VERSION "ZCU_CANFD2"

NS_ :

BS_ :

BU_ :  ETC IHU ZCUD ZCUP

BO_ 441 ZcupZCUCANFD2Fr01 : 64 ZCUP
 SG_ AjarChrgLidRearSwitch : 103|2@0+ (1,0) [0|3] "" IHU,ZCUD
 SG_ AjarChrgLidRearSwitch_UB : 144|1@0+ (1,0) [0|1] "" IHU,ZCUD
 SG_ AjarFuelFlapSwitch : 101|2@0+ (1,0) [0|3] "" IHU,ZCUD
 SG_ AjarFuelFlapSwitch_UB : 147|1@0+ (1,0) [0|1] "" IHU,ZCUD
 SG_ CarTiIntForClima : 175|32@0+ (0.1,0.0) [0.0|429496729.5] "s" IHU,ZCUD
 SG_ CarTiIntForClima_UB : 166|1@0+ (1,0) [0|1] "" IHU,ZCUD
 SG_ ClimaCmptSts : 111|3@0+ (1,0) [0|7] "" IHU,ZCUD
 SG_ ClimaCmptSts_UB : 167|1@0+ (1,0) [0|1] "" IHU,ZCUD
 SG_ ClimaCtrlActv : 233|1@0+ (1,0) [0|1] "" IHU
 SG_ ClimaCtrlActv_UB : 232|1@0+ (1,0) [0|1] "" IHU
 SG_ ClimaDefrstSts : 108|1@0+ (1,0) [0|1] "" IHU,ZCUD
 SG_ ClimaDefrstSts_UB : 107|1@0+ (1,0) [0|1] "" IHU,ZCUD
 SG_ ClimaEstimdTForHeat : 231|13@0- (0.1,0.0) [-256.0|255.9] "degC" IHU
 SG_ ClimaEstimdTForHeat_UB : 234|1@0+ (1,0) [0|1] "" IHU
 SG_ ClimaEstimdTForReHeat : 247|13@0- (0.1,0.0) [-256.0|255.9] "degC" IHU
 SG_ ClimaEstimdTForReHeat_UB : 250|1@0+ (1,0) [0|1] "" IHU
 SG_ CmptmtAirTEstimdAtRowFirstLoResl : 207|11@0+ (0.1,-60.0) [-60.0|125.0] "degC" IHU,ZCUD
 SG_ CmptmtAirTEstimdAtRowFirstLoResl_UB : 106|1@0+ (1,0) [0|1] "" IHU,ZCUD
 SG_ CoupldCtrlErrAtRowFirstLe : 263|13@0- (0.1,0.0) [-256.0|255.9] "degC" IHU
 SG_ CoupldCtrlErrAtRowFirstLe_UB : 266|1@0+ (1,0) [0|1] "" IHU
 SG_ CoupldCtrlErrAtRowFirstRi : 279|13@0- (0.1,0.0) [-256.0|255.9] "degC" IHU
 SG_ CoupldCtrlErrAtRowFirstRi_UB : 282|1@0+ (1,0) [0|1] "" IHU
 SG_ CoupldCtrlErrAtRowSecLe : 295|13@0- (0.1,0.0) [-256.0|255.9] "degC" IHU
 SG_ CoupldCtrlErrAtRowSecLe_UB : 298|1@0+ (1,0) [0|1] "" IHU
 SG_ CoupldCtrlErrAtRowSecRi : 311|13@0- (0.1,0.0) [-256.0|255.9] "degC" IHU
 SG_ CoupldCtrlErrAtRowSecRi_UB : 314|1@0+ (1,0) [0|1] "" IHU
 SG_ DoorPass2Swt1DplyHndl : 249|1@0+ (1,0) [0|1] "" IHU
 SG_ DoorPass2Swt1DplyHndl_UB : 248|1@0+ (1,0) [0|1] "" IHU
 SG_ DoorPass2Swt2DplyHndl : 265|1@0+ (1,0) [0|1] "" IHU
 SG_ DoorPass2Swt2DplyHndl_UB : 264|1@0+ (1,0) [0|1] "" IHU
 SG_ DoorPassLatPosn : 223|2@0+ (1,0) [0|3] "" ZCUD
 SG_ DoorPassLatPosn_UB : 208|1@0+ (1,0) [0|1] "" ZCUD
 SG_ DoorPassRe2Sw1DplyHndl : 219|1@0+ (1,0) [0|1] "" IHU
 SG_ DoorPassRe2Sw1DplyHndl_UB : 218|1@0+ (1,0) [0|1] "" IHU
 SG_ DoorPassRe2Sw2DplyHndl : 217|1@0+ (1,0) [0|1] "" IHU
 SG_ DoorPassRe2Sw2DplyHndl_UB : 216|1@0+ (1,0) [0|1] "" IHU
 SG_ DrvrSeatHeatgPwrAllwd : 23|8@0+ (1.0,0.0) [0.0|255.0] "Unitless" IHU,ZCUD
 SG_ DrvrSeatHeatgPwrAllwd_UB : 145|1@0+ (1,0) [0|1] "" IHU,ZCUD
 SG_ DrvrSeatVentnPwrAllwd : 31|8@0+ (1.0,0.0) [0.0|255.0] "Unitless" IHU,ZCUD
 SG_ DrvrSeatVentnPwrAllwd_UB : 146|1@0+ (1,0) [0|1] "" IHU,ZCUD
 SG_ EngSpdIncIdleForClima : 99|1@0+ (1,0) [0|1] "" IHU,ZCUD
 SG_ EngSpdIncIdleForClima_UB : 152|1@0+ (1,0) [0|1] "" IHU,ZCUD
 SG_ FltOfReRegPlateLamp : 98|1@0+ (1,0) [0|1] "" IHU,ZCUD
 SG_ FltOfReRegPlateLamp_UB : 153|1@0+ (1,0) [0|1] "" IHU,ZCUD
 SG_ FragCh1Id : 39|8@0+ (1.0,0.0) [0.0|255.0] "Unitless" IHU
 SG_ FragCh1Id_UB : 154|1@0+ (1,0) [0|1] "" IHU
 SG_ FragCh2Id : 47|8@0+ (1.0,0.0) [0.0|255.0] "Unitless" IHU
 SG_ FragCh2Id_UB : 155|1@0+ (1,0) [0|1] "" IHU
 SG_ FragCh3Id : 55|8@0+ (1.0,0.0) [0.0|255.0] "Unitless" IHU
 SG_ FragCh3Id_UB : 156|1@0+ (1,0) [0|1] "" IHU
 SG_ FragCh4Id : 63|8@0+ (1.0,0.0) [0.0|255.0] "Unitless" IHU
 SG_ FragCh4Id_UB : 157|1@0+ (1,0) [0|1] "" IHU
 SG_ FragCh5Id : 71|8@0+ (1.0,0.0) [0.0|255.0] "Unitless" IHU
 SG_ FragCh5Id_UB : 158|1@0+ (1,0) [0|1] "" IHU
 SG_ HvEgyDesForClima : 79|8@0+ (50.0,0.0) [0.0|12750.0] "Wh" IHU,ZCUD
 SG_ HvEgyDesForClima_UB : 159|1@0+ (1,0) [0|1] "" IHU,ZCUD
 SG_ IceBreakDoorPassActv : 281|1@0+ (1,0) [0|1] "" IHU
 SG_ IceBreakDoorPassActv_UB : 280|1@0+ (1,0) [0|1] "" IHU
 SG_ MirrAtPassInMovmt : 97|1@0+ (1,0) [0|1] "" IHU
 SG_ MirrAtPassInMovmt_UB : 160|1@0+ (1,0) [0|1] "" IHU
 SG_ PassSeatCushDownPosPerc_UB : 312|1@0+ (1,0) [0|1] "" IHU
 SG_ PassSeatCushDownPosPercSeatPosPerc : 327|10@0+ (0.1,0.0) [0.0|100.0] "%" IHU
 SG_ PassSeatCushDownPosPercSeatPosQf : 333|2@0+ (1,0) [0|3] "" IHU
 SG_ PassSeatFoldFailFb : 331|3@0+ (1.0,0.0) [0.0|7.0] "Unitless" IHU
 SG_ PassSeatFoldFailFb_UB : 328|1@0+ (1,0) [0|1] "" IHU
 SG_ PassSeatPosPerc_UB : 162|1@0+ (1,0) [0|1] "" IHU,ZCUD
 SG_ PassSeatPosPercSeatPosFrntHeiPerc : 119|10@0+ (0.1,0.0) [0.0|100.0] "%" IHU,ZCUD
 SG_ PassSeatPosPercSeatPosFrntHeiQF : 125|2@0+ (1,0) [0|3] "" IHU,ZCUD
 SG_ PassSeatPosPercSeatPosHeiPerc : 121|10@0+ (0.1,0.0) [0.0|100.0] "%" IHU,ZCUD
 SG_ PassSeatPosPercSeatPosHeiQF : 123|2@0+ (1,0) [0|3] "" IHU,ZCUD
 SG_ PassSeatPosPercSeatPosSldPerc : 143|10@0+ (0.1,0.0) [0.0|100.0] "%" IHU,ZCUD
 SG_ PassSeatPosPercSeatPosSldQF : 149|2@0+ (1,0) [0|3] "" IHU,ZCUD
 SG_ SeatBackAngleRowFirstPass : 87|8@0+ (1.0,0.0) [0.0|180.0] "Deg" IHU
 SG_ SeatBackAngleRowFirstPass_UB : 163|1@0+ (1,0) [0|1] "" IHU
 SG_ SeatOccptAtRowSecPasSide2 : 212|2@0+ (1,0) [0|3] "" IHU,ZCUD
 SG_ SeatOccptAtRowSecPasSide2_UB : 105|1@0+ (1,0) [0|1] "" IHU,ZCUD
 SG_ SeatOccptAtRowSecPasSideSnsSts2 : 210|2@0+ (1,0) [0|3] "" IHU,ZCUD
 SG_ SeatOccptAtRowSecPasSideSnsSts2_UB : 104|1@0+ (1,0) [0|1] "" IHU,ZCUD
 SG_ SteerWhlHeatgDurgClima : 96|1@0+ (1,0) [0|1] "" IHU,ZCUD
 SG_ SteerWhlHeatgDurgClima_UB : 164|1@0+ (1,0) [0|1] "" IHU,ZCUD
 SG_ SteerWhlHeatgPwrAllwd : 95|8@0+ (1.0,0.0) [0.0|255.0] "Unitless" IHU,ZCUD
 SG_ SteerWhlHeatgPwrAllwd_UB : 165|1@0+ (1,0) [0|1] "" IHU,ZCUD

BO_ 801 ZcupZCUCANFD2Fr02 : 64 ZCUP
 SG_ AmbTEstimd_UB : 8|1@0+ (1,0) [0|1] "" IHU,ZCUD
 SG_ AmbTEstimdAmbTEstimd : 7|11@0+ (0.1,-70.0) [-70.0|134.70000000000002] "degC" IHU,ZCUD
 SG_ AmbTEstimdQf : 12|1@0+ (1,0) [0|1] "" IHU,ZCUD
 SG_ ClimaOvrHeatPrtSts : 11|1@0+ (1,0) [0|1] "" IHU,ZCUD
 SG_ ClimaOvrHeatPrtSts_UB : 9|1@0+ (1,0) [0|1] "" IHU,ZCUD
 SG_ CmptmtAirTEstimdExtd_UB : 10|1@0+ (1,0) [0|1] "" IHU,ZCUD
 SG_ CmptmtAirTEstimdExtdComptmtT : 23|11@0+ (0.1,-60.0) [-60.0|125.0] "degC" IHU,ZCUD
 SG_ CmptmtAirTEstimdExtdQlyFlg : 28|2@0+ (1,0) [0|3] "" IHU,ZCUD

BO_ 520 ZcupZCUCANFD2Fr03 : 64 ZCUP
 SG_ AmbTRawAtPassSide_UB : 10|1@0+ (1,0) [0|1] "" IHU,ZCUD
 SG_ AmbTRawAtPassSideAmbTVal : 7|11@0+ (0.1,-70.0) [-70.0|134.70000000000002] "degC" IHU,ZCUD
 SG_ AmbTRawAtPassSideQly : 12|2@0+ (1,0) [0|3] "" IHU,ZCUD
 SG_ AmbTURawAtPassSide : 23|12@0+ (0.1,-70.0) [-70.0|339.5] "degC" IHU,ZCUD
 SG_ AmbTURawAtPassSide_UB : 9|1@0+ (1,0) [0|1] "" IHU,ZCUD
 SG_ HvacEvaprTSpFrnt : 39|8@0+ (0.1,-5.0) [-5.0|20.0] "Unitless" IHU,ZCUD
 SG_ HvacEvaprTSpFrnt_UB : 8|1@0+ (1,0) [0|1] "" IHU,ZCUD
 SG_ RlyCmftForClimaReq : 47|1@0+ (1,0) [0|1] "" IHU,ZCUD
 SG_ RlyCmftForClimaReq_UB : 46|1@0+ (1,0) [0|1] "" IHU,ZCUD
 SG_ RlyCrashForClimaReq : 45|1@0+ (1,0) [0|1] "" IHU,ZCUD
 SG_ RlyCrashForClimaReq_UB : 44|1@0+ (1,0) [0|1] "" IHU,ZCUD

BO_ 58 ZcupZCUCANFD2Fr04 : 64 ZCUP
 SG_ DoorPassOpenLowReqOutdSwt1 : 7|2@0+ (1,0) [0|3] "" ZCUD
 SG_ DoorPassOpenLowReqOutdSwt1_UB : 15|1@0+ (1,0) [0|1] "" ZCUD
 SG_ DoorPassOpenReqInsdSwt1 : 5|2@0+ (1,0) [0|3] "" ZCUD
 SG_ DoorPassOpenReqInsdSwt1_UB : 14|1@0+ (1,0) [0|1] "" ZCUD
 SG_ DoorPassReCinhIntFailInf_UB : 13|1@0+ (1,0) [0|1] "" ZCUD
 SG_ DoorPassReCinhIntFailInfCinchFlt1 : 3|1@0+ (1,0) [0|1] "" ZCUD
 SG_ DoorPassReCinhIntFailInfCinchRestFlt : 2|1@0+ (1,0) [0|1] "" ZCUD
 SG_ DoorPassReLatPosn : 1|2@0+ (1,0) [0|3] "" ZCUD
 SG_ DoorPassReLatPosn_UB : 12|1@0+ (1,0) [0|1] "" ZCUD
 SG_ DoorPassReOpenLowReqOutdSwt1 : 23|2@0+ (1,0) [0|3] "" ZCUD
 SG_ DoorPassReOpenLowReqOutdSwt1_UB : 11|1@0+ (1,0) [0|1] "" ZCUD
 SG_ DoorPassReOpenReqInsdSwt1 : 21|2@0+ (1,0) [0|3] "" ZCUD
 SG_ DoorPassReOpenReqInsdSwt1_UB : 10|1@0+ (1,0) [0|1] "" ZCUD
 SG_ DoorPassReRelsFail_UB : 28|1@0+ (1,0) [0|1] "" ZCUD
 SG_ DoorPassReRelsFailCinchOverTimed : 31|1@0+ (1,0) [0|1] "" ZCUD
 SG_ DoorPassReRelsFailFailure1 : 30|1@0+ (1,0) [0|1] "" ZCUD
 SG_ DoorPassReRelsFailMechRels : 29|1@0+ (1,0) [0|1] "" ZCUD
 SG_ DoorRiReLatPosn : 19|2@0+ (1,0) [0|3] "" ZCUD
 SG_ DoorRiReLatPosn_UB : 9|1@0+ (1,0) [0|1] "" ZCUD
 SG_ DoorRiReOpenLowReqOutdSwt1 : 17|2@0+ (1,0) [0|3] "" ZCUD
 SG_ DoorRiReOpenLowReqOutdSwt1_UB : 8|1@0+ (1,0) [0|1] "" ZCUD
 SG_ DoorRiReOpenReqInsdSwt1 : 27|2@0+ (1,0) [0|3] "" ZCUD
 SG_ DoorRiReOpenReqInsdSwt1_UB : 25|1@0+ (1,0) [0|1] "" ZCUD
 SG_ IceBreakDoorPassReActv : 39|1@0+ (1,0) [0|1] "" ZCUD
 SG_ IceBreakDoorPassReActv_UB : 24|1@0+ (1,0) [0|1] "" ZCUD

BO_ 310 ZcupZCUCANFD2Fr05 : 64 ZCUP
 SG_ AutDemstOperSts : 35|1@0+ (1,0) [0|1] "" IHU
 SG_ AutDemstOperSts_UB : 56|1@0+ (1,0) [0|1] "" IHU
 SG_ ChdLockPassReSts : 39|2@0+ (1,0) [0|3] "" IHU,ZCUD
 SG_ ChdLockPassReSts_UB : 57|1@0+ (1,0) [0|1] "" IHU,ZCUD
 SG_ ChdLockRightSts : 37|2@0+ (1,0) [0|3] "" IHU,ZCUD
 SG_ ChdLockRightSts_UB : 58|1@0+ (1,0) [0|1] "" IHU,ZCUD
 SG_ ChrgLidDCorAcDctSwtReq : 34|1@0+ (1,0) [0|1] "" IHU,ZCUD
 SG_ ChrgLidDCorAcDctSwtReq_UB : 59|1@0+ (1,0) [0|1] "" IHU,ZCUD
 SG_ CinhPassReSts : 211|1@0+ (1,0) [0|1] "" ZCUD
 SG_ CinhPassReSts_UB : 210|1@0+ (1,0) [0|1] "" ZCUD
 SG_ CinhPassReSwt : 209|1@0+ (1,0) [0|1] "" ZCUD
 SG_ CinhPassReSwt_UB : 208|1@0+ (1,0) [0|1] "" ZCUD
 SG_ CinhPassSts : 111|1@0+ (1,0) [0|1] "" ZCUD
 SG_ CinhPassSts_UB : 110|1@0+ (1,0) [0|1] "" ZCUD
 SG_ CinhPassSwt : 234|1@0+ (1,0) [0|1] "" ZCUD
 SG_ CinhPassSwt_UB : 233|1@0+ (1,0) [0|1] "" ZCUD
 SG_ ClimaTiOfEnd : 7|32@0+ (0.1,0.0) [0.0|429496729.5] "s" IHU,ZCUD
 SG_ ClimaTiOfEnd_UB : 60|1@0+ (1,0) [0|1] "" IHU,ZCUD
 SG_ CmptmtTFrnt_UB : 72|1@0+ (1,0) [0|1] "" IHU,ZCUD
 SG_ CmptmtTFrntCmptmtTFrnt : 71|11@0+ (0.1,-60.0) [-60.0|125.0] "degC" IHU,ZCUD
 SG_ CmptmtTFrntFanForCmptmtTRunng : 76|1@0+ (1,0) [0|1] "" IHU,ZCUD
 SG_ CmptmtTFrntQf : 75|2@0+ (1,0) [0|3] "" IHU,ZCUD
 SG_ DoorPassReHndlSts : 47|3@0+ (1,0) [0|7] "" IHU,ZCUD
 SG_ DoorPassReHndlSts_UB : 73|1@0+ (1,0) [0|1] "" IHU,ZCUD
 SG_ EvaprTFrnt_UB : 225|1@0+ (1,0) [0|1] "" IHU,ZCUD
 SG_ EvaprTFrntEvaprTFrnt : 223|13@0- (0.1,0.0) [-256.0|255.9] "degC" IHU,ZCUD
 SG_ EvaprTFrntEvaprTQf : 226|1@0+ (1,0) [0|1] "" IHU,ZCUD
 SG_ FltOfBeamHiPass : 33|1@0+ (1,0) [0|1] "" IHU,ZCUD
 SG_ FltOfBeamHiPass_UB : 88|1@0+ (1,0) [0|1] "" IHU,ZCUD
 SG_ FltOfBeamLoPass : 32|1@0+ (1,0) [0|1] "" IHU,ZCUD
 SG_ FltOfBeamLoPass_UB : 89|1@0+ (1,0) [0|1] "" IHU,ZCUD
 SG_ FltOfDaytiRunngLampPass : 44|1@0+ (1,0) [0|1] "" IHU,ZCUD
 SG_ FltOfDaytiRunngLampPass_UB : 96|1@0+ (1,0) [0|1] "" IHU,ZCUD
 SG_ FltOfFrntFogLampPass : 43|1@0+ (1,0) [0|1] "" IHU,ZCUD
 SG_ FltOfFrntFogLampPass_UB : 97|1@0+ (1,0) [0|1] "" IHU,ZCUD
 SG_ FltOfFrntPosnLampPass : 42|1@0+ (1,0) [0|1] "" IHU,ZCUD
 SG_ FltOfFrntPosnLampPass_UB : 98|1@0+ (1,0) [0|1] "" IHU,ZCUD
 SG_ FltOfReFogLampDrv : 41|1@0+ (1,0) [0|1] "" IHU,ZCUD
 SG_ FltOfReFogLampDrv_UB : 99|1@0+ (1,0) [0|1] "" IHU,ZCUD
 SG_ FltOfRePosnLampPass : 40|1@0+ (1,0) [0|1] "" IHU,ZCUD
 SG_ FltOfRePosnLampPass_UB : 100|1@0+ (1,0) [0|1] "" IHU,ZCUD
 SG_ FltOfRvsgLampPass : 50|1@0+ (1,0) [0|1] "" IHU,ZCUD
 SG_ FltOfRvsgLampPass_UB : 101|1@0+ (1,0) [0|1] "" IHU,ZCUD
 SG_ HvacCoolgEnaRe : 49|1@0+ (1,0) [0|1] "" IHU,ZCUD
 SG_ HvacCoolgEnaRe_UB : 102|1@0+ (1,0) [0|1] "" IHU,ZCUD
 SG_ HvahAirTEstmd_UB : 103|1@0+ (1,0) [0|1] "" IHU,ZCUD
 SG_ HvahAirTEstmdEvaprTFrnt : 87|13@0- (0.1,0.0) [-256.0|255.9] "degC" IHU,ZCUD
 SG_ HvahAirTEstmdEvaprTQf : 90|1@0+ (1,0) [0|1] "" IHU,ZCUD
 SG_ IceBreakDoorRiReActv : 224|1@0+ (1,0) [0|1] "" ZCUD
 SG_ IceBreakDoorRiReActv_UB : 239|1@0+ (1,0) [0|1] "" ZCUD
 SG_ IntPm25StsFrmClima : 52|2@0+ (1,0) [0|3] "" IHU
 SG_ IntPm25StsFrmClima_UB : 104|1@0+ (1,0) [0|1] "" IHU
 SG_ MirrDwnStsAtPass : 55|3@0+ (1,0) [0|7] "" IHU,ZCUD
 SG_ MirrDwnStsAtPass_UB : 105|1@0+ (1,0) [0|1] "" IHU,ZCUD
 SG_ MirrPosnToSetTarPosnAtPass_UB : 109|1@0+ (1,0) [0|1] "" IHU
 SG_ MirrPosnToSetTarPosnAtPassMirrPosnAdjCldLeRi : 119|8@0+ (1.0,0.0) [0.0|180.0] "Deg" IHU
 SG_ MirrPosnToSetTarPosnAtPassMirrPosnAdjCldUpDwn : 127|8@0+ (1.0,0.0) [0.0|180.0] "Deg" IHU
 SG_ OpenPassReSwt : 242|1@0+ (1,0) [0|1] "" ZCUD
 SG_ OpenPassReSwt_UB : 241|1@0+ (1,0) [0|1] "" ZCUD
 SG_ OpenPassSwt : 240|1@0+ (1,0) [0|1] "" ZCUD
 SG_ OpenPassSwt_UB : 255|1@0+ (1,0) [0|1] "" ZCUD
 SG_ PassSeatBtnPsd : 48|1@0+ (1,0) [0|1] "" IHU
 SG_ PassSeatBtnPsd_UB : 106|1@0+ (1,0) [0|1] "" IHU
 SG_ PassSeatFoldSts : 270|3@0+ (1,0) [0|7] "" IHU,ZCUD
 SG_ PassSeatFoldSts_UB : 267|1@0+ (1,0) [0|1] "" IHU,ZCUD
 SG_ PassSeatInAutMovmt : 61|1@0+ (1,0) [0|1] "" IHU,ZCUD
 SG_ PassSeatInAutMovmt_UB : 107|1@0+ (1,0) [0|1] "" IHU,ZCUD
 SG_ PassSeatPosFrntExtPerc_UB : 252|1@0+ (1,0) [0|1] "" IHU
 SG_ PassSeatPosFrntExtPercSeatPosPerc : 249|10@0+ (0.1,0.0) [0.0|100.0] "%" IHU
 SG_ PassSeatPosFrntExtPercSeatPosQf : 251|2@0+ (1,0) [0|3] "" IHU
 SG_ PawlPassReSwt : 238|1@0+ (1,0) [0|1] "" ZCUD
 SG_ PawlPassReSwt_UB : 237|1@0+ (1,0) [0|1] "" ZCUD
 SG_ PawlPassSwt : 236|1@0+ (1,0) [0|1] "" ZCUD
 SG_ PawlPassSwt_UB : 235|1@0+ (1,0) [0|1] "" ZCUD
 SG_ SecRowLeSeatHeatgPwrAllwd : 135|8@0+ (1.0,0.0) [0.0|255.0] "Unitless" ZCUD
 SG_ SecRowLeSeatHeatgPwrAllwd_UB : 199|1@0+ (1,0) [0|1] "" ZCUD
 SG_ SecRowLeSeatVentnPwrAllwd : 143|8@0+ (1.0,0.0) [0.0|255.0] "Unitless" ZCUD
 SG_ SecRowLeSeatVentnPwrAllwd_UB : 198|1@0+ (1,0) [0|1] "" ZCUD
 SG_ SecRowRiSeatHeatgPwrAllwd : 151|8@0+ (1.0,0.0) [0.0|255.0] "Unitless" ZCUD
 SG_ SecRowRiSeatHeatgPwrAllwd_UB : 197|1@0+ (1,0) [0|1] "" ZCUD
 SG_ SecRowRiSeatVentnPwrAllwd : 159|8@0+ (1.0,0.0) [0.0|255.0] "Unitless" ZCUD
 SG_ SecRowRiSeatVentnPwrAllwd_UB : 196|1@0+ (1,0) [0|1] "" ZCUD
 SG_ ShortDropWinPassSts : 247|2@0+ (1,0) [0|3] "" ZCUD
 SG_ ShortDropWinPassSts_UB : 232|1@0+ (1,0) [0|1] "" ZCUD
 SG_ ShortDropWinReRiSts : 245|2@0+ (1,0) [0|3] "" ZCUD
 SG_ ShortDropWinReRiSts_UB : 243|1@0+ (1,0) [0|1] "" ZCUD
 SG_ ThrdRowLeSeatHeatgPwrAllwd : 167|8@0+ (1.0,0.0) [0.0|255.0] "Unitless" ZCUD
 SG_ ThrdRowLeSeatHeatgPwrAllwd_UB : 195|1@0+ (1,0) [0|1] "" ZCUD
 SG_ ThrdRowLeSeatVentnPwrAllwd : 175|8@0+ (1.0,0.0) [0.0|255.0] "Unitless" ZCUD
 SG_ ThrdRowLeSeatVentnPwrAllwd_UB : 194|1@0+ (1,0) [0|1] "" ZCUD
 SG_ ThrdRowRiSeatHeatgPwrAllwd : 183|8@0+ (1.0,0.0) [0.0|255.0] "Unitless" ZCUD
 SG_ ThrdRowRiSeatHeatgPwrAllwd_UB : 193|1@0+ (1,0) [0|1] "" ZCUD
 SG_ ThrdRowRiSeatVentnPwrAllwd : 191|8@0+ (1.0,0.0) [0.0|255.0] "Unitless" ZCUD
 SG_ ThrdRowRiSeatVentnPwrAllwd_UB : 192|1@0+ (1,0) [0|1] "" ZCUD
 SG_ WinDsblPassReSts : 201|1@0+ (1,0) [0|1] "" IHU,ZCUD
 SG_ WinDsblPassReSts_UB : 200|1@0+ (1,0) [0|1] "" IHU,ZCUD
 SG_ WinDsblRightSts : 215|1@0+ (1,0) [0|1] "" IHU,ZCUD
 SG_ WinDsblRightSts_UB : 214|1@0+ (1,0) [0|1] "" IHU,ZCUD
 SG_ WinFailrStsAtPassRe : 213|1@0+ (1,0) [0|1] "" IHU,ZCUD
 SG_ WinFailrStsAtPassRe_UB : 212|1@0+ (1,0) [0|1] "" IHU,ZCUD
 SG_ WinPosnStsAtPassRe : 207|5@0+ (1,0) [0|31] "" IHU,ZCUD
 SG_ WinPosnStsAtPassRe_UB : 202|1@0+ (1,0) [0|1] "" IHU,ZCUD

BO_ 1184 ZcupZCUCANFD2Fr06 : 64 ZCUP
 SG_ CmptmtIntrMtrlTEstimd_UB : 252|1@0+ (1,0) [0|1] "" IHU
 SG_ CmptmtIntrMtrlTEstimdMtrlSnsrT : 127|13@0- (0.1,0.0) [-256.0|255.9] "degC" IHU
 SG_ CmptmtIntrMtrlTEstimdMtrlSnsrTQly2 : 130|2@0+ (1,0) [0|3] "" IHU
 SG_ EgyDesForClima : 103|7@0+ (1.0,0.0) [0.0|127.0] "Wh" IHU,ZCUD
 SG_ EgyDesForClima_UB : 96|1@0+ (1,0) [0|1] "" IHU,ZCUD
 SG_ ElecVentnMotPwrCnsAct : 199|10@0+ (0.1,0.0) [0.0|102.30000000000001] "W" IHU
 SG_ ElecVentnMotPwrCnsAct_UB : 253|1@0+ (1,0) [0|1] "" IHU
 SG_ ElecVentnMotPwrCnsDes : 247|10@0+ (0.1,0.0) [0.0|102.30000000000001] "W" IHU
 SG_ ElecVentnMotPwrCnsDes_UB : 274|1@0+ (1,0) [0|1] "" IHU
 SG_ HvacDefrstFlapActlPosn : 249|10@0+ (0.1,0.0) [0.0|100.0] "%" IHU
 SG_ HvacDefrstFlapActlPosn_UB : 275|1@0+ (1,0) [0|1] "" IHU
 SG_ HvacFanSet2HvacFanSpd2 : 39|8@0+ (1.0,0.0) [0.0|255.0] "Unitless" IHU
 SG_ HvacFanSet2HvacFanSpd2_UB : 276|1@0+ (1,0) [0|1] "" IHU
 SG_ HvacHeatElmAirMFlowEstimd : 271|10@0+ (1.0,0.0) [0.0|1000.0] "Kg / h" IHU,ZCUD
 SG_ HvacHeatElmAirMFlowEstimd_UB : 277|1@0+ (1,0) [0|1] "" IHU,ZCUD
 SG_ HvacModFlapActlPosnFrstRowLe : 153|10@0+ (0.1,0.0) [0.0|100.0] "%" IHU
 SG_ HvacModFlapActlPosnFrstRowLe_UB : 299|1@0+ (1,0) [0|1] "" IHU
 SG_ HvacModFlapActlPosnFrstRowRi : 273|10@0+ (0.1,0.0) [0.0|100.0] "%" IHU
 SG_ HvacModFlapActlPosnFrstRowRi_UB : 300|1@0+ (1,0) [0|1] "" IHU
 SG_ HvacModFlapActlPosnSecRowLe : 295|10@0+ (0.1,0.0) [0.0|100.0] "%" IHU
 SG_ HvacModFlapActlPosnSecRowLe_UB : 301|1@0+ (1,0) [0|1] "" IHU
 SG_ HvacModFlapActlPosnSecRowRi : 297|10@0+ (0.1,0.0) [0.0|100.0] "%" IHU
 SG_ HvacModFlapActlPosnSecRowRi_UB : 322|1@0+ (1,0) [0|1] "" IHU
 SG_ HvacOsaFlapActlPosn : 319|10@0+ (0.1,0.0) [0.0|100.0] "%" IHU
 SG_ HvacOsaFlapActlPosn_UB : 325|1@0+ (1,0) [0|1] "" IHU
 SG_ HvacRecFlapActlPosn : 321|10@0+ (0.1,0.0) [0.0|100.0] "%" IHU
 SG_ HvacRecFlapActlPosn_UB : 323|1@0+ (1,0) [0|1] "" IHU
 SG_ OutdAirQly_UB : 324|1@0+ (1,0) [0|1] "" IHU
 SG_ OutdAirQlyOutdAirQly : 95|2@0+ (1,0) [0|3] "" IHU
 SG_ OutdAirQlyQf : 93|1@0+ (1,0) [0|1] "" IHU
 SG_ OutdPm25StsFrmClima : 89|2@0+ (1,0) [0|3] "" IHU
 SG_ OutdPm25StsFrmClima_UB : 336|1@0+ (1,0) [0|1] "" IHU
 SG_ PassSeatHeatgActlPwrCns : 47|8@0+ (1.0,0.0) [0.0|255.0] "Unitless" IHU
 SG_ PassSeatHeatgActlPwrCns_UB : 338|1@0+ (1,0) [0|1] "" IHU
 SG_ PassSeatHeatgDesPwrCns : 55|8@0+ (1.0,0.0) [0.0|255.0] "Unitless" IHU
 SG_ PassSeatHeatgDesPwrCns_UB : 339|1@0+ (1,0) [0|1] "" IHU
 SG_ PassSeatHeatgPwrAllwd : 63|8@0+ (1.0,0.0) [0.0|255.0] "Unitless" IHU
 SG_ PassSeatHeatgPwrAllwd_UB : 340|1@0+ (1,0) [0|1] "" IHU
 SG_ PassSeatVentnActlPwrCns : 71|8@0+ (1.0,0.0) [0.0|255.0] "Unitless" IHU
 SG_ PassSeatVentnActlPwrCns_UB : 341|1@0+ (1,0) [0|1] "" IHU
 SG_ PassSeatVentnDesPwrCns : 79|8@0+ (1.0,0.0) [0.0|255.0] "Unitless" IHU
 SG_ PassSeatVentnDesPwrCns_UB : 342|1@0+ (1,0) [0|1] "" IHU
 SG_ PassSeatVentnPwrAllwd : 87|8@0+ (1.0,0.0) [0.0|255.0] "Unitless" IHU
 SG_ PassSeatVentnPwrAllwd_UB : 343|1@0+ (1,0) [0|1] "" IHU
 SG_ PwrAllwdForElecAirVentn : 223|10@0+ (0.1,0.0) [0.0|102.30000000000001] "W" IHU
 SG_ PwrAllwdForElecAirVentn_UB : 344|1@0+ (1,0) [0|1] "" IHU
 SG_ SunDataAzi : 128|9@0+ (1.0,0.0) [0.0|511.0] "Unitless" IHU
 SG_ SunDataAzi_UB : 345|1@0+ (1,0) [0|1] "" IHU
 SG_ SunDataElevn : 178|11@0+ (0.1,-90.0) [-90.0|90.0] "Deg" IHU
 SG_ SunDataElevn_UB : 346|1@0+ (1,0) [0|1] "" IHU
 SG_ TgtHvacAirTForRowFirstLe : 111|13@0- (0.1,0.0) [-256.0|255.9] "degC" IHU
 SG_ TgtHvacAirTForRowFirstLe_UB : 347|1@0+ (1,0) [0|1] "" IHU
 SG_ TgtHvacAirTForRowFirstRi : 175|13@0- (0.1,0.0) [-256.0|255.9] "degC" IHU
 SG_ TgtHvacAirTForRowFirstRi_UB : 348|1@0+ (1,0) [0|1] "" IHU
 SG_ TgtHvacAirTForRowSecLe : 204|13@0- (0.1,0.0) [-256.0|255.9] "degC" IHU
 SG_ TgtHvacAirTForRowSecLe_UB : 205|1@0+ (1,0) [0|1] "" IHU
 SG_ TgtHvacAirTForRowSecRi : 228|13@0- (0.1,0.0) [-256.0|255.9] "degC" IHU
 SG_ TgtHvacAirTForRowSecRi_UB : 229|1@0+ (1,0) [0|1] "" IHU

BO_ 600 ZcupZCUCANFD2Fr07 : 64 ZCUP
 SG_ CcmElecAirDirCrtlReqDrvrLePosX : 23|8@0+ (1.0,0.0) [0.0|255.0] "Unitless" IHU
 SG_ CcmElecAirDirCrtlReqDrvrLePosX_UB : 144|1@0+ (1,0) [0|1] "" IHU
 SG_ CcmElecAirDirCrtlReqDrvrLePosY : 31|8@0+ (1.0,0.0) [0.0|255.0] "Unitless" IHU
 SG_ CcmElecAirDirCrtlReqDrvrLePosY_UB : 145|1@0+ (1,0) [0|1] "" IHU
 SG_ CcmElecAirDirCrtlReqDrvrRiPosX : 39|8@0+ (1.0,0.0) [0.0|255.0] "Unitless" IHU
 SG_ CcmElecAirDirCrtlReqDrvrRiPosX_UB : 146|1@0+ (1,0) [0|1] "" IHU
 SG_ CcmElecAirDirCrtlReqDrvrRiPosY : 47|8@0+ (1.0,0.0) [0.0|255.0] "Unitless" IHU
 SG_ CcmElecAirDirCrtlReqDrvrRiPosY_UB : 147|1@0+ (1,0) [0|1] "" IHU
 SG_ CcmElecAirDirCrtlReqPassLePosX : 55|8@0+ (1.0,0.0) [0.0|255.0] "Unitless" IHU
 SG_ CcmElecAirDirCrtlReqPassLePosX_UB : 148|1@0+ (1,0) [0|1] "" IHU
 SG_ CcmElecAirDirCrtlReqPassLePosY : 63|8@0+ (1.0,0.0) [0.0|255.0] "Unitless" IHU
 SG_ CcmElecAirDirCrtlReqPassLePosY_UB : 152|1@0+ (1,0) [0|1] "" IHU
 SG_ CcmElecAirDirCrtlReqPassRiPosX : 71|8@0+ (1.0,0.0) [0.0|255.0] "Unitless" IHU
 SG_ CcmElecAirDirCrtlReqPassRiPosX_UB : 153|1@0+ (1,0) [0|1] "" IHU
 SG_ CcmElecAirDirCrtlReqPassRiPosY : 79|8@0+ (1.0,0.0) [0.0|255.0] "Unitless" IHU
 SG_ CcmElecAirDirCrtlReqPassRiPosY_UB : 154|1@0+ (1,0) [0|1] "" IHU
 SG_ ClimaActv : 89|1@0+ (1,0) [0|1] "" IHU,ZCUD
 SG_ ClimaActv_UB : 155|1@0+ (1,0) [0|1] "" IHU,ZCUD
 SG_ ElecAirVentnAvlSts : 95|3@0+ (1,0) [0|7] "" IHU
 SG_ ElecAirVentnAvlSts_UB : 157|1@0+ (1,0) [0|1] "" IHU
 SG_ ElecDefrstReq_UB : 158|1@0+ (1,0) [0|1] "" IHU,ZCUD
 SG_ ElecDefrstReqMirrDefrstReq : 92|1@0+ (1,0) [0|1] "" IHU,ZCUD
 SG_ ElecDefrstReqWinDefrstFrntReq : 91|1@0+ (1,0) [0|1] "" IHU,ZCUD
 SG_ ElecDefrstReqWinDefrstReReq : 90|1@0+ (1,0) [0|1] "" IHU,ZCUD
 SG_ EvaprTRe_UB : 159|1@0+ (1,0) [0|1] "" IHU,ZCUD
 SG_ EvaprTReEvaprTFrnt : 103|13@0- (0.1,0.0) [-256.0|255.9] "degC" IHU,ZCUD
 SG_ EvaprTReEvaprTQf : 106|1@0+ (1,0) [0|1] "" IHU,ZCUD
 SG_ FragCh1UseUpWrn : 105|1@0+ (1,0) [0|1] "" IHU
 SG_ FragCh1UseUpWrn_UB : 160|1@0+ (1,0) [0|1] "" IHU
 SG_ FragCh2UseUpWrn : 104|1@0+ (1,0) [0|1] "" IHU
 SG_ FragCh2UseUpWrn_UB : 161|1@0+ (1,0) [0|1] "" IHU
 SG_ FragCh3UseUpWrn : 120|1@0+ (1,0) [0|1] "" IHU
 SG_ FragCh3UseUpWrn_UB : 162|1@0+ (1,0) [0|1] "" IHU
 SG_ FragCh4UseUpWrn : 129|1@0+ (1,0) [0|1] "" IHU
 SG_ FragCh4UseUpWrn_UB : 163|1@0+ (1,0) [0|1] "" IHU
 SG_ FragCh5UseUpWrn : 128|1@0+ (1,0) [0|1] "" IHU
 SG_ FragCh5UseUpWrn_UB : 164|1@0+ (1,0) [0|1] "" IHU
 SG_ FragLvlFrmClima : 135|2@0+ (1,0) [0|3] "" IHU
 SG_ FragLvlFrmClima_UB : 165|1@0+ (1,0) [0|1] "" IHU
 SG_ FragStsFrmClima : 133|2@0+ (1,0) [0|3] "" IHU
 SG_ FragStsFrmClima_UB : 166|1@0+ (1,0) [0|1] "" IHU
 SG_ HvacEvaprTSpRe : 87|8@0+ (0.1,-5.0) [-5.0|20.0] "Unitless" IHU,ZCUD
 SG_ HvacEvaprTSpRe_UB : 167|1@0+ (1,0) [0|1] "" IHU,ZCUD
 SG_ IntPm25HiPopUp : 131|2@0+ (1,0) [0|3] "" IHU
 SG_ IntPm25HiPopUp_UB : 168|1@0+ (1,0) [0|1] "" IHU
 SG_ PassSeatVentAvlSts : 151|3@0+ (1,0) [0|7] "" IHU
 SG_ PassSeatVentAvlSts_UB : 171|1@0+ (1,0) [0|1] "" IHU
 SG_ PrkgClimaWarn : 124|4@0+ (1,0) [0|15] "" IHU
 SG_ PrkgClimaWarn_UB : 173|1@0+ (1,0) [0|1] "" IHU
 SG_ SeatClimaDurgClima_UB : 137|1@0+ (1,0) [0|1] "" IHU,ZCUD
 SG_ SeatClimaDurgClimaHmiSeatHeatgForRowFirstLe : 7|2@0+ (1,0) [0|3] "" IHU,ZCUD
 SG_ SeatClimaDurgClimaHmiSeatHeatgForRowFirstRi : 5|2@0+ (1,0) [0|3] "" IHU,ZCUD
 SG_ SeatClimaDurgClimaHmiSeatHeatgForRowSecLe : 3|2@0+ (1,0) [0|3] "" IHU,ZCUD
 SG_ SeatClimaDurgClimaHmiSeatHeatgForRowSecRi : 1|2@0+ (1,0) [0|3] "" IHU,ZCUD
 SG_ SeatClimaDurgClimaHmiSeatVentnForRowFirstLe : 15|2@0+ (1,0) [0|3] "" IHU,ZCUD
 SG_ SeatClimaDurgClimaHmiSeatVentnForRowFirstRi : 13|2@0+ (1,0) [0|3] "" IHU,ZCUD
 SG_ SeatClimaDurgClimaHmiSeatVentnForRowSecLe : 11|2@0+ (1,0) [0|3] "" IHU,ZCUD
 SG_ SeatClimaDurgClimaHmiSeatVentnForRowSecRi : 9|2@0+ (1,0) [0|3] "" IHU,ZCUD

BO_ 803 ZcupZCUCANFD2Fr08 : 64 ZCUP
 SG_ CcmRollgCntrSts : 39|8@0+ (1.0,0.0) [0.0|255.0] "Unitless" IHU,ZCUD
 SG_ CcmRollgCntrSts_UB : 138|1@0+ (1,0) [0|1] "" IHU,ZCUD
 SG_ ClimaCoolgReqLvl : 196|2@0+ (1,0) [0|3] "" IHU,ZCUD
 SG_ ClimaCoolgReqLvl_UB : 190|1@0+ (1,0) [0|1] "" IHU,ZCUD
 SG_ ClimaHeatgReqLvl : 194|2@0+ (1,0) [0|3] "" IHU,ZCUD
 SG_ ClimaHeatgReqLvl_UB : 192|1@0+ (1,0) [0|1] "" IHU,ZCUD
 SG_ CmptModForHp : 205|3@0+ (1,0) [0|7] "" IHU,ZCUD
 SG_ CmptModForHp_UB : 202|1@0+ (1,0) [0|1] "" IHU,ZCUD
 SG_ CmptmtTRe_UB : 140|1@0+ (1,0) [0|1] "" IHU,ZCUD
 SG_ CmptmtTReCmptmtTFrnt : 71|11@0+ (0.1,-60.0) [-60.0|125.0] "degC" IHU,ZCUD
 SG_ CmptmtTReCmptmtTFrntQf : 76|2@0+ (1,0) [0|3] "" IHU,ZCUD
 SG_ CmptmtTReFanForCmptmtTRunng : 74|1@0+ (1,0) [0|1] "" IHU,ZCUD
 SG_ DvlpFrameForCCM_UB : 200|1@0+ (1,0) [0|1] "" IHU,ZCUD
 SG_ DvlpFrameForCCMByte0 : 215|8@0+ (1.0,0.0) [0.0|255.0] "Unitless" IHU,ZCUD
 SG_ DvlpFrameForCCMByte1 : 223|8@0+ (1.0,0.0) [0.0|255.0] "Unitless" IHU,ZCUD
 SG_ DvlpFrameForCCMByte2 : 231|8@0+ (1.0,0.0) [0.0|255.0] "Unitless" IHU,ZCUD
 SG_ DvlpFrameForCCMByte3 : 239|8@0+ (1.0,0.0) [0.0|255.0] "Unitless" IHU,ZCUD
 SG_ DvlpFrameForCCMByte4 : 247|8@0+ (1.0,0.0) [0.0|255.0] "Unitless" IHU,ZCUD
 SG_ DvlpFrameForCCMByte5 : 255|8@0+ (1.0,0.0) [0.0|255.0] "Unitless" IHU,ZCUD
 SG_ DvlpFrameForCCMByte6 : 263|8@0+ (1.0,0.0) [0.0|255.0] "Unitless" IHU,ZCUD
 SG_ DvlpFrameForCCMByte7 : 271|8@0+ (1.0,0.0) [0.0|255.0] "Unitless" IHU,ZCUD
 SG_ FrntHvacBlowerSts : 279|2@0+ (1,0) [0|3] "" IHU,ZCUD
 SG_ FrntHvacBlowerSts_UB : 201|1@0+ (1,0) [0|1] "" IHU,ZCUD
 SG_ HeatrAirTReq : 88|9@0+ (0.5,-60.0) [-60.0|195.5] "Unitless" IHU,ZCUD
 SG_ HeatrAirTReq_UB : 141|1@0+ (1,0) [0|1] "" IHU,ZCUD
 SG_ HpReqCritSts : 277|1@0+ (1,0) [0|1] "" IHU,ZCUD
 SG_ HpReqCritSts_UB : 276|1@0+ (1,0) [0|1] "" IHU,ZCUD
 SG_ HvacAirMFlowEstimd : 273|10@0+ (1.0,0.0) [0.0|1000.0] "Kg / h" IHU,ZCUD
 SG_ HvacAirMFlowEstimd_UB : 274|1@0+ (1,0) [0|1] "" IHU,ZCUD
 SG_ HvacAirMFlowReEstimd : 113|10@0+ (1.0,0.0) [0.0|1000.0] "Kg / h" IHU,ZCUD
 SG_ HvacAirMFlowReEstimd_UB : 162|1@0+ (1,0) [0|1] "" IHU,ZCUD
 SG_ HvacAirTForRowFirstAtFlrLe_UB : 275|1@0+ (1,0) [0|1] "" IHU,ZCUD
 SG_ HvacAirTForRowFirstAtFlrLeEvaprTFrnt : 292|13@0- (0.1,0.0) [-256.0|255.9] "degC" IHU,ZCUD
 SG_ HvacAirTForRowFirstAtFlrLeEvaprTQf : 293|1@0+ (1,0) [0|1] "" IHU,ZCUD
 SG_ HvacAirTForRowFirstAtFlrRi_UB : 310|1@0+ (1,0) [0|1] "" IHU,ZCUD
 SG_ HvacAirTForRowFirstAtFlrRiEvaprTFrnt : 308|13@0- (0.1,0.0) [-256.0|255.9] "degC" IHU,ZCUD
 SG_ HvacAirTForRowFirstAtFlrRiEvaprTQf : 309|1@0+ (1,0) [0|1] "" IHU,ZCUD
 SG_ HvacAirTForRowFirstAtVentLe_UB : 326|1@0+ (1,0) [0|1] "" IHU,ZCUD
 SG_ HvacAirTForRowFirstAtVentLeEvaprTFrnt : 324|13@0- (0.1,0.0) [-256.0|255.9] "degC" IHU,ZCUD
 SG_ HvacAirTForRowFirstAtVentLeEvaprTQf : 325|1@0+ (1,0) [0|1] "" IHU,ZCUD
 SG_ HvacAirTForRowFirstAtVentRi_UB : 311|1@0+ (1,0) [0|1] "" IHU,ZCUD
 SG_ HvacAirTForRowFirstAtVentRiEvaprTFrnt : 340|13@0- (0.1,0.0) [-256.0|255.9] "degC" IHU,ZCUD
 SG_ HvacAirTForRowFirstAtVentRiEvaprTQf : 341|1@0+ (1,0) [0|1] "" IHU,ZCUD
 SG_ HvacAirTForRowSecAtFlrLe_UB : 327|1@0+ (1,0) [0|1] "" IHU,ZCUD
 SG_ HvacAirTForRowSecAtFlrLeEvaprTFrnt : 356|13@0- (0.1,0.0) [-256.0|255.9] "degC" IHU,ZCUD
 SG_ HvacAirTForRowSecAtFlrLeEvaprTQf : 357|1@0+ (1,0) [0|1] "" IHU,ZCUD
 SG_ HvacAirTForRowSecAtFlrRi_UB : 294|1@0+ (1,0) [0|1] "" IHU,ZCUD
 SG_ HvacAirTForRowSecAtFlrRiEvaprTFrnt : 372|13@0- (0.1,0.0) [-256.0|255.9] "degC" IHU,ZCUD
 SG_ HvacAirTForRowSecAtFlrRiEvaprTQf : 373|1@0+ (1,0) [0|1] "" IHU,ZCUD
 SG_ HvacAirTForRowSecAtVentLe_UB : 295|1@0+ (1,0) [0|1] "" IHU,ZCUD
 SG_ HvacAirTForRowSecAtVentLeEvaprTFrnt : 388|13@0- (0.1,0.0) [-256.0|255.9] "degC" IHU,ZCUD
 SG_ HvacAirTForRowSecAtVentLeEvaprTQf : 389|1@0+ (1,0) [0|1] "" IHU,ZCUD
 SG_ HvacAirTForRowSecAtVentRi_UB : 342|1@0+ (1,0) [0|1] "" IHU,ZCUD
 SG_ HvacAirTForRowSecAtVentRiEvaprTFrnt : 404|13@0- (0.1,0.0) [-256.0|255.9] "degC" IHU,ZCUD
 SG_ HvacAirTForRowSecAtVentRiEvaprTQf : 405|1@0+ (1,0) [0|1] "" IHU,ZCUD
 SG_ HvacAirTForRowThrdAtFlrRi_UB : 465|1@0+ (1,0) [0|1] "" ZCUD
 SG_ HvacAirTForRowThrdAtFlrRiEvaprTFrnt : 479|13@0- (0.1,0.0) [-256.0|255.9] "degC" ZCUD
 SG_ HvacAirTForRowThrdAtFlrRiEvaprTQf : 464|1@0+ (1,0) [0|1] "" ZCUD
 SG_ HvacAirTForRowThrdAtVentRi_UB : 481|1@0+ (1,0) [0|1] "" ZCUD
 SG_ HvacAirTForRowThrdAtVentRiEvaprTFrnt : 495|13@0- (0.1,0.0) [-256.0|255.9] "degC" ZCUD
 SG_ HvacAirTForRowThrdAtVentRiEvaprTQf : 480|1@0+ (1,0) [0|1] "" ZCUD
 SG_ HvacCondsorT_UB : 343|1@0+ (1,0) [0|1] "" IHU,ZCUD
 SG_ HvacCondsorTEvaprTFrnt : 420|13@0- (0.1,0.0) [-256.0|255.9] "degC" IHU,ZCUD
 SG_ HvacCondsorTEvaprTQf : 421|1@0+ (1,0) [0|1] "" IHU,ZCUD
 SG_ HvacCondsorTsp_UB : 358|1@0+ (1,0) [0|1] "" IHU,ZCUD
 SG_ HvacCondsorTspEvaprTFrnt : 436|13@0- (0.1,0.0) [-256.0|255.9] "degC" IHU,ZCUD
 SG_ HvacCondsorTspEvaprTQf : 437|1@0+ (1,0) [0|1] "" IHU,ZCUD
 SG_ HvacHeatrInletTempReq_UB : 163|1@0+ (1,0) [0|1] "" IHU,ZCUD
 SG_ HvacHeatrInletTempReqEvaprTFrnt : 111|13@0- (0.1,0.0) [-256.0|255.9] "degC" IHU,ZCUD
 SG_ HvacHeatrInletTempReqEvaprTQf : 114|1@0+ (1,0) [0|1] "" IHU,ZCUD
 SG_ HvacOsaAndRecActrQfForHp : 375|1@0+ (1,0) [0|1] "" IHU,ZCUD
 SG_ HvacOsaAndRecActrQfForHp_UB : 374|1@0+ (1,0) [0|1] "" IHU,ZCUD
 SG_ HvacTempFlapActlPosnFrstRowLe : 135|10@0+ (0.1,0.0) [0.0|100.0] "%" IHU,ZCUD
 SG_ HvacTempFlapActlPosnFrstRowLe_UB : 164|1@0+ (1,0) [0|1] "" IHU,ZCUD
 SG_ HvacTempFlapActlPosnFrstRowRi : 137|10@0+ (0.1,0.0) [0.0|100.0] "%" IHU,ZCUD
 SG_ HvacTempFlapActlPosnFrstRowRi_UB : 165|1@0+ (1,0) [0|1] "" IHU,ZCUD
 SG_ HvacTempFlapActlPosnSecRowLe : 159|10@0+ (0.1,0.0) [0.0|100.0] "%" IHU,ZCUD
 SG_ HvacTempFlapActlPosnSecRowLe_UB : 176|1@0+ (1,0) [0|1] "" IHU,ZCUD
 SG_ HvacTempFlapActlPosnSecRowRi : 161|10@0+ (0.1,0.0) [0.0|100.0] "%" IHU,ZCUD
 SG_ HvacTempFlapActlPosnSecRowRi_UB : 177|1@0+ (1,0) [0|1] "" IHU,ZCUD
 SG_ HvahHeatgReq : 73|1@0+ (1,0) [0|1] "" IHU,ZCUD
 SG_ HvahHeatgReq_UB : 178|1@0+ (1,0) [0|1] "" IHU,ZCUD
 SG_ HvahPwrReq : 455|8@0+ (20.0,0.0) [0.0|5100.0] "W" IHU,ZCUD
 SG_ HvahPwrReq_UB : 359|1@0+ (1,0) [0|1] "" IHU,ZCUD
 SG_ MirrDefrstAtPassSts : 72|1@0+ (1,0) [0|1] "" IHU,ZCUD
 SG_ MirrDefrstAtPassSts_UB : 179|1@0+ (1,0) [0|1] "" IHU,ZCUD
 SG_ ReHvacBlowerSts : 92|2@0+ (1,0) [0|3] "" IHU,ZCUD
 SG_ ReHvacBlowerSts_UB : 180|1@0+ (1,0) [0|1] "" IHU,ZCUD
 SG_ ReHvacHexAirT_UB : 139|1@0+ (1,0) [0|1] "" ZCUD
 SG_ ReHvacHexAirTHvacAirTForHeatrFrnt : 463|13@0- (0.1,0.0) [-256.0|255.9] "degC" ZCUD
 SG_ ReHvacHexAirTHvacAirTForHeatrFrntQf : 466|1@0+ (1,0) [0|1] "" ZCUD
 SG_ RemClimaActv : 90|1@0+ (1,0) [0|1] "" IHU
 SG_ RemClimaActv_UB : 181|1@0+ (1,0) [0|1] "" IHU
 SG_ ResrvdSigForECM1 : 47|8@0+ (1.0,0.0) [0.0|255.0] "Unitless" IHU,ZCUD
 SG_ ResrvdSigForECM1_UB : 182|1@0+ (1,0) [0|1] "" IHU,ZCUD
 SG_ ResrvdSigForECM2 : 55|8@0+ (1.0,0.0) [0.0|255.0] "Unitless" IHU,ZCUD
 SG_ ResrvdSigForECM2_UB : 183|1@0+ (1,0) [0|1] "" IHU,ZCUD
 SG_ ResrvdSigForECM3 : 7|16@0+ (1.0,0.0) [0.0|65535.0] "Unitless" IHU,ZCUD
 SG_ ResrvdSigForECM3_UB : 184|1@0+ (1,0) [0|1] "" IHU,ZCUD
 SG_ ResrvdSigForECM4 : 23|16@0+ (1.0,0.0) [0.0|65535.0] "Unitless" IHU,ZCUD
 SG_ ResrvdSigForECM4_UB : 185|1@0+ (1,0) [0|1] "" IHU,ZCUD
 SG_ TiOfDeactvnForClimaCtrl : 63|6@0+ (1.0,0.0) [0.0|59.0] "s" IHU,ZCUD
 SG_ TiOfDeactvnForClimaCtrl_UB : 188|1@0+ (1,0) [0|1] "" IHU,ZCUD
 SG_ UBoostReqByClima : 89|1@0+ (1,0) [0|1] "" IHU,ZCUD
 SG_ UBoostReqByClima_UB : 189|1@0+ (1,0) [0|1] "" IHU,ZCUD

BO_ 643 ZcupZCUCANFD2Fr09 : 64 ZCUP
 SG_ CdsParkgClimaActv : 20|1@0+ (1,0) [0|1] "" IHU
 SG_ CdsParkgClimaActv_UB : 19|1@0+ (1,0) [0|1] "" IHU
 SG_ ClimaOvrHeatProActv : 17|1@0+ (1,0) [0|1] "" IHU
 SG_ ClimaOvrHeatProActv_UB : 112|1@0+ (1,0) [0|1] "" IHU
 SG_ CmptmtAirDistbnRsp_UB : 18|1@0+ (1,0) [0|1] "" IHU,ZCUD
 SG_ CmptmtAirDistbnRspAirDistbnDrvr : 7|3@0+ (1,0) [0|7] "" IHU,ZCUD
 SG_ CmptmtAirDistbnRspAirDistbnPass : 4|3@0+ (1,0) [0|7] "" IHU,ZCUD
 SG_ CmptmtAirDistbnRspAirDistbnSecLe : 15|3@0+ (1,0) [0|7] "" IHU,ZCUD
 SG_ CmptmtAirDistbnRspAirDistbnSecRi : 12|3@0+ (1,0) [0|7] "" IHU,ZCUD
 SG_ CmptmtAirDistbnRspAirDistbnThrd : 23|3@0+ (1,0) [0|7] "" IHU,ZCUD
 SG_ DoorPassCinhIntFailInf_UB : 29|1@0+ (1,0) [0|1] "" IHU
 SG_ DoorPassCinhIntFailInfCinchFlt1 : 31|1@0+ (1,0) [0|1] "" IHU
 SG_ DoorPassCinhIntFailInfCinchRestFlt : 30|1@0+ (1,0) [0|1] "" IHU
 SG_ DoorPassRelsFail_UB : 25|1@0+ (1,0) [0|1] "" IHU
 SG_ DoorPassRelsFailCinchOverTimed : 28|1@0+ (1,0) [0|1] "" IHU
 SG_ DoorPassRelsFailFailure1 : 27|1@0+ (1,0) [0|1] "" IHU
 SG_ DoorPassRelsFailMechRels : 26|1@0+ (1,0) [0|1] "" IHU
 SG_ DoorRiReCinhIntFailInf_UB : 24|1@0+ (1,0) [0|1] "" IHU
 SG_ DoorRiReCinhIntFailInfCinchFlt1 : 39|1@0+ (1,0) [0|1] "" IHU
 SG_ DoorRiReCinhIntFailInfCinchRestFlt : 38|1@0+ (1,0) [0|1] "" IHU
 SG_ DoorRiReRelsFail_UB : 34|1@0+ (1,0) [0|1] "" IHU
 SG_ DoorRiReRelsFailCinchOverTimed : 37|1@0+ (1,0) [0|1] "" IHU
 SG_ DoorRiReRelsFailFailure1 : 36|1@0+ (1,0) [0|1] "" IHU
 SG_ DoorRiReRelsFailMechRels : 35|1@0+ (1,0) [0|1] "" IHU
 SG_ HvacAirTForMaxTZone_UB : 122|1@0+ (1,0) [0|1] "" IHU,ZCUD
 SG_ HvacAirTForMaxTZoneEvaprTFrnt : 47|13@0- (0.1,0.0) [-256.0|255.9] "degC" IHU,ZCUD
 SG_ HvacAirTForMaxTZoneEvaprTQf : 50|1@0+ (1,0) [0|1] "" IHU,ZCUD
 SG_ HvacHeatgReq : 141|1@0+ (1,0) [0|1] "" IHU,ZCUD
 SG_ HvacHeatgReq_UB : 140|1@0+ (1,0) [0|1] "" IHU,ZCUD
 SG_ HvahAirTsp : 79|11@0+ (0.1,-40.0) [-40.0|164.70000000000002] "degC" IHU,ZCUD
 SG_ HvahAirTsp_UB : 123|1@0+ (1,0) [0|1] "" IHU,ZCUD
 SG_ IntPm25LvlFrmClima : 84|3@0+ (1,0) [0|7] "" IHU
 SG_ IntPm25LvlFrmClima_UB : 124|1@0+ (1,0) [0|1] "" IHU
 SG_ IntPm25VluFrmClima : 111|10@0+ (1.0,0.0) [0.0|1023.0] "Unitless" IHU
 SG_ IntPm25VluFrmClima_UB : 126|1@0+ (1,0) [0|1] "" IHU
 SG_ OutdPm25LvlFrmClima : 66|3@0+ (1,0) [0|7] "" IHU
 SG_ OutdPm25LvlFrmClima_UB : 125|1@0+ (1,0) [0|1] "" IHU
 SG_ OutdPm25VluFrmClima : 95|10@0+ (1.0,0.0) [0.0|1023.0] "Unitless" IHU
 SG_ OutdPm25VluFrmClima_UB : 127|1@0+ (1,0) [0|1] "" IHU
 SG_ PassSeatHeatgAutoSts : 33|2@0+ (1,0) [0|3] "" IHU
 SG_ PassSeatHeatgAutoSts_UB : 128|1@0+ (1,0) [0|1] "" IHU
 SG_ PassSeatHeatgAvlSts : 101|3@0+ (1,0) [0|7] "" IHU
 SG_ PassSeatHeatgAvlSts_UB : 129|1@0+ (1,0) [0|1] "" IHU
 SG_ PassSeatVentnAutoSts : 81|2@0+ (1,0) [0|3] "" IHU
 SG_ PassSeatVentnAutoSts_UB : 131|1@0+ (1,0) [0|1] "" IHU
 SG_ RemClimaDefrstSts : 117|1@0+ (1,0) [0|1] "" IHU
 SG_ RemClimaDefrstSts_UB : 132|1@0+ (1,0) [0|1] "" IHU
 SG_ RemClimaHvSts : 116|1@0+ (1,0) [0|1] "" IHU
 SG_ RemClimaHvSts_UB : 133|1@0+ (1,0) [0|1] "" IHU
 SG_ RemVentActvSts : 115|1@0+ (1,0) [0|1] "" IHU
 SG_ RemVentActvSts_UB : 134|1@0+ (1,0) [0|1] "" IHU
 SG_ RemVentReqRspnFb : 114|1@0+ (1,0) [0|1] "" IHU
 SG_ RemVentReqRspnFb_UB : 135|1@0+ (1,0) [0|1] "" IHU
 SG_ RemVentWarnSts : 97|2@0+ (1,0) [0|3] "" IHU
 SG_ RemVentWarnSts_UB : 136|1@0+ (1,0) [0|1] "" IHU
 SG_ TgtHvacAirTForMaxTZone : 63|13@0- (0.1,0.0) [-256.0|255.9] "degC" IHU,ZCUD
 SG_ TgtHvacAirTForMaxTZone_UB : 137|1@0+ (1,0) [0|1] "" IHU,ZCUD
 SG_ WinFailrStsAtPass : 98|1@0+ (1,0) [0|1] "" IHU
 SG_ WinFailrStsAtPass_UB : 138|1@0+ (1,0) [0|1] "" IHU
 SG_ WinFailrStsAtReRi : 113|1@0+ (1,0) [0|1] "" IHU
 SG_ WinFailrStsAtReRi_UB : 139|1@0+ (1,0) [0|1] "" IHU

BO_ 882 ZcupZCUCANFD2Fr10 : 64 ZCUP
 SG_ ClimaActvAlrmSts : 23|1@0+ (1,0) [0|1] "" IHU,ZCUD
 SG_ ClimaActvAlrmSts_UB : 7|1@0+ (1,0) [0|1] "" IHU,ZCUD
 SG_ HvacHexAirT_UB : 6|1@0+ (1,0) [0|1] "" IHU,ZCUD
 SG_ HvacHexAirTHvacAirTForHeatrFrnt : 4|13@0- (0.1,0.0) [-256.0|255.9] "degC" IHU,ZCUD
 SG_ HvacHexAirTHvacAirTForHeatrFrntQf : 5|1@0+ (1,0) [0|1] "" IHU,ZCUD
 SG_ HwRowFrstPassFrntExtMotCtrl : 21|2@0+ (1,0) [0|3] "" IHU
 SG_ HwRowFrstPassFrntExtMotCtrl_UB : 22|1@0+ (1,0) [0|1] "" IHU
 SG_ HwRowFrstPassFrntHeiMotCtrl : 19|2@0+ (1,0) [0|3] "" IHU
 SG_ HwRowFrstPassFrntHeiMotCtrl_UB : 17|1@0+ (1,0) [0|1] "" IHU
 SG_ HwRowFrstPassHeiMotCtrl : 31|2@0+ (1,0) [0|3] "" IHU
 SG_ HwRowFrstPassHeiMotCtrl_UB : 16|1@0+ (1,0) [0|1] "" IHU
 SG_ HwRowFrstPassInclMotCtrl : 29|2@0+ (1,0) [0|3] "" IHU
 SG_ HwRowFrstPassInclMotCtrl_UB : 27|1@0+ (1,0) [0|1] "" IHU
 SG_ HwRowFrstPassSldMotCtrl : 25|2@0+ (1,0) [0|3] "" IHU
 SG_ HwRowFrstPassSldMotCtrl_UB : 26|1@0+ (1,0) [0|1] "" IHU
 SG_ IntrLiAmb1_UB : 174|1@0+ (1,0) [0|1] "" IHU
 SG_ IntrLiAmb1BnIngrd : 47|8@0+ (1.0,0.0) [0.0|255.0] "Unitless" IHU
 SG_ IntrLiAmb1GrnIngrd : 55|8@0+ (1.0,0.0) [0.0|255.0] "Unitless" IHU
 SG_ IntrLiAmb1Intensty : 95|7@0+ (1.0,0.0) [0.0|127.0] "Unitless" IHU
 SG_ IntrLiAmb1RedIngrd : 63|8@0+ (1.0,0.0) [0.0|255.0] "Unitless" IHU
 SG_ IntrLiAmb1SelCmd1 : 71|8@0+ (1.0,0.0) [0.0|255.0] "Unitless" IHU
 SG_ IntrLiAmb1SelCmd2 : 79|8@0+ (1.0,0.0) [0.0|255.0] "Unitless" IHU
 SG_ IntrLiAmb1SynchDelay : 103|7@0+ (1.0,0.0) [0.0|127.0] "Unitless" IHU
 SG_ IntrLiAmb1TargetTransitionTime : 87|8@0+ (1.0,0.0) [0.0|255.0] "Unitless" IHU
 SG_ IntrLiAmb1Trigger : 88|1@0+ (1,0) [0|1] "" IHU
 SG_ IntrLiAmb1Update : 96|1@0+ (1,0) [0|1] "" IHU
 SG_ IntrLiAmb2_UB : 175|1@0+ (1,0) [0|1] "" IHU
 SG_ IntrLiAmb2BnIngrd : 111|8@0+ (1.0,0.0) [0.0|255.0] "Unitless" IHU
 SG_ IntrLiAmb2GrnIngrd : 119|8@0+ (1.0,0.0) [0.0|255.0] "Unitless" IHU
 SG_ IntrLiAmb2Intensty : 159|7@0+ (1.0,0.0) [0.0|127.0] "Unitless" IHU
 SG_ IntrLiAmb2RedIngrd : 127|8@0+ (1.0,0.0) [0.0|255.0] "Unitless" IHU
 SG_ IntrLiAmb2SelCmd1 : 135|8@0+ (1.0,0.0) [0.0|255.0] "Unitless" IHU
 SG_ IntrLiAmb2SelCmd2 : 143|8@0+ (1.0,0.0) [0.0|255.0] "Unitless" IHU
 SG_ IntrLiAmb2SynchDelay : 167|7@0+ (1.0,0.0) [0.0|127.0] "Unitless" IHU
 SG_ IntrLiAmb2TargetTransitionTime : 151|8@0+ (1.0,0.0) [0.0|255.0] "Unitless" IHU
 SG_ IntrLiAmb2Trigger : 152|1@0+ (1,0) [0|1] "" IHU
 SG_ IntrLiAmb2Update : 160|1@0+ (1,0) [0|1] "" IHU
 SG_ WinHwSwtPassDoor : 39|3@0+ (1,0) [0|7] "" IHU
 SG_ WinHwSwtPassDoor_UB : 36|1@0+ (1,0) [0|1] "" IHU
 SG_ WinHwSwtPassReDoor : 35|3@0+ (1,0) [0|7] "" IHU
 SG_ WinHwSwtPassReDoor_UB : 32|1@0+ (1,0) [0|1] "" IHU

BO_ 451 ZcupZCUCANFD2Fr11 : 64 ZCUP
 SG_ BkpOfDstTrvldFromVehCom : 180|21@0+ (1.0,0.0) [0.0|2000000.0] "km" IHU
 SG_ BkpOfDstTrvldFromVehCom_UB : 207|1@0+ (1,0) [0|1] "" IHU
 SG_ CCMFragraCh1AvlTiPrec : 247|10@0+ (0.1,0.0) [0.0|100.0] "%" IHU
 SG_ CCMFragraCh1AvlTiPrec_UB : 293|1@0+ (1,0) [0|1] "" IHU
 SG_ CCMFragraCh2AvlTiPrec : 253|10@0+ (0.1,0.0) [0.0|100.0] "%" IHU
 SG_ CCMFragraCh2AvlTiPrec_UB : 292|1@0+ (1,0) [0|1] "" IHU
 SG_ CCMFragraCh3AvlTiPrec : 259|10@0+ (0.1,0.0) [0.0|100.0] "%" IHU
 SG_ CCMFragraCh3AvlTiPrec_UB : 291|1@0+ (1,0) [0|1] "" IHU
 SG_ CCMFragraCh4AvlTiPrec : 265|10@0+ (0.1,0.0) [0.0|100.0] "%" IHU
 SG_ CCMFragraCh4AvlTiPrec_UB : 290|1@0+ (1,0) [0|1] "" IHU
 SG_ CCMFragraCh5AvlTiPrec : 287|10@0+ (0.1,0.0) [0.0|100.0] "%" IHU
 SG_ CCMFragraCh5AvlTiPrec_UB : 289|1@0+ (1,0) [0|1] "" IHU
 SG_ CCMHvahFltIndcn : 233|1@0+ (1,0) [0|1] "" IHU
 SG_ CCMHvahFltIndcn_UB : 232|1@0+ (1,0) [0|1] "" IHU
 SG_ ClimaOvrHeatProActvSts : 303|1@0+ (1,0) [0|1] "" IHU
 SG_ ClimaOvrHeatProActvSts_UB : 302|1@0+ (1,0) [0|1] "" IHU
 SG_ ClimaPwrCns : 10|11@0+ (1.0,0.0) [0.0|2047.0] "W" IHU,ZCUD
 SG_ ClimaPwrCns_UB : 88|1@0+ (1,0) [0|1] "" IHU,ZCUD
 SG_ ClimaPwrCritDes : 34|11@0+ (1.0,0.0) [0.0|2047.0] "W" IHU,ZCUD
 SG_ ClimaPwrCritDes_UB : 89|1@0+ (1,0) [0|1] "" IHU,ZCUD
 SG_ ClimaPwrNormDes : 106|11@0+ (1.0,0.0) [0.0|2047.0] "W" IHU,ZCUD
 SG_ ClimaPwrNormDes_UB : 120|1@0+ (1,0) [0|1] "" IHU,ZCUD
 SG_ DstTrvldVldFromVehCom : 182|1@0+ (1,0) [0|1] "" IHU
 SG_ DstTrvldVldFromVehCom_UB : 181|1@0+ (1,0) [0|1] "" IHU
 SG_ EcoClimaSts : 301|1@0+ (1,0) [0|1] "" IHU,ZCUD
 SG_ EcoClimaSts_UB : 300|1@0+ (1,0) [0|1] "" IHU,ZCUD
 SG_ FltOfFrntTurnIndcrLe : 72|1@0+ (1,0) [0|1] "" IHU,ZCUD
 SG_ FltOfFrntTurnIndcrLe_UB : 90|1@0+ (1,0) [0|1] "" IHU,ZCUD
 SG_ FltOfFrntTurnIndcrRi : 64|1@0+ (1,0) [0|1] "" IHU,ZCUD
 SG_ FltOfFrntTurnIndcrRi_UB : 91|1@0+ (1,0) [0|1] "" IHU,ZCUD
 SG_ FltOfReTurnIndcrLe : 56|1@0+ (1,0) [0|1] "" IHU,ZCUD
 SG_ FltOfReTurnIndcrLe_UB : 107|1@0+ (1,0) [0|1] "" IHU,ZCUD
 SG_ FltOfReTurnIndcrRi : 48|1@0+ (1,0) [0|1] "" IHU,ZCUD
 SG_ FltOfReTurnIndcrRi_UB : 136|1@0+ (1,0) [0|1] "" IHU,ZCUD
 SG_ FuSnsrActvSide_UB : 137|1@0+ (1,0) [0|1] "" IHU
 SG_ FuSnsrActvSideFuLvlSnsrRawVal : 7|11@0+ (1.0,0.0) [0.0|2047.0] "Ohm" IHU
 SG_ FuSnsrActvSideGenQF : 12|2@0+ (1,0) [0|3] "" IHU
 SG_ FuSnsrPasSide_UB : 138|1@0+ (1,0) [0|1] "" IHU
 SG_ FuSnsrPasSideFuLvlSnsrRawVal : 31|11@0+ (1.0,0.0) [0.0|2047.0] "Ohm" IHU
 SG_ FuSnsrPasSideGenQF : 36|2@0+ (1,0) [0|3] "" IHU
 SG_ HvacFanLvlFbFrnt : 307|4@0+ (1,0) [0|15] "" IHU
 SG_ HvacFanLvlFbFrnt_UB : 314|1@0+ (1,0) [0|1] "" IHU
 SG_ HvacFanLvlFbRe : 319|4@0+ (1,0) [0|15] "" IHU
 SG_ HvacFanLvlFbRe_UB : 315|1@0+ (1,0) [0|1] "" IHU
 SG_ HvacRecircAct : 55|7@0+ (1.0,0.0) [0.0|100.0] "%" IHU,ZCUD
 SG_ HvacRecircAct_UB : 139|1@0+ (1,0) [0|1] "" IHU,ZCUD
 SG_ IntLightPasSideDoorSupply : 63|7@0+ (1.0,0.0) [0.0|100.0] "Unitless" IHU,ZCUD
 SG_ IntLightPasSideDoorSupply_UB : 152|1@0+ (1,0) [0|1] "" IHU,ZCUD
 SG_ IntLightPasSideSupply : 71|7@0+ (1.0,0.0) [0.0|100.0] "Unitless" IHU,ZCUD
 SG_ IntLightPasSideSupply_UB : 153|1@0+ (1,0) [0|1] "" IHU,ZCUD
 SG_ IntLightRePasDoorSupply : 79|7@0+ (1.0,0.0) [0.0|100.0] "Unitless" IHU,ZCUD
 SG_ IntLightRePasDoorSupply_UB : 154|1@0+ (1,0) [0|1] "" IHU,ZCUD
 SG_ IntLightRePasSideSupply : 127|7@0+ (1.0,0.0) [0.0|100.0] "Unitless" IHU,ZCUD
 SG_ IntLightRePasSideSupply_UB : 155|1@0+ (1,0) [0|1] "" IHU,ZCUD
 SG_ PassMassgRunng : 235|1@0+ (1,0) [0|1] "" IHU
 SG_ PassMassgRunng_UB : 234|1@0+ (1,0) [0|1] "" IHU
 SG_ PassSeatActvSpplFct : 206|3@0+ (1,0) [0|7] "" IHU
 SG_ PassSeatActvSpplFct_UB : 236|1@0+ (1,0) [0|1] "" IHU
 SG_ PassSeatHeatgLvlSts : 299|2@0+ (1,0) [0|3] "" IHU
 SG_ PassSeatHeatgLvlSts_UB : 311|1@0+ (1,0) [0|1] "" IHU
 SG_ PassSeatSwtSts2_UB : 237|1@0+ (1,0) [0|1] "" IHU
 SG_ PassSeatSwtSts2PassSeatSwtAdjmtOfSpplFctHozlSts : 223|2@0+ (1,0) [0|3] "" IHU
 SG_ PassSeatSwtSts2PassSeatSwtAdjmtOfSpplFctVerSts : 221|2@0+ (1,0) [0|3] "" IHU
 SG_ PassSeatSwtSts2PassSeatSwtHdrstHozlSts : 219|2@0+ (1,0) [0|3] "" IHU
 SG_ PassSeatSwtSts2PassSeatSwtHdrstVertSts : 217|2@0+ (1,0) [0|3] "" IHU
 SG_ PassSeatSwtSts2PassSeatSwtHeiFrntSts : 231|2@0+ (1,0) [0|3] "" IHU
 SG_ PassSeatSwtSts2PassSeatSwtHeiSts : 229|2@0+ (1,0) [0|3] "" IHU
 SG_ PassSeatSwtSts2PassSeatSwtInclSts : 227|2@0+ (1,0) [0|3] "" IHU
 SG_ PassSeatSwtSts2PassSeatSwtSelnOfSpplFctStsSts : 225|2@0+ (1,0) [0|3] "" IHU
 SG_ PassSeatSwtSts2PassSeatSwtSldSts : 239|2@0+ (1,0) [0|3] "" IHU
 SG_ PassSeatVentnLvlSts : 297|2@0+ (1,0) [0|3] "" IHU
 SG_ PassSeatVentnLvlSts_UB : 288|1@0+ (1,0) [0|1] "" IHU
 SG_ PwrEstimdAtStbForClima : 202|11@0+ (1.0,0.0) [0.0|2047.0] "W" IHU,ZCUD
 SG_ PwrEstimdAtStbForClima_UB : 203|1@0+ (1,0) [0|1] "" IHU,ZCUD

BO_ 258 ZcupZCUCANFD2Fr12 : 64 ZCUP
 SG_ ClimaSts : 1|1@0+ (1,0) [0|1] "" IHU,ZCUD
 SG_ ClimaSts_UB : 8|1@0+ (1,0) [0|1] "" IHU,ZCUD
 SG_ DoorPassHndlSts : 7|3@0+ (1,0) [0|7] "" IHU,ZCUD
 SG_ DoorPassHndlSts_UB : 9|1@0+ (1,0) [0|1] "" IHU,ZCUD
 SG_ DoorPassReLockSts : 15|2@0+ (1,0) [0|3] "" IHU,ZCUD
 SG_ DoorPassReLockSts_UB : 10|1@0+ (1,0) [0|1] "" IHU,ZCUD
 SG_ DoorRiReHndlSts : 4|3@0+ (1,0) [0|7] "" IHU,ZCUD
 SG_ DoorRiReHndlSts_UB : 11|1@0+ (1,0) [0|1] "" IHU,ZCUD
 SG_ EngRunngReqByClima : 13|2@0+ (1,0) [0|3] "" IHU,ZCUD
 SG_ EngRunngReqByClima_UB : 23|1@0+ (1,0) [0|1] "" IHU,ZCUD
 SG_ HvacCoolgEnaFrnt : 0|1@0+ (1,0) [0|1] "" IHU,ZCUD
 SG_ HvacCoolgEnaFrnt_UB : 22|1@0+ (1,0) [0|1] "" IHU,ZCUD
 SG_ SeatClimaDurgClimaHmiSeatHeatgForRowThrdLe : 31|2@0+ (1,0) [0|3] "" ZCUD
 SG_ SeatClimaDurgClimaHmiSeatHeatgForRowThrdLe_UB : 21|1@0+ (1,0) [0|1] "" ZCUD
 SG_ SeatClimaDurgClimaHmiSeatHeatgForRowThrdRi : 29|2@0+ (1,0) [0|3] "" ZCUD
 SG_ SeatClimaDurgClimaHmiSeatHeatgForRowThrdRi_UB : 20|1@0+ (1,0) [0|1] "" ZCUD
 SG_ SeatClimaDurgClimaHmiSeatVentnForRowThrdLe : 27|2@0+ (1,0) [0|3] "" ZCUD
 SG_ SeatClimaDurgClimaHmiSeatVentnForRowThrdLe_UB : 19|1@0+ (1,0) [0|1] "" ZCUD
 SG_ SeatClimaDurgClimaHmiSeatVentnForRowThrdRi : 25|2@0+ (1,0) [0|3] "" ZCUD
 SG_ SeatClimaDurgClimaHmiSeatVentnForRowThrdRi_UB : 18|1@0+ (1,0) [0|1] "" ZCUD

BO_ 455 ZcupZCUCANFD2Fr15 : 64 ZCUP
 SG_ ClimaOffReq : 31|2@0+ (1,0) [0|3] "" IHU
 SG_ ClimaOffReq_UB : 27|1@0+ (1,0) [0|1] "" IHU
 SG_ ClimaOvrHeatProRspn : 23|1@0+ (1,0) [0|1] "" IHU
 SG_ ClimaOvrHeatProRspn_UB : 26|1@0+ (1,0) [0|1] "" IHU
 SG_ ClimaOvrHeatProWarn : 29|2@0+ (1,0) [0|3] "" IHU
 SG_ ClimaOvrHeatProWarn_UB : 25|1@0+ (1,0) [0|1] "" IHU
 SG_ DiDblLock : 3|1@0+ (1,0) [0|1] "" IHU,ZCUD
 SG_ DiDblLock_UB : 9|1@0+ (1,0) [0|1] "" IHU,ZCUD
 SG_ RemClimaDelaySts : 2|1@0+ (1,0) [0|1] "" IHU
 SG_ RemClimaDelaySts_UB : 8|1@0+ (1,0) [0|1] "" IHU
 SG_ RemClimaExtnTiRspn : 1|1@0+ (1,0) [0|1] "" IHU
 SG_ RemClimaExtnTiRspn_UB : 16|1@0+ (1,0) [0|1] "" IHU
 SG_ RemClimaHvRspn : 0|1@0+ (1,0) [0|1] "" IHU
 SG_ RemClimaHvRspn_UB : 17|1@0+ (1,0) [0|1] "" IHU
 SG_ RemClimaWarn : 7|4@0+ (1,0) [0|15] "" IHU
 SG_ RemClimaWarn_UB : 18|1@0+ (1,0) [0|1] "" IHU
 SG_ RemStrtClimaRspn : 11|1@0+ (1,0) [0|1] "" IHU
 SG_ RemStrtClimaRspn_UB : 19|1@0+ (1,0) [0|1] "" IHU
 SG_ RoofOpnReqFrmClima : 10|1@0+ (1,0) [0|1] "" IHU,ZCUD
 SG_ RoofOpnReqFrmClima_UB : 20|1@0+ (1,0) [0|1] "" IHU,ZCUD
 SG_ SchedCmptHeatCoolFB : 15|2@0+ (1,0) [0|3] "" IHU
 SG_ SchedCmptHeatCoolFB_UB : 21|1@0+ (1,0) [0|1] "" IHU
 SG_ WinAndRoofReqFrmClima : 13|2@0+ (1,0) [0|3] "" IHU,ZCUD
 SG_ WinAndRoofReqFrmClima_UB : 22|1@0+ (1,0) [0|1] "" IHU,ZCUD

BO_ 51 ZcupZCUCANFD2Fr16 : 64 ZCUP
 SG_ BodyDataTraceZCUP1_UB : 511|1@0+ (1,0) [0|1] "" ZCUD
 SG_ BodyDataTraceZCUP1Functiondevpsignalgroup1 : 7|8@0+ (1.0,0.0) [0.0|255.0] "Unitless" ZCUD
 SG_ BodyDataTraceZCUP1Functiondevpsignalgroup2 : 15|8@0+ (1.0,0.0) [0.0|255.0] "Unitless" ZCUD
 SG_ BodyDataTraceZCUP1Functiondevpsignalgroup3 : 23|8@0+ (1.0,0.0) [0.0|255.0] "Unitless" ZCUD
 SG_ BodyDataTraceZCUP1Functiondevpsignalgroup4 : 31|8@0+ (1.0,0.0) [0.0|255.0] "Unitless" ZCUD
 SG_ BodyDataTraceZCUP1Functiondevpsignalgroup5 : 39|8@0+ (1.0,0.0) [0.0|255.0] "Unitless" ZCUD
 SG_ BodyDataTraceZCUP1Functiondevpsignalgroup6 : 47|8@0+ (1.0,0.0) [0.0|255.0] "Unitless" ZCUD
 SG_ BodyDataTraceZCUP1Functiondevpsignalgroup7 : 55|8@0+ (1.0,0.0) [0.0|255.0] "Unitless" ZCUD
 SG_ BodyDataTraceZCUP1Functiondevpsignalgroup8 : 63|8@0+ (1.0,0.0) [0.0|255.0] "Unitless" ZCUD
 SG_ BodyDataTraceZCUP2_UB : 510|1@0+ (1,0) [0|1] "" ZCUD
 SG_ BodyDataTraceZCUP2Functiondevpsignalgroup1 : 71|8@0+ (1.0,0.0) [0.0|255.0] "Unitless" ZCUD
 SG_ BodyDataTraceZCUP2Functiondevpsignalgroup2 : 79|8@0+ (1.0,0.0) [0.0|255.0] "Unitless" ZCUD
 SG_ BodyDataTraceZCUP2Functiondevpsignalgroup3 : 87|8@0+ (1.0,0.0) [0.0|255.0] "Unitless" ZCUD
 SG_ BodyDataTraceZCUP2Functiondevpsignalgroup4 : 95|8@0+ (1.0,0.0) [0.0|255.0] "Unitless" ZCUD
 SG_ BodyDataTraceZCUP2Functiondevpsignalgroup5 : 103|8@0+ (1.0,0.0) [0.0|255.0] "Unitless" ZCUD
 SG_ BodyDataTraceZCUP2Functiondevpsignalgroup6 : 111|8@0+ (1.0,0.0) [0.0|255.0] "Unitless" ZCUD
 SG_ BodyDataTraceZCUP2Functiondevpsignalgroup7 : 119|8@0+ (1.0,0.0) [0.0|255.0] "Unitless" ZCUD
 SG_ BodyDataTraceZCUP2Functiondevpsignalgroup8 : 127|8@0+ (1.0,0.0) [0.0|255.0] "Unitless" ZCUD
 SG_ BodyDataTraceZCUP3_UB : 509|1@0+ (1,0) [0|1] "" ZCUD
 SG_ BodyDataTraceZCUP3Functiondevpsignalgroup1 : 135|8@0+ (1.0,0.0) [0.0|255.0] "Unitless" ZCUD
 SG_ BodyDataTraceZCUP3Functiondevpsignalgroup2 : 143|8@0+ (1.0,0.0) [0.0|255.0] "Unitless" ZCUD
 SG_ BodyDataTraceZCUP3Functiondevpsignalgroup3 : 151|8@0+ (1.0,0.0) [0.0|255.0] "Unitless" ZCUD
 SG_ BodyDataTraceZCUP3Functiondevpsignalgroup4 : 159|8@0+ (1.0,0.0) [0.0|255.0] "Unitless" ZCUD
 SG_ BodyDataTraceZCUP3Functiondevpsignalgroup5 : 167|8@0+ (1.0,0.0) [0.0|255.0] "Unitless" ZCUD
 SG_ BodyDataTraceZCUP3Functiondevpsignalgroup6 : 175|8@0+ (1.0,0.0) [0.0|255.0] "Unitless" ZCUD
 SG_ BodyDataTraceZCUP3Functiondevpsignalgroup7 : 183|8@0+ (1.0,0.0) [0.0|255.0] "Unitless" ZCUD
 SG_ BodyDataTraceZCUP3Functiondevpsignalgroup8 : 191|8@0+ (1.0,0.0) [0.0|255.0] "Unitless" ZCUD
 SG_ BodyDataTraceZCUP4_UB : 508|1@0+ (1,0) [0|1] "" ZCUD
 SG_ BodyDataTraceZCUP4Functiondevpsignalgroup1 : 199|8@0+ (1.0,0.0) [0.0|255.0] "Unitless" ZCUD
 SG_ BodyDataTraceZCUP4Functiondevpsignalgroup2 : 207|8@0+ (1.0,0.0) [0.0|255.0] "Unitless" ZCUD
 SG_ BodyDataTraceZCUP4Functiondevpsignalgroup3 : 215|8@0+ (1.0,0.0) [0.0|255.0] "Unitless" ZCUD
 SG_ BodyDataTraceZCUP4Functiondevpsignalgroup4 : 223|8@0+ (1.0,0.0) [0.0|255.0] "Unitless" ZCUD
 SG_ BodyDataTraceZCUP4Functiondevpsignalgroup5 : 231|8@0+ (1.0,0.0) [0.0|255.0] "Unitless" ZCUD
 SG_ BodyDataTraceZCUP4Functiondevpsignalgroup6 : 239|8@0+ (1.0,0.0) [0.0|255.0] "Unitless" ZCUD
 SG_ BodyDataTraceZCUP4Functiondevpsignalgroup7 : 247|8@0+ (1.0,0.0) [0.0|255.0] "Unitless" ZCUD
 SG_ BodyDataTraceZCUP4Functiondevpsignalgroup8 : 255|8@0+ (1.0,0.0) [0.0|255.0] "Unitless" ZCUD
 SG_ BodyDataTraceZCUP5_UB : 507|1@0+ (1,0) [0|1] "" ZCUD
 SG_ BodyDataTraceZCUP5Functiondevpsignalgroup1 : 263|8@0+ (1.0,0.0) [0.0|255.0] "Unitless" ZCUD
 SG_ BodyDataTraceZCUP5Functiondevpsignalgroup2 : 271|8@0+ (1.0,0.0) [0.0|255.0] "Unitless" ZCUD
 SG_ BodyDataTraceZCUP5Functiondevpsignalgroup3 : 279|8@0+ (1.0,0.0) [0.0|255.0] "Unitless" ZCUD
 SG_ BodyDataTraceZCUP5Functiondevpsignalgroup4 : 287|8@0+ (1.0,0.0) [0.0|255.0] "Unitless" ZCUD
 SG_ BodyDataTraceZCUP5Functiondevpsignalgroup5 : 295|8@0+ (1.0,0.0) [0.0|255.0] "Unitless" ZCUD
 SG_ BodyDataTraceZCUP5Functiondevpsignalgroup6 : 303|8@0+ (1.0,0.0) [0.0|255.0] "Unitless" ZCUD
 SG_ BodyDataTraceZCUP5Functiondevpsignalgroup7 : 311|8@0+ (1.0,0.0) [0.0|255.0] "Unitless" ZCUD
 SG_ BodyDataTraceZCUP5Functiondevpsignalgroup8 : 319|8@0+ (1.0,0.0) [0.0|255.0] "Unitless" ZCUD
 SG_ BodyDataTraceZCUP6_UB : 506|1@0+ (1,0) [0|1] "" ZCUD
 SG_ BodyDataTraceZCUP6Functiondevpsignalgroup1 : 327|8@0+ (1.0,0.0) [0.0|255.0] "Unitless" ZCUD
 SG_ BodyDataTraceZCUP6Functiondevpsignalgroup2 : 335|8@0+ (1.0,0.0) [0.0|255.0] "Unitless" ZCUD
 SG_ BodyDataTraceZCUP6Functiondevpsignalgroup3 : 343|8@0+ (1.0,0.0) [0.0|255.0] "Unitless" ZCUD
 SG_ BodyDataTraceZCUP6Functiondevpsignalgroup4 : 351|8@0+ (1.0,0.0) [0.0|255.0] "Unitless" ZCUD
 SG_ BodyDataTraceZCUP6Functiondevpsignalgroup5 : 359|8@0+ (1.0,0.0) [0.0|255.0] "Unitless" ZCUD
 SG_ BodyDataTraceZCUP6Functiondevpsignalgroup6 : 367|8@0+ (1.0,0.0) [0.0|255.0] "Unitless" ZCUD
 SG_ BodyDataTraceZCUP6Functiondevpsignalgroup7 : 375|8@0+ (1.0,0.0) [0.0|255.0] "Unitless" ZCUD
 SG_ BodyDataTraceZCUP6Functiondevpsignalgroup8 : 383|8@0+ (1.0,0.0) [0.0|255.0] "Unitless" ZCUD
 SG_ BodyDataTraceZCUP7_UB : 505|1@0+ (1,0) [0|1] "" ZCUD
 SG_ BodyDataTraceZCUP7Functiondevpsignalgroup1 : 391|8@0+ (1.0,0.0) [0.0|255.0] "Unitless" ZCUD
 SG_ BodyDataTraceZCUP7Functiondevpsignalgroup2 : 399|8@0+ (1.0,0.0) [0.0|255.0] "Unitless" ZCUD
 SG_ BodyDataTraceZCUP7Functiondevpsignalgroup3 : 407|8@0+ (1.0,0.0) [0.0|255.0] "Unitless" ZCUD
 SG_ BodyDataTraceZCUP7Functiondevpsignalgroup4 : 415|8@0+ (1.0,0.0) [0.0|255.0] "Unitless" ZCUD
 SG_ BodyDataTraceZCUP7Functiondevpsignalgroup5 : 423|8@0+ (1.0,0.0) [0.0|255.0] "Unitless" ZCUD
 SG_ BodyDataTraceZCUP7Functiondevpsignalgroup6 : 431|8@0+ (1.0,0.0) [0.0|255.0] "Unitless" ZCUD
 SG_ BodyDataTraceZCUP7Functiondevpsignalgroup7 : 439|8@0+ (1.0,0.0) [0.0|255.0] "Unitless" ZCUD
 SG_ BodyDataTraceZCUP7Functiondevpsignalgroup8 : 447|8@0+ (1.0,0.0) [0.0|255.0] "Unitless" ZCUD

BO_ 1350 ZcupZCUCANFD2VFCVectorFr : 8 ZCUP
 SG_ VFCVectorZCUPBlockID : 1|2@0+ (1.0,0.0) [0.0|3.0] "Unitless" IHU
 SG_ VFCVectorZCUPVFCid0 : 2|1@0+ (1,0) [0|1] "" IHU
 SG_ VFCVectorZCUPVFCid1 : 3|1@0+ (1,0) [0|1] "" IHU
 SG_ VFCVectorZCUPVFCid10 : 12|1@0+ (1,0) [0|1] "" IHU
 SG_ VFCVectorZCUPVFCid11 : 13|1@0+ (1,0) [0|1] "" IHU
 SG_ VFCVectorZCUPVFCid12 : 14|1@0+ (1,0) [0|1] "" IHU
 SG_ VFCVectorZCUPVFCid13 : 15|1@0+ (1,0) [0|1] "" IHU
 SG_ VFCVectorZCUPVFCid14 : 16|1@0+ (1,0) [0|1] "" IHU
 SG_ VFCVectorZCUPVFCid15 : 17|1@0+ (1,0) [0|1] "" IHU
 SG_ VFCVectorZCUPVFCid16 : 18|1@0+ (1,0) [0|1] "" IHU
 SG_ VFCVectorZCUPVFCid17 : 19|1@0+ (1,0) [0|1] "" IHU
 SG_ VFCVectorZCUPVFCid18 : 20|1@0+ (1,0) [0|1] "" IHU
 SG_ VFCVectorZCUPVFCid19 : 21|1@0+ (1,0) [0|1] "" IHU
 SG_ VFCVectorZCUPVFCid2 : 4|1@0+ (1,0) [0|1] "" IHU
 SG_ VFCVectorZCUPVFCid20 : 22|1@0+ (1,0) [0|1] "" IHU
 SG_ VFCVectorZCUPVFCid21 : 23|1@0+ (1,0) [0|1] "" IHU
 SG_ VFCVectorZCUPVFCid22 : 24|1@0+ (1,0) [0|1] "" IHU
 SG_ VFCVectorZCUPVFCid23 : 25|1@0+ (1,0) [0|1] "" IHU
 SG_ VFCVectorZCUPVFCid24 : 26|1@0+ (1,0) [0|1] "" IHU
 SG_ VFCVectorZCUPVFCid25 : 27|1@0+ (1,0) [0|1] "" IHU
 SG_ VFCVectorZCUPVFCid26 : 28|1@0+ (1,0) [0|1] "" IHU
 SG_ VFCVectorZCUPVFCid27 : 29|1@0+ (1,0) [0|1] "" IHU
 SG_ VFCVectorZCUPVFCid28 : 30|1@0+ (1,0) [0|1] "" IHU
 SG_ VFCVectorZCUPVFCid29 : 31|1@0+ (1,0) [0|1] "" IHU
 SG_ VFCVectorZCUPVFCid3 : 5|1@0+ (1,0) [0|1] "" IHU
 SG_ VFCVectorZCUPVFCid30 : 32|1@0+ (1,0) [0|1] "" IHU
 SG_ VFCVectorZCUPVFCid31 : 33|1@0+ (1,0) [0|1] "" IHU
 SG_ VFCVectorZCUPVFCid32 : 34|1@0+ (1,0) [0|1] "" IHU
 SG_ VFCVectorZCUPVFCid33 : 35|1@0+ (1,0) [0|1] "" IHU
 SG_ VFCVectorZCUPVFCid34 : 36|1@0+ (1,0) [0|1] "" IHU
 SG_ VFCVectorZCUPVFCid35 : 37|1@0+ (1,0) [0|1] "" IHU
 SG_ VFCVectorZCUPVFCid36 : 38|1@0+ (1,0) [0|1] "" IHU
 SG_ VFCVectorZCUPVFCid37 : 39|1@0+ (1,0) [0|1] "" IHU
 SG_ VFCVectorZCUPVFCid38 : 40|1@0+ (1,0) [0|1] "" IHU
 SG_ VFCVectorZCUPVFCid39 : 41|1@0+ (1,0) [0|1] "" IHU
 SG_ VFCVectorZCUPVFCid4 : 6|1@0+ (1,0) [0|1] "" IHU
 SG_ VFCVectorZCUPVFCid40 : 42|1@0+ (1,0) [0|1] "" IHU
 SG_ VFCVectorZCUPVFCid41 : 43|1@0+ (1,0) [0|1] "" IHU
 SG_ VFCVectorZCUPVFCid42 : 44|1@0+ (1,0) [0|1] "" IHU
 SG_ VFCVectorZCUPVFCid43 : 45|1@0+ (1,0) [0|1] "" IHU
 SG_ VFCVectorZCUPVFCid44 : 46|1@0+ (1,0) [0|1] "" IHU
 SG_ VFCVectorZCUPVFCid45 : 47|1@0+ (1,0) [0|1] "" IHU
 SG_ VFCVectorZCUPVFCid46 : 48|1@0+ (1,0) [0|1] "" IHU
 SG_ VFCVectorZCUPVFCid47 : 49|1@0+ (1,0) [0|1] "" IHU
 SG_ VFCVectorZCUPVFCid48 : 50|1@0+ (1,0) [0|1] "" IHU
 SG_ VFCVectorZCUPVFCid49 : 51|1@0+ (1,0) [0|1] "" IHU
 SG_ VFCVectorZCUPVFCid5 : 7|1@0+ (1,0) [0|1] "" IHU
 SG_ VFCVectorZCUPVFCid50 : 52|1@0+ (1,0) [0|1] "" IHU
 SG_ VFCVectorZCUPVFCid51 : 53|1@0+ (1,0) [0|1] "" IHU
 SG_ VFCVectorZCUPVFCid52 : 54|1@0+ (1,0) [0|1] "" IHU
 SG_ VFCVectorZCUPVFCid53 : 55|1@0+ (1,0) [0|1] "" IHU
 SG_ VFCVectorZCUPVFCid54 : 56|1@0+ (1,0) [0|1] "" IHU
 SG_ VFCVectorZCUPVFCid55 : 57|1@0+ (1,0) [0|1] "" IHU
 SG_ VFCVectorZCUPVFCid56 : 58|1@0+ (1,0) [0|1] "" IHU
 SG_ VFCVectorZCUPVFCid57 : 59|1@0+ (1,0) [0|1] "" IHU
 SG_ VFCVectorZCUPVFCid58 : 60|1@0+ (1,0) [0|1] "" IHU
 SG_ VFCVectorZCUPVFCid59 : 61|1@0+ (1,0) [0|1] "" IHU
 SG_ VFCVectorZCUPVFCid6 : 8|1@0+ (1,0) [0|1] "" IHU
 SG_ VFCVectorZCUPVFCid60 : 62|1@0+ (1,0) [0|1] "" IHU
 SG_ VFCVectorZCUPVFCid61 : 63|1@0+ (1,0) [0|1] "" IHU
 SG_ VFCVectorZCUPVFCid7 : 9|1@0+ (1,0) [0|1] "" IHU
 SG_ VFCVectorZCUPVFCid8 : 10|1@0+ (1,0) [0|1] "" IHU
 SG_ VFCVectorZCUPVFCid9 : 11|1@0+ (1,0) [0|1] "" IHU

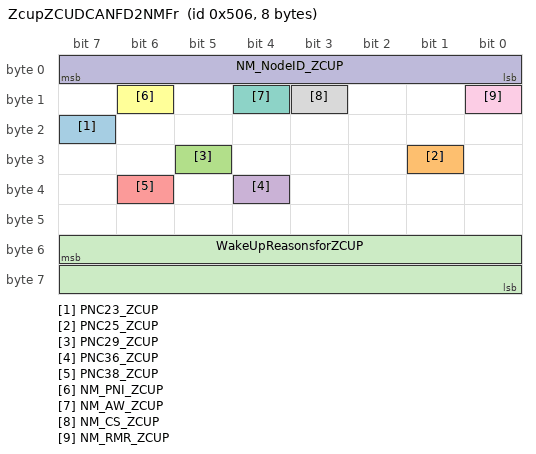
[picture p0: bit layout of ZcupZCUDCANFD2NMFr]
BO_ 1286 ZcupZCUDCANFD2NMFr : 8 ZCUP
 SG_ PNC23_ZCUP : 23|1@0+ (1,0) [0|0] "" Vector__XXX
 SG_ PNC25_ZCUP : 25|1@0+ (1,0) [0|0] "" Vector__XXX
 SG_ PNC29_ZCUP : 29|1@0+ (1,0) [0|0] "" Vector__XXX
 SG_ PNC36_ZCUP : 36|1@0+ (1,0) [0|0] "" Vector__XXX
 SG_ PNC38_ZCUP : 38|1@0+ (1,0) [0|0] "" Vector__XXX
 SG_ NM_PNI_ZCUP : 14|1@0+ (1,0) [0|0] "" Vector__XXX
 SG_ NM_AW_ZCUP : 12|1@0+ (1,0) [0|0] "" Vector__XXX
 SG_ NM_CS_ZCUP : 11|1@0+ (1,0) [0|0] "" Vector__XXX
 SG_ NM_RMR_ZCUP : 8|1@0+ (1,0) [0|0] "" Vector__XXX
 SG_ NM_NodeID_ZCUP : 7|8@0+ (1,0) [0|0] "" Vector__XXX

 SG_ WakeUpReasonsforZCUP : 55|16@0+ (1,0) [0|65535] "" Vector__XXX

CM_ SG_ 441 AjarChrgLidRearSwitch "AjarChrgLidRearSwitch - Rear Charge Lid Switch status
Ukwn - Unknown status
Opend - Opened
Clsd - Closed";
CM_ SG_ 441 AjarFuelFlapSwitch "AjarFuelFlapSwitch - Fuel Flap Switch status

Ukwn - Unknown status
Opend - Opened
Clsd - Closed";
CM_ SG_ 441 CarTiIntForClima "CCM internal mirror of CarTiGlb. Keeps counting when the bus signal is not available.";
CM_ SG_ 441 ClimaCmptSts "Compartment climate status.";
CM_ SG_ 441 ClimaCtrlActv "ClimaCtrlActv";
CM_ SG_ 441 ClimaDefrstSts "Defrost status.";
CM_ SG_ 441 ClimaEstimdTForHeat "Clima Estimd T For Heat";
CM_ SG_ 441 ClimaEstimdTForReHeat "Clima Estimd TFor Re Heat";
CM_ SG_ 441 CmptmtAirTEstimdAtRowFirstLoResl "Estimated compartment temperature at head level, first row";
CM_ SG_ 441 CoupldCtrlErrAtRowFirstLe "Front left coupling control error";
CM_ SG_ 441 CoupldCtrlErrAtRowFirstRi "Front Right coupling control error";
CM_ SG_ 441 CoupldCtrlErrAtRowSecLe "Second row left coupling control error";
CM_ SG_ 441 CoupldCtrlErrAtRowSecRi "Second row Right coupling control error";
CM_ SG_ 441 DoorPass2Swt1DplyHndl "Door Pass 2 Switch solution deployable handle [Switch 1]
Psd - Pressed = 0
NotPsd - Not Pressed = 1";
CM_ SG_ 441 DoorPass2Swt2DplyHndl "Door Pass 2 Switch solution deployable handle [Switch 2]
Psd - Pressed = 0
NotPsd - Not Pressed = 1";
CM_ SG_ 441 DoorPassLatPosn "Passenger door Cinch position. x01 equal fully open, x02 equal secondary position, x03 equal fully closed.";
CM_ SG_ 441 DoorPassRe2Sw1DplyHndl "Door Passenger Rear 2 Switch solution deployable handle [Switch 1]";
CM_ SG_ 441 DoorPassRe2Sw2DplyHndl "Door Passenger Rear 2 Switch solution deployable handle [Switch 2]";
CM_ SG_ 441 DrvrSeatHeatgPwrAllwd "Power limitation for driver seat climatization.";
CM_ SG_ 441 DrvrSeatVentnPwrAllwd "Allowed driver seat ventilation power.";
CM_ SG_ 441 EngSpdIncIdleForClima "Request to increase idle speed. Used when current engine speed is insufficient for climate comfort";
CM_ SG_ 441 FltOfReRegPlateLamp "Fault of Rear Registration Plate Lamp";
CM_ SG_ 441 FragCh1Id "Fragrance channel 1 ID from climate to Hmi.";
CM_ SG_ 441 FragCh2Id "Fragrance channel 1 ID from climate to Hmi.";
CM_ SG_ 441 FragCh3Id "Fragrance channel 1 ID from climate to Hmi.";
CM_ SG_ 441 FragCh4Id "Fragrance channel 1 ID from climate to Hmi.";
CM_ SG_ 441 FragCh5Id "Fragrance channel 1 ID from climate to Hmi.";
CM_ SG_ 441 HvEgyDesForClima "Desired energy from high voltage system to use for climatisation";
CM_ SG_ 441 IceBreakDoorPassActv "Boolean signal to indicate if Passenger door ice break function is activated";
CM_ SG_ 441 MirrAtPassInMovmt "Informs the Setting Management subsystem that the outer rear view mirrors are in movement. Passanger side.";
CM_ SG_ 441 PassSeatCushDownPosPercSeatPosPerc "Cushion Down Position Percentage";
CM_ SG_ 441 PassSeatCushDownPosPercSeatPosQf "Cushion Down Position Quality Factor";
CM_ SG_ 441 PassSeatFoldFailFb "Passenger Seat Fold fail reason feedback";
CM_ SG_ 441 PassSeatPosPercSeatPosFrntHeiPerc "Front Height Position Percentage";
CM_ SG_ 441 PassSeatPosPercSeatPosFrntHeiQF "Front Height Position Quality Factor";
CM_ SG_ 441 PassSeatPosPercSeatPosHeiPerc "Height Position Percentage";
CM_ SG_ 441 PassSeatPosPercSeatPosHeiQF "Height Position Quality Factor";
CM_ SG_ 441 PassSeatPosPercSeatPosSldPerc "Length Position Percentage";
CM_ SG_ 441 PassSeatPosPercSeatPosSldQF "Length Position Quality Factor";
CM_ SG_ 441 SeatBackAngleRowFirstPass "Backrest angle of the First Row Passenger Seat";
CM_ SG_ 441 SeatOccptAtRowSecPasSide2 "Describes if an occupant is detected in the  seat.";
CM_ SG_ 441 SeatOccptAtRowSecPasSideSnsSts2 "Informs if there is a fault on the driver seat sensor is detected through electrical measurements, or plausibility judgement. NotOk means sensor is judged as faulty. Di means that the sensor is not configured.";
CM_ SG_ 441 SteerWhlHeatgDurgClima "Requests for remote steering wheel heating.";
CM_ SG_ 441 SteerWhlHeatgPwrAllwd "Steering wheel heating power allowed percent.";
CM_ SG_ 801 AmbTEstimdAmbTEstimd "Estimated/filtered/modelled amibient temperature based on information from ambient temp sensor and all other available temperature sensors and vehicle information.  Estimated ambient temperature";
CM_ SG_ 801 AmbTEstimdQf "Estimated/filtered/modelled amibient temperature based on information from ambient temp sensor and all other available temperature sensors and vehicle information.  Quality factor for estimated signal";
CM_ SG_ 801 ClimaOvrHeatPrtSts "Request for climate system to change usage mode from abandon to inactive.";
CM_ SG_ 801 CmptmtAirTEstimdExtdComptmtT "Estimated compartment temperature with quality flag Estimated compartment Temperature";
CM_ SG_ 801 CmptmtAirTEstimdExtdQlyFlg "Estimated compartment temperature with quality flag Quality flag ";
CM_ SG_ 520 AmbTRawAtPassSideAmbTVal "Unfiltered ambient temp raw data in deg C";
CM_ SG_ 520 AmbTRawAtPassSideQly "quality";
CM_ SG_ 520 AmbTURawAtPassSide "Ambient temp raw data in deg C at passenger side";
CM_ SG_ 520 HvacEvaprTSpFrnt "Set value for air temperature after evaporator in front HVAC";
CM_ SG_ 520 RlyCmftForClimaReq "Request to close comfort relay, used by ClimateControl to ensure all wanted sensors and actuators are power supplied.";
CM_ SG_ 520 RlyCrashForClimaReq "Request to activate crash relay in order to have power supply for front blower.";
CM_ SG_ 58 DoorPassOpenLowReqOutdSwt1 "DooPassOpenLowReqOutdSwt1 - Passenger Door Open Request from Outside Switch 1 - Traditional door (No Power operated). Button status of the outside dpassenger door handle switch connection 1.
Psd - Pressed
NotPsd - Not Pressed
NoInfo1/2 - Invalid";
CM_ SG_ 58 DoorPassOpenReqInsdSwt1 "DoorDrvrOpenReqInsdSwt1 - Passenger Door Open Request from Inside Switch 1
Button status of the inside passenger door handle switch connection 1
Psd - Pressed
NotPsd - Not Pressed
NoInfo1/2 - Invalid";
CM_ SG_ 58 DoorPassReCinhIntFailInfCinchFlt1 "Cinch fault";
CM_ SG_ 58 DoorPassReCinhIntFailInfCinchRestFlt "Cinch reset fault";
CM_ SG_ 58 DoorPassReLatPosn "Passenger rear door Cinch position. x01 equal fully open, x02 equal secondary position, x03 equal fully closed.";
CM_ SG_ 58 DoorPassReOpenLowReqOutdSwt1 "Passenger Rear Door Open Request from Outside Switch 1 - Traditional door";
CM_ SG_ 58 DoorPassReOpenReqInsdSwt1 "Passenger Rear Door Open Request from Inside Switch 1";
CM_ SG_ 58 DoorPassReRelsFailCinchOverTimed "Cinch processwas not successfull. It is overtimed.";
CM_ SG_ 58 DoorPassReRelsFailFailure1 "Issue described by requiremnt according to specific project";
CM_ SG_ 58 DoorPassReRelsFailMechRels "Door Mechanical release (No Power operated)";
CM_ SG_ 58 DoorRiReLatPosn "Right rear door Cinch position. x01 equal fully open, x02 equal secondary position, x03 equal fully closed.";
CM_ SG_ 58 DoorRiReOpenLowReqOutdSwt1 "DoorRiReOpenLowReqOutdSwt1 - Right Rear Door Open Request from Outside Switch 1 - Traditional door (No Power operated). Button status of the outside Right Rear door handle switch connection 1.
Psd - Pressed
NotPsd - Not Pressed
NoInfo1/2 - Invalid";
CM_ SG_ 58 DoorRiReOpenReqInsdSwt1 "DoorDrvrOpenReqInsdSwt1 - Right rear Open Request from Inside Switch 1
Button status of the inside Right rear door handle switch connection 1
Psd - Pressed
NotPsd - Not Pressed
NoInfo1/2 - Invalid";
CM_ SG_ 58 IceBreakDoorPassReActv "Boolean signal to indicate if Passenger Rear door ice break function is activated";
CM_ SG_ 310 AutDemstOperSts "Automatic demist operation state";
CM_ SG_ 310 ChdLockPassReSts "Child protection Passenger rear door, child lock status.";
CM_ SG_ 310 ChdLockRightSts "CdhLockgProtnStsAtRiRe - Child Lock Protection Status at Right Rear Door
Indicates child lock status for right rear door
On - Child lock is active
Off - Child lock is not active";
CM_ SG_ 310 ChrgLidDCorAcDctSwtReq "The push-push button which inside the chargelid to request open the lid.";
CM_ SG_ 310 CinhPassReSts "Passenger rear Door cinch Status";
CM_ SG_ 310 CinhPassReSwt "Passenger rear door Cinch switch status";
CM_ SG_ 310 CinhPassSts "passenger door Cinch switch status";
CM_ SG_ 310 CinhPassSwt "passenger door Cinch switch status";
CM_ SG_ 310 ClimaTiOfEnd "Informs of when the last pre-conditioning was ended.";
CM_ SG_ 310 CmptmtTFrntCmptmtTFrnt "Measured temperature in compartment. ";
CM_ SG_ 310 CmptmtTFrntFanForCmptmtTRunng "Fan for component temperature requirement.";
CM_ SG_ 310 CmptmtTFrntQf "Component temperature sensor signal quality.";
CM_ SG_ 310 DoorPassReHndlSts "To inform about Passenger rear door handle status";
CM_ SG_ 310 EvaprTFrntEvaprTFrnt "Air temperature measured in HVAC after evaporator";
CM_ SG_ 310 EvaprTFrntEvaprTQf "Air temperature measured in HVAC after evaporator signal quality.";
CM_ SG_ 310 FltOfBeamHiPass "Fault status of high beam of passenger side";
CM_ SG_ 310 FltOfBeamLoPass "Fault status of low beam of passenger side";
CM_ SG_ 310 FltOfDaytiRunngLampPass "Fault status of DRL Lamp of passenger side";
CM_ SG_ 310 FltOfFrntFogLampPass "Fault status of front fog Lamp of passenger side";
CM_ SG_ 310 FltOfFrntPosnLampPass "Fault status of front position Lamp of passenger side";
CM_ SG_ 310 FltOfReFogLampDrv "Fault status of rear fog Lamp of driver side";
CM_ SG_ 310 FltOfRePosnLampPass "Fault status of rear position Lamp of passenger side";
CM_ SG_ 310 FltOfRvsgLampPass "Fault status of reverse Lamp of passenger side";
CM_ SG_ 310 HvacCoolgEnaRe "Request cooling for rear HVAC";
CM_ SG_ 310 HvahAirTEstmdEvaprTFrnt "Actual air temperature after rear evaporator.";
CM_ SG_ 310 HvahAirTEstmdEvaprTQf "Actual air temperature quality flag after rear evaporator.";
CM_ SG_ 310 IceBreakDoorRiReActv "Boolean signal to indicate if Right Rear door ice break function is activated";
CM_ SG_ 310 IntPm25StsFrmClima "Interior Pm 2.5 sensor status feedback.";
CM_ SG_ 310 MirrDwnStsAtPass "Reports the status of the mirror dipping mode. Passanger side.";
CM_ SG_ 310 MirrPosnToSetTarPosnAtPassMirrPosnAdjCldLeRi "Mirror Left-Right Position are send to Setting subsystem for the target position.";
CM_ SG_ 310 MirrPosnToSetTarPosnAtPassMirrPosnAdjCldUpDwn "Mirror Up-Down Position are send to Setting subsystem for the target position.";
CM_ SG_ 310 OpenPassReSwt "Passenger rear door open switch status";
CM_ SG_ 310 OpenPassSwt "passenger door open switch status";
CM_ SG_ 310 PassSeatBtnPsd "The signal PassSeatBtnPsd shall be sent when any button connected to the PSM is activated. ";
CM_ SG_ 310 PassSeatFoldSts "Status signal for the Passenger Seat Fold or Raise";
CM_ SG_ 310 PassSeatInAutMovmt "Passenger Seat in Automatic Movement";
CM_ SG_ 310 PassSeatPosFrntExtPercSeatPosPerc "Front Extension Position Percentage";
CM_ SG_ 310 PassSeatPosFrntExtPercSeatPosQf "Front Extension Position Quality Factor";
CM_ SG_ 310 PawlPassReSwt "Passenger rear door pawl switch status";
CM_ SG_ 310 PawlPassSwt "passenger door pawl switch status";
CM_ SG_ 310 SecRowLeSeatHeatgPwrAllwd "Power limitation for second row left seat climatization.";
CM_ SG_ 310 SecRowLeSeatVentnPwrAllwd "Allowed second row left seat ventilation power.";
CM_ SG_ 310 SecRowRiSeatHeatgPwrAllwd "Power limitation for second row right seat climatization.";
CM_ SG_ 310 SecRowRiSeatVentnPwrAllwd "Allowed second row right seat ventilation power.";
CM_ SG_ 310 ShortDropWinPassSts "Short drop a status sent back to locking to secure window is down and door is ready to be released. ";
CM_ SG_ 310 ShortDropWinReRiSts "Short drop a status sent back to locking to secure window is down and door is ready to be released. ";
CM_ SG_ 310 ThrdRowLeSeatHeatgPwrAllwd "Power limitation for second row left seat climatization.";
CM_ SG_ 310 ThrdRowLeSeatVentnPwrAllwd "Allowed third row left seat ventilation power.";
CM_ SG_ 310 ThrdRowRiSeatHeatgPwrAllwd "Power limitation for third row right seat climatization.";
CM_ SG_ 310 ThrdRowRiSeatVentnPwrAllwd "Allowed third row right seat ventilation power.";
CM_ SG_ 310 WinDsblPassReSts "Signal sent from the rear passenger door module to the Driver door module that informs of the local status of the power window disable functionality.";
CM_ SG_ 310 WinDsblRightSts "Signal sent from the rear passenger door module to the Driver door module that informs of the local status of the power window disable functionality.
";
CM_ SG_ 310 WinFailrStsAtPassRe "Report failure if Window motor is not possible to Run";
CM_ SG_ 310 WinPosnStsAtPassRe "Signal sent to inform the rest of the car of the window position status for the rear passenger side door. The value of the signal is either an approximated percentage of openness, of the window is moving or if the position is unkown.";
CM_ SG_ 1184 CmptmtIntrMtrlTEstimdMtrlSnsrT "Material temperature";
CM_ SG_ 1184 CmptmtIntrMtrlTEstimdMtrlSnsrTQly2 "Materical quality flag";
CM_ SG_ 1184 EgyDesForClima "Desired energy to use for climatisation";
CM_ SG_ 1184 ElecVentnMotPwrCnsAct "Electrical ventilation motor actual power consumption.";
CM_ SG_ 1184 ElecVentnMotPwrCnsDes "Electrical ventilation motor estimated power consumption.";
CM_ SG_ 1184 HvacDefrstFlapActlPosn "Defrost actual flap position.";
CM_ SG_ 1184 HvacFanSet2HvacFanSpd2 "Fan speed.";
CM_ SG_ 1184 HvacHeatElmAirMFlowEstimd "Estimated total mass air flow in front HVAC heater element. ";
CM_ SG_ 1184 HvacModFlapActlPosnFrstRowLe "Vent actual flap position for first row.";
CM_ SG_ 1184 HvacModFlapActlPosnFrstRowRi "Floor actual flap position for first row.";
CM_ SG_ 1184 HvacModFlapActlPosnSecRowLe "Vent actual flap position for second row.";
CM_ SG_ 1184 HvacModFlapActlPosnSecRowRi "Floor actual flap position for second row.";
CM_ SG_ 1184 HvacOsaFlapActlPosn "OSA actual flap position.";
CM_ SG_ 1184 HvacRecFlapActlPosn "Recirculation actual flap position.";
CM_ SG_ 1184 OutdAirQlyOutdAirQly "OutSide Air Quality";
CM_ SG_ 1184 OutdAirQlyQf "Quality Factor OutSide Air Quality";
CM_ SG_ 1184 OutdPm25StsFrmClima "Outside Pm 2.5 sensor status feedback.";
CM_ SG_ 1184 PassSeatHeatgActlPwrCns "Actual power consumption for passenger seat climate, including ventilation and heating.";
CM_ SG_ 1184 PassSeatHeatgDesPwrCns "Desired power consumption for passenger seat climate, including ventilation and heating.";
CM_ SG_ 1184 PassSeatHeatgPwrAllwd "Power limitation for passenger seat climatization.";
CM_ SG_ 1184 PassSeatVentnActlPwrCns "Passenger seat ventilation actual power consumption.";
CM_ SG_ 1184 PassSeatVentnDesPwrCns "Passenger seat ventilation desired power consumption.";
CM_ SG_ 1184 PassSeatVentnPwrAllwd "Allowed passenger seat ventilation power.";
CM_ SG_ 1184 PwrAllwdForElecAirVentn "Power allowed for electrical ventilation motor.";
CM_ SG_ 1184 SunDataAzi "Sun azimuth angle.";
CM_ SG_ 1184 SunDataElevn "Sun elevation angle";
CM_ SG_ 1184 TgtHvacAirTForRowFirstLe "First row left target outlet air temperature.";
CM_ SG_ 1184 TgtHvacAirTForRowFirstRi "First row right target outlet air temperature.";
CM_ SG_ 1184 TgtHvacAirTForRowSecLe "Second row left target outlet air temperature.";
CM_ SG_ 1184 TgtHvacAirTForRowSecRi "Second row right target outlet air temperature.";
CM_ SG_ 600 CcmElecAirDirCrtlReqDrvrLePosX "VGA position for HMI";
CM_ SG_ 600 CcmElecAirDirCrtlReqDrvrLePosY "VGA position for HMI";
CM_ SG_ 600 CcmElecAirDirCrtlReqDrvrRiPosX "VGA position for HMI";
CM_ SG_ 600 CcmElecAirDirCrtlReqDrvrRiPosY "VGA position for HMI";
CM_ SG_ 600 CcmElecAirDirCrtlReqPassLePosX "VGA position for HMI";
CM_ SG_ 600 CcmElecAirDirCrtlReqPassLePosY "VGA position for HMI";
CM_ SG_ 600 CcmElecAirDirCrtlReqPassRiPosX "VGA position for HMI";
CM_ SG_ 600 CcmElecAirDirCrtlReqPassRiPosY "VGA position for HMI";
CM_ SG_ 600 ClimaActv "Informs if a parking climatisation is active (either pre- or post conditioning).";
CM_ SG_ 600 ElecAirVentnAvlSts "Electrical air ventilation motor on, off, error status.";
CM_ SG_ 600 ElecDefrstReqMirrDefrstReq "Request to activate electric defrosters.  Mirror defroster request";
CM_ SG_ 600 ElecDefrstReqWinDefrstFrntReq "Request to activate electric defrosters.  Windscreen defroster request";
CM_ SG_ 600 ElecDefrstReqWinDefrstReReq "Request to activate electric defrosters.  Rear window defroster request";
CM_ SG_ 600 EvaprTReEvaprTFrnt "Actual air temperature after rear evaporator.";
CM_ SG_ 600 EvaprTReEvaprTQf "Actual air temperature quality flag after rear evaporator.";
CM_ SG_ 600 FragCh1UseUpWrn "To remind customer the fragrance channel 1 use up.";
CM_ SG_ 600 FragCh2UseUpWrn "To remind customer the fragrance channel 2 use up.";
CM_ SG_ 600 FragCh3UseUpWrn "To remind customer the fragrance channel 3 use up.";
CM_ SG_ 600 FragCh4UseUpWrn "To remind customer the fragrance channel 4 use up.";
CM_ SG_ 600 FragCh5UseUpWrn "To remind customer the fragrance channel 5 use up.";
CM_ SG_ 600 FragLvlFrmClima "Fragrance level status from climate.";
CM_ SG_ 600 FragStsFrmClima "Fragrance use up and error warn from climate to Hmi.";
CM_ SG_ 600 HvacEvaprTSpRe "Set value for air temperature after evaporator in rear HVAC";
CM_ SG_ 600 IntPm25HiPopUp "Inside PM2.5 value high warning for IHU to Pop up.";
CM_ SG_ 600 PassSeatVentAvlSts "Seat ventilation on, off, error and limitation status for passenger seat.";
CM_ SG_ 600 PrkgClimaWarn "Informs if anything has gone wrong with the parking climatisation.";
CM_ SG_ 600 SeatClimaDurgClimaHmiSeatHeatgForRowFirstLe "Seat heating status for first row left seat";
CM_ SG_ 600 SeatClimaDurgClimaHmiSeatHeatgForRowFirstRi "Seat heating status for first row right seat.";
CM_ SG_ 600 SeatClimaDurgClimaHmiSeatHeatgForRowSecLe "Seat heating status for second row left status.";
CM_ SG_ 600 SeatClimaDurgClimaHmiSeatHeatgForRowSecRi "Seat heating status for second row right seat.";
CM_ SG_ 600 SeatClimaDurgClimaHmiSeatVentnForRowFirstLe "Seat ventialtion status for first row left seat";
CM_ SG_ 600 SeatClimaDurgClimaHmiSeatVentnForRowFirstRi "Seat ventilation status for first row right";
CM_ SG_ 600 SeatClimaDurgClimaHmiSeatVentnForRowSecLe "Seat ventilation status for second row left";
CM_ SG_ 600 SeatClimaDurgClimaHmiSeatVentnForRowSecRi "Seat ventilation status for second row right";
CM_ SG_ 803 CcmRollgCntrSts "Ccm round counter signal to indicate CCM busoff status.";
CM_ SG_ 803 ClimaCoolgReqLvl "Climatization cooling level request.";
CM_ SG_ 803 ClimaHeatgReqLvl "Climatization heating level request.";
CM_ SG_ 803 CmptModForHp "Compartment status for heat pump system. Value is 0x0 vent, 0x1 cool, 0x2 heat, 0x3 cool defog, 0x4 heat defog, 0x5 to 0x255 reserved.";
CM_ SG_ 803 CmptmtTReCmptmtTFrnt "Rear incar temperature.";
CM_ SG_ 803 CmptmtTReCmptmtTFrntQf "Rear incar temperature quality flag";
CM_ SG_ 803 CmptmtTReFanForCmptmtTRunng "Fan for component temperature requirement.";
CM_ SG_ 803 DvlpFrameForCCMByte0 "Reserved developing frame byte0 for CCM.";
CM_ SG_ 803 DvlpFrameForCCMByte1 "Reserved developing frame byte1 for CCM.";
CM_ SG_ 803 DvlpFrameForCCMByte2 "Reserved developing frame byte2 for CCM.";
CM_ SG_ 803 DvlpFrameForCCMByte3 "Reserved developing frame byte3 for CCM.";
CM_ SG_ 803 DvlpFrameForCCMByte4 "Reserved developing frame byte4 for CCM.";
CM_ SG_ 803 DvlpFrameForCCMByte5 "Reserved developing frame byte5 for CCM.";
CM_ SG_ 803 DvlpFrameForCCMByte6 "Reserved developing frame byte6 for CCM.";
CM_ SG_ 803 DvlpFrameForCCMByte7 "Reserved developing frame byte7 for CCM.";
CM_ SG_ 803 FrntHvacBlowerSts "Front blower status.";
CM_ SG_ 803 HeatrAirTReq "Heater air temperature request.";
CM_ SG_ 803 HpReqCritSts "Heat pump critical request status.";
CM_ SG_ 803 HvacAirMFlowEstimd "Estimated total mass air flow in front HVAC. ";
CM_ SG_ 803 HvacAirMFlowReEstimd "Estimated total mass air flow in rear HVAC.";
CM_ SG_ 803 HvacAirTForRowFirstAtFlrLeEvaprTFrnt "First row left floor air temperature.";
CM_ SG_ 803 HvacAirTForRowFirstAtFlrLeEvaprTQf "First row left floor air temperature quality flag.";
CM_ SG_ 803 HvacAirTForRowFirstAtFlrRiEvaprTFrnt "First row right floor air temperature.";
CM_ SG_ 803 HvacAirTForRowFirstAtFlrRiEvaprTQf "First row right floor air temperature quality flag";
CM_ SG_ 803 HvacAirTForRowFirstAtVentLeEvaprTFrnt "First row left ventilation air temperature.";
CM_ SG_ 803 HvacAirTForRowFirstAtVentLeEvaprTQf "First row left ventilation air temperature quality flag.";
CM_ SG_ 803 HvacAirTForRowFirstAtVentRiEvaprTFrnt "First row right ventilation air temperature.";
CM_ SG_ 803 HvacAirTForRowFirstAtVentRiEvaprTQf "First row right ventilation air temperature quality flag";
CM_ SG_ 803 HvacAirTForRowSecAtFlrLeEvaprTFrnt "Second row left floor air temperature.";
CM_ SG_ 803 HvacAirTForRowSecAtFlrLeEvaprTQf "Second row left floor air temperature quality flag.";
CM_ SG_ 803 HvacAirTForRowSecAtFlrRiEvaprTFrnt "Second row right floor air temperature.";
CM_ SG_ 803 HvacAirTForRowSecAtFlrRiEvaprTQf "Second row right floor air temperature quality flag.";
CM_ SG_ 803 HvacAirTForRowSecAtVentLeEvaprTFrnt "Second row left ventilation air temperature.";
CM_ SG_ 803 HvacAirTForRowSecAtVentLeEvaprTQf "Second row left ventilation air temperature quality flag.";
CM_ SG_ 803 HvacAirTForRowSecAtVentRiEvaprTFrnt "Second row right ventilation air temperature.";
CM_ SG_ 803 HvacAirTForRowSecAtVentRiEvaprTQf "Second row right ventilation air temperature quality flag.";
CM_ SG_ 803 HvacAirTForRowThrdAtFlrRiEvaprTFrnt "Third row right floor air temperature.";
CM_ SG_ 803 HvacAirTForRowThrdAtFlrRiEvaprTQf "Third row right floor air temperature quality flag";
CM_ SG_ 803 HvacAirTForRowThrdAtVentRiEvaprTFrnt "Third row right ventilation air temperature.";
CM_ SG_ 803 HvacAirTForRowThrdAtVentRiEvaprTQf "Third row right ventilation air temperature quality flag";
CM_ SG_ 803 HvacCondsorTEvaprTFrnt "heat pump inner condensor actual temperature.";
CM_ SG_ 803 HvacCondsorTEvaprTQf "heat pump inner condensor actual temperature quality flag.";
CM_ SG_ 803 HvacCondsorTspEvaprTFrnt "heat pump inner condensor target temperture.";
CM_ SG_ 803 HvacCondsorTspEvaprTQf "heat pump inner condensor target temperture signal quality.";
CM_ SG_ 803 HvacHeatrInletTempReqEvaprTFrnt "Front evaporator temperature.";
CM_ SG_ 803 HvacHeatrInletTempReqEvaprTQf "Front evaporator signal quality.";
CM_ SG_ 803 HvacOsaAndRecActrQfForHp "Recirculation ratio for HVAC from CCM to Heatpump.";
CM_ SG_ 803 HvacTempFlapActlPosnFrstRowLe "Left temperature actual flap position for first row.";
CM_ SG_ 803 HvacTempFlapActlPosnFrstRowRi "Right temperature actual flap position for first row.";
CM_ SG_ 803 HvacTempFlapActlPosnSecRowLe "Left temperature actual flap position for second row.";
CM_ SG_ 803 HvacTempFlapActlPosnSecRowRi "Right temperature actual flap position for second row.";
CM_ SG_ 803 HvahHeatgReq "HVAH heater heating enable.";
CM_ SG_ 803 HvahPwrReq "HVAH power consumption request.";
CM_ SG_ 803 MirrDefrstAtPassSts "Status signal exterior rear view mirror electrical defroster passenger side.";
CM_ SG_ 803 ReHvacBlowerSts "Rear HVAC blower status.";
CM_ SG_ 803 ReHvacHexAirTHvacAirTForHeatrFrnt "Rear HVAC heater exchange temerature value.";
CM_ SG_ 803 ReHvacHexAirTHvacAirTForHeatrFrntQf "Rear HVAC heater exchange temerature value quality flag";
CM_ SG_ 803 RemClimaActv "Remote climate start status.";
CM_ SG_ 803 ResrvdSigForECM1 "Reserved signal 1 for ECM.";
CM_ SG_ 803 ResrvdSigForECM2 "Reserved signal 2 for ECM.";
CM_ SG_ 803 ResrvdSigForECM3 "Reserved signal 3 for ECM.";
CM_ SG_ 803 ResrvdSigForECM4 "Reserved signal 4 for ECM.";
CM_ SG_ 803 TiOfDeactvnForClimaCtrl "Time since last deactivation of climate control. Freezes at activation of climate control.";
CM_ SG_ 803 UBoostReqByClima "Request of extra voltage to boost HVAC fan speed level";
CM_ SG_ 643 CdsParkgClimaActv "CDS parking climatization activation status.";
CM_ SG_ 643 ClimaOvrHeatProActv "Over heat protection function activation status.";
CM_ SG_ 643 CmptmtAirDistbnRspAirDistbnDrvr "Air Distribution for driver";
CM_ SG_ 643 CmptmtAirDistbnRspAirDistbnPass "Air Distribution for passenger";
CM_ SG_ 643 CmptmtAirDistbnRspAirDistbnSecLe "Air Distribution for second left";
CM_ SG_ 643 CmptmtAirDistbnRspAirDistbnSecRi "Air Distribution for second right";
CM_ SG_ 643 CmptmtAirDistbnRspAirDistbnThrd "Air Distribution for third floor";
CM_ SG_ 643 DoorPassCinhIntFailInfCinchFlt1 "Cinch fault";
CM_ SG_ 643 DoorPassCinhIntFailInfCinchRestFlt "Cinch reset fault";
CM_ SG_ 643 DoorPassRelsFailCinchOverTimed "Cinch processwas not successfull. It is overtimed.";
CM_ SG_ 643 DoorPassRelsFailFailure1 "Issue described by requiremnt according to specific project";
CM_ SG_ 643 DoorPassRelsFailMechRels "Door Mechanical release (No Power operated)";
CM_ SG_ 643 DoorRiReCinhIntFailInfCinchFlt1 "Cinch fault";
CM_ SG_ 643 DoorRiReCinhIntFailInfCinchRestFlt "Cinch reset fault";
CM_ SG_ 643 DoorRiReRelsFailCinchOverTimed "Cinch processwas not successfull. It is overtimed.";
CM_ SG_ 643 DoorRiReRelsFailFailure1 "Issue described by requiremnt according to specific project";
CM_ SG_ 643 DoorRiReRelsFailMechRels "Door Mechanical release (No Power operated)";
CM_ SG_ 643 HvacAirTForMaxTZoneEvaprTFrnt "hvac outlet temp in max temp zone.";
CM_ SG_ 643 HvacAirTForMaxTZoneEvaprTQf "hvac outlet temp in max temp zone Of";
CM_ SG_ 643 HvacHeatgReq "Hvac heating request";
CM_ SG_ 643 HvahAirTsp "Air temperature target temperature at outlet of HVAH. Only used by EF1E.";
CM_ SG_ 643 IntPm25LvlFrmClima "Inside PM 2.5 level of compartment.";
CM_ SG_ 643 IntPm25VluFrmClima "Inside PM 2.5 value of compartment.";
CM_ SG_ 643 OutdPm25LvlFrmClima "Outside PM 2.5 level of compartment.";
CM_ SG_ 643 OutdPm25VluFrmClima "Outside PM2.5 value of compartment.";
CM_ SG_ 643 PassSeatHeatgAutoSts "Automatic status feedback signal for seats heating of first row right.";
CM_ SG_ 643 PassSeatHeatgAvlSts "Seat heating on, off, error and limitation status for passenger seat.";
CM_ SG_ 643 PassSeatVentnAutoSts "Automatic status feedback signal for seats ventilation of first row right.";
CM_ SG_ 643 RemClimaDefrstSts "Feedback remote defrost status to HMI/Telematics";
CM_ SG_ 643 RemClimaHvSts "Climate request high voltage status.";
CM_ SG_ 643 RemVentActvSts "Report remote ventilation activation status.";
CM_ SG_ 643 RemVentReqRspnFb "Feedback to telematics whether receive remote ventilation activate/deactivate successfully.";
CM_ SG_ 643 RemVentWarnSts "Reporting actuator or energy errors during RemVent ";
CM_ SG_ 643 TgtHvacAirTForMaxTZone "Target hvac Air temperature for max Temp zone.";
CM_ SG_ 643 WinFailrStsAtPass "Report failure if Window motor is not possible to Run";
CM_ SG_ 643 WinFailrStsAtReRi "Report failure if Window motor is not possible to Run";
CM_ SG_ 882 ClimaActvAlrmSts "Siignal to inform IMS (Interior Motion Sensor) that some kind of climatisation/heating/cooling/fan running activity is ongoing.";
CM_ SG_ 882 HvacHexAirTHvacAirTForHeatrFrnt "Temperature";
CM_ SG_ 882 HvacHexAirTHvacAirTForHeatrFrntQf "Interpretation: 
SnsrDataNotOk - The accuracy of the data is undefinable
SnrsDataOk - The data is calculated with the specified accuracy";
CM_ SG_ 882 HwRowFrstPassFrntExtMotCtrl "Passenger Seat Front Extension Motor Control signal";
CM_ SG_ 882 HwRowFrstPassFrntHeiMotCtrl "Passenger Seat Front Height Motor Control signal";
CM_ SG_ 882 HwRowFrstPassHeiMotCtrl "Passenger Seat Height Motor Control signal";
CM_ SG_ 882 HwRowFrstPassInclMotCtrl "Passenger Seat Inclination Motor Control signal";
CM_ SG_ 882 HwRowFrstPassSldMotCtrl "Passenger Seat Slide Motor Control signal";
CM_ SG_ 882 IntrLiAmb1BnIngrd "Blue ingredient of signal";
CM_ SG_ 882 IntrLiAmb1GrnIngrd "Green ingredient of signal";
CM_ SG_ 882 IntrLiAmb1Intensty "Intensity signal";
CM_ SG_ 882 IntrLiAmb1RedIngrd "Red ingredient of signal";
CM_ SG_ 882 IntrLiAmb1SelCmd1 "Select command for the first 8 nodes";
CM_ SG_ 882 IntrLiAmb1SelCmd2 "Select command for the second group of 8 nodes";
CM_ SG_ 882 IntrLiAmb1SynchDelay "Signal for synchronization between both LIN buses.";
CM_ SG_ 882 IntrLiAmb1TargetTransitionTime "Delay in 20 ms increments";
CM_ SG_ 882 IntrLiAmb1Trigger "Signal used as a go signal for the ALM cluster";
CM_ SG_ 882 IntrLiAmb1Update "1 Used to update data in ALM. 0 Used to ignore received data.";
CM_ SG_ 882 IntrLiAmb2BnIngrd "Blue ingredient of signal";
CM_ SG_ 882 IntrLiAmb2GrnIngrd "Green ingredient of signal";
CM_ SG_ 882 IntrLiAmb2Intensty "Intensity signal";
CM_ SG_ 882 IntrLiAmb2RedIngrd "Red ingredient of signal";
CM_ SG_ 882 IntrLiAmb2SelCmd1 "Select command for the first 8 nodes";
CM_ SG_ 882 IntrLiAmb2SelCmd2 "Select command for the second group of 8 nodes";
CM_ SG_ 882 IntrLiAmb2SynchDelay "Signal for synchronization between both LIN buses.";
CM_ SG_ 882 IntrLiAmb2TargetTransitionTime "Delay in 20 ms increments";
CM_ SG_ 882 IntrLiAmb2Trigger "Signal used as a go signal for the ALM cluster";
CM_ SG_ 882 IntrLiAmb2Update "1 is Used to update data in ALM and  0 is Used to ignore received data.";
CM_ SG_ 882 WinHwSwtPassDoor "Signal from the passenger door hardwired switch to the door control modules containing the state of the window switches.  ";
CM_ SG_ 882 WinHwSwtPassReDoor "Signal from the passenger door hardwired switch to the door control modules containing the state of the window switches. ";
CM_ SG_ 451 BkpOfDstTrvldFromVehCom "Saved backupvalue";
CM_ SG_ 451 CCMFragraCh1AvlTiPrec "Percentage of time available for Channel 1 air fragrances from CCM.";
CM_ SG_ 451 CCMFragraCh2AvlTiPrec "Percentage of time available for Channel 2 air fragrances from CCM.";
CM_ SG_ 451 CCMFragraCh3AvlTiPrec "Percentage of time available for Channel 3 air fragrances from CCM.";
CM_ SG_ 451 CCMFragraCh4AvlTiPrec "Percentage of time available for Channel 4 air fragrances from CCM.";
CM_ SG_ 451 CCMFragraCh5AvlTiPrec "Percentage of time available for Channel 5 air fragrances from CCM.";
CM_ SG_ 451 CCMHvahFltIndcn "HVAH high voltage fault indication from CCM";
CM_ SG_ 451 ClimaOvrHeatProActvSts "Feedback over heat protection function enable/disable.";
CM_ SG_ 451 ClimaPwrCns "Actual current consumption of electric climate loads";
CM_ SG_ 451 ClimaPwrCritDes "Critical power level needed for electric climate loads";
CM_ SG_ 451 ClimaPwrNormDes "Desired power wanted for electric climate loads";
CM_ SG_ 451 DstTrvldVldFromVehCom "Indication if the transmitted backupvalue is valid or not";
CM_ SG_ 451 EcoClimaSts "Eco climate status.";
CM_ SG_ 451 FltOfFrntTurnIndcrLe "Light source failure (open load or short circuit) indication to driver, left front direction indicator.";
CM_ SG_ 451 FltOfFrntTurnIndcrRi "Light source failure (open load or short circuit) indication to driver, right front direction indicator.";
CM_ SG_ 451 FltOfReTurnIndcrLe "Light source failure (open load or short circuit) indication to driver, left rear direction indicator.";
CM_ SG_ 451 FltOfReTurnIndcrRi "Light source failure (open load or short circuit) indication to driver, right rear direction indicator.";
CM_ SG_ 451 FuSnsrActvSideFuLvlSnsrRawVal "Fuel sensor value in ohm from the Active side sensor. Fuel level sensor raw value";
CM_ SG_ 451 FuSnsrActvSideGenQF "Fuel sensor value in ohm from the Passive side sensor QF for fuel level raw sensorn value";
CM_ SG_ 451 FuSnsrPasSideFuLvlSnsrRawVal "Fuel sensor value in ohm from the Passive side sensor Fuel level sensor raw value";
CM_ SG_ 451 FuSnsrPasSideGenQF "Fuel sensor value in ohm from the Passive side sensor QF for fuel level raw sensorn value";
CM_ SG_ 451 HvacFanLvlFbFrnt "Front Hvac Fan level feedback ";
CM_ SG_ 451 HvacFanLvlFbRe "Rear Hvac Fan level feedback";
CM_ SG_ 451 HvacRecircAct "Amount of recirculated air in front HVAC. ";
CM_ SG_ 451 IntLightPasSideDoorSupply "PWM control status signal of Passenger Side step lights illumination";
CM_ SG_ 451 IntLightPasSideSupply "PWM control status signal of Passenger (Front and Rear) Side step lights illumination .";
CM_ SG_ 451 IntLightRePasDoorSupply "PWM control status signal of Passenger Side rear door step lights illumination .";
CM_ SG_ 451 IntLightRePasSideSupply "PWM control status signal of Passenger Rear Side step lights illumination .";
CM_ SG_ 451 PassMassgRunng "Seat Massage Running Row First Passager";
CM_ SG_ 451 PassSeatActvSpplFct "Passenger Seat Active Multifunction (indicates which function is currently controlled by the multifunction switch)";
CM_ SG_ 451 PassSeatHeatgLvlSts "Seat heating level for first row passenger seat.";
CM_ SG_ 451 PassSeatSwtSts2PassSeatSwtAdjmtOfSpplFctHozlSts "Horizontal Multifunction";
CM_ SG_ 451 PassSeatSwtSts2PassSeatSwtAdjmtOfSpplFctVerSts "Vertical Multifunction";
CM_ SG_ 451 PassSeatSwtSts2PassSeatSwtHdrstHozlSts "Headrest Horizontal Status";
CM_ SG_ 451 PassSeatSwtSts2PassSeatSwtHdrstVertSts "Headrest Vertical Status";
CM_ SG_ 451 PassSeatSwtSts2PassSeatSwtHeiFrntSts "Front Height Status";
CM_ SG_ 451 PassSeatSwtSts2PassSeatSwtHeiSts "Height Status";
CM_ SG_ 451 PassSeatSwtSts2PassSeatSwtInclSts "Inclination Status";
CM_ SG_ 451 PassSeatSwtSts2PassSeatSwtSelnOfSpplFctStsSts "Selector Multifunction";
CM_ SG_ 451 PassSeatSwtSts2PassSeatSwtSldSts "Slide Status";
CM_ SG_ 451 PassSeatVentnLvlSts "Seat ventilation level for first row passenger seat.";
CM_ SG_ 451 PwrEstimdAtStbForClima "Estimated power reduction in standby";
CM_ SG_ 258 ClimaSts "Climatisation status";
CM_ SG_ 258 DoorPassHndlSts "To inform about passenger door handle status, i.e. unknown, opened, closed according to
DoorPassHndlSts
- Ukwn
- FullRtrctd
- MovgOut
- StopDurgDply
- FullDplyd
- MovgIn
- StopDurgRtrct
- Flt";
CM_ SG_ 258 DoorPassReLockSts "DoorPassReLockSts - Passenger Rear Door Lock Status";
CM_ SG_ 258 DoorRiReHndlSts "To inform about right rear door handle status, i.e. unknown, opened, closed according to
DoorRiReHndlSts
- Ukwn
- FullRtrctd
- MovgOut
- StopDurgDply
- FullDplyd
- MovgIn
- StopDurgRtrct
- Flt";
CM_ SG_ 258 EngRunngReqByClima "Request from climate control to start engine or inhibit stop. Used maintain a desirable comfort level in compartment.";
CM_ SG_ 258 HvacCoolgEnaFrnt "Request cooling for front HVAC. ";
CM_ SG_ 258 SeatClimaDurgClimaHmiSeatHeatgForRowThrdLe "Used to activate seat heating during parking climatisation.";
CM_ SG_ 258 SeatClimaDurgClimaHmiSeatHeatgForRowThrdRi "Used to activate seat heating during parking climatisation.";
CM_ SG_ 258 SeatClimaDurgClimaHmiSeatVentnForRowThrdLe "Used to activate seat ventilation during parking climatisation.";
CM_ SG_ 258 SeatClimaDurgClimaHmiSeatVentnForRowThrdRi "Used to activate seat ventilation during parking climatisation.";
CM_ SG_ 455 ClimaOffReq "Signal sent from CCM to IHU to request climate off.";
CM_ SG_ 455 ClimaOvrHeatProRspn "Response signal used to notice telematics system that climate control system already receive setting signal for over heat protection from telematics system successfully.";
CM_ SG_ 455 ClimaOvrHeatProWarn "Feedback warning of Over heat protection function";
CM_ SG_ 455 DiDblLock "Disable double lock due to increasing incar carbon dioxide concentration.";
CM_ SG_ 455 RemClimaDelaySts "remote climate delay request status feedback.";
CM_ SG_ 455 RemClimaExtnTiRspn "Remote climate delay time execution response.";
CM_ SG_ 455 RemClimaHvRspn "Remote climate high voltage request receiving response to telematics system.";
CM_ SG_ 455 RemClimaWarn "Remote climate activation failure feedback.";
CM_ SG_ 455 RemStrtClimaRspn "remote start climatization response to telematics.";
CM_ SG_ 455 RoofOpnReqFrmClima "Roof window open request from climate.";
CM_ SG_ 455 SchedCmptHeatCoolFB "Scheduled Climate Status Feedback signal";
CM_ SG_ 455 WinAndRoofReqFrmClima "To request open or close all windows and roof. 0x0: No req; 0x1: Open req; 0x2: Close req.";
CM_ SG_ 51 BodyDataTraceZCUP1Functiondevpsignalgroup1 "ZCUDP internal signal group1.";
CM_ SG_ 51 BodyDataTraceZCUP1Functiondevpsignalgroup2 "ZCUDP internal signal group2.";
CM_ SG_ 51 BodyDataTraceZCUP1Functiondevpsignalgroup3 "ZCUDP internal signal group3.";
CM_ SG_ 51 BodyDataTraceZCUP1Functiondevpsignalgroup4 "ZCUDP internal signal group4.";
CM_ SG_ 51 BodyDataTraceZCUP1Functiondevpsignalgroup5 "ZCUDP internal signal group5.";
CM_ SG_ 51 BodyDataTraceZCUP1Functiondevpsignalgroup6 "ZCUDP internal signal group6.";
CM_ SG_ 51 BodyDataTraceZCUP1Functiondevpsignalgroup7 "ZCUDP internal signal group7.";
CM_ SG_ 51 BodyDataTraceZCUP1Functiondevpsignalgroup8 "ZCUDP internal signal group8.";
CM_ SG_ 51 BodyDataTraceZCUP2Functiondevpsignalgroup1 "ZCUDP internal signal group9.";
CM_ SG_ 51 BodyDataTraceZCUP2Functiondevpsignalgroup2 "ZCUDP internal signal group10.";
CM_ SG_ 51 BodyDataTraceZCUP2Functiondevpsignalgroup3 "ZCUDP internal signal group11.";
CM_ SG_ 51 BodyDataTraceZCUP2Functiondevpsignalgroup4 "ZCUDP internal signal group12.";
CM_ SG_ 51 BodyDataTraceZCUP2Functiondevpsignalgroup5 "ZCUDP internal signal group13.";
CM_ SG_ 51 BodyDataTraceZCUP2Functiondevpsignalgroup6 "ZCUDP internal signal group14.";
CM_ SG_ 51 BodyDataTraceZCUP2Functiondevpsignalgroup7 "ZCUDP internal signal group15.";
CM_ SG_ 51 BodyDataTraceZCUP2Functiondevpsignalgroup8 "ZCUDP internal signal group16.";
CM_ SG_ 51 BodyDataTraceZCUP3Functiondevpsignalgroup1 "ZCUDP internal signal group17.";
CM_ SG_ 51 BodyDataTraceZCUP3Functiondevpsignalgroup2 "ZCUDP internal signal group18.";
CM_ SG_ 51 BodyDataTraceZCUP3Functiondevpsignalgroup3 "ZCUDP internal signal group19.";
CM_ SG_ 51 BodyDataTraceZCUP3Functiondevpsignalgroup4 "ZCUDP internal signal group20.";
CM_ SG_ 51 BodyDataTraceZCUP3Functiondevpsignalgroup5 "ZCUDP internal signal group21.";
CM_ SG_ 51 BodyDataTraceZCUP3Functiondevpsignalgroup6 "ZCUDP internal signal group22.";
CM_ SG_ 51 BodyDataTraceZCUP3Functiondevpsignalgroup7 "ZCUDP internal signal group23.";
CM_ SG_ 51 BodyDataTraceZCUP3Functiondevpsignalgroup8 "ZCUDP internal signal group24.";
CM_ SG_ 51 BodyDataTraceZCUP4Functiondevpsignalgroup1 "ZCUDP internal signal group25.";
CM_ SG_ 51 BodyDataTraceZCUP4Functiondevpsignalgroup2 "ZCUDP internal signal group26.";
CM_ SG_ 51 BodyDataTraceZCUP4Functiondevpsignalgroup3 "ZCUDP internal signal group27.";
CM_ SG_ 51 BodyDataTraceZCUP4Functiondevpsignalgroup4 "ZCUDP internal signal group28.";
CM_ SG_ 51 BodyDataTraceZCUP4Functiondevpsignalgroup5 "ZCUDP internal signal group29.";
CM_ SG_ 51 BodyDataTraceZCUP4Functiondevpsignalgroup6 "ZCUDP internal signal group30.";
CM_ SG_ 51 BodyDataTraceZCUP4Functiondevpsignalgroup7 "ZCUDP internal signal group31.";
CM_ SG_ 51 BodyDataTraceZCUP4Functiondevpsignalgroup8 "ZCUDP internal signal group32.";
CM_ SG_ 51 BodyDataTraceZCUP5Functiondevpsignalgroup1 "ZCUDP internal signal group33.";
CM_ SG_ 51 BodyDataTraceZCUP5Functiondevpsignalgroup2 "ZCUDP internal signal group34.";
CM_ SG_ 51 BodyDataTraceZCUP5Functiondevpsignalgroup3 "ZCUDP internal signal group35.";
CM_ SG_ 51 BodyDataTraceZCUP5Functiondevpsignalgroup4 "ZCUDP internal signal group36.";
CM_ SG_ 51 BodyDataTraceZCUP5Functiondevpsignalgroup5 "ZCUDP internal signal group37.";
CM_ SG_ 51 BodyDataTraceZCUP5Functiondevpsignalgroup6 "ZCUDP internal signal group38.";
CM_ SG_ 51 BodyDataTraceZCUP5Functiondevpsignalgroup7 "ZCUDP internal signal group39.";
CM_ SG_ 51 BodyDataTraceZCUP5Functiondevpsignalgroup8 "ZCUDP internal signal group40.";
CM_ SG_ 51 BodyDataTraceZCUP6Functiondevpsignalgroup1 "ZCUDP internal signal group41.";
CM_ SG_ 51 BodyDataTraceZCUP6Functiondevpsignalgroup2 "ZCUDP internal signal group42.";
CM_ SG_ 51 BodyDataTraceZCUP6Functiondevpsignalgroup3 "ZCUDP internal signal group43.";
CM_ SG_ 51 BodyDataTraceZCUP6Functiondevpsignalgroup4 "ZCUDP internal signal group44.";
CM_ SG_ 51 BodyDataTraceZCUP6Functiondevpsignalgroup5 "ZCUDP internal signal group45.";
CM_ SG_ 51 BodyDataTraceZCUP6Functiondevpsignalgroup6 "ZCUDP internal signal group46.";
CM_ SG_ 51 BodyDataTraceZCUP6Functiondevpsignalgroup7 "ZCUDP internal signal group47.";
CM_ SG_ 51 BodyDataTraceZCUP6Functiondevpsignalgroup8 "ZCUDP internal signal group48.";
CM_ SG_ 51 BodyDataTraceZCUP7Functiondevpsignalgroup1 "ZCUDP internal signal group49.";
CM_ SG_ 51 BodyDataTraceZCUP7Functiondevpsignalgroup2 "ZCUDP internal signal group50.";
CM_ SG_ 51 BodyDataTraceZCUP7Functiondevpsignalgroup3 "ZCUDP internal signal group51.";
CM_ SG_ 51 BodyDataTraceZCUP7Functiondevpsignalgroup4 "ZCUDP internal signal group52.";
CM_ SG_ 51 BodyDataTraceZCUP7Functiondevpsignalgroup5 "ZCUDP internal signal group53.";
CM_ SG_ 51 BodyDataTraceZCUP7Functiondevpsignalgroup6 "ZCUDP internal signal group54.";
CM_ SG_ 51 BodyDataTraceZCUP7Functiondevpsignalgroup7 "ZCUDP internal signal group55.";
CM_ SG_ 51 BodyDataTraceZCUP7Functiondevpsignalgroup8 "ZCUDP internal signal group56.";
CM_ SG_ 1350 VFCVectorZCUPBlockID "BlockID";
CM_ SG_ 1350 VFCVectorZCUPVFCid0 "SettingsComfort";
CM_ SG_ 1350 VFCVectorZCUPVFCid1 "ParkingDrivingClimatization";
CM_ SG_ 1350 VFCVectorZCUPVFCid10 "ExteriorLighting";
CM_ SG_ 1350 VFCVectorZCUPVFCid11 "VFC11";
CM_ SG_ 1350 VFCVectorZCUPVFCid12 "Alarm";
CM_ SG_ 1350 VFCVectorZCUPVFCid13 "VFC13";
CM_ SG_ 1350 VFCVectorZCUPVFCid14 "InteriorLighting";
CM_ SG_ 1350 VFCVectorZCUPVFCid15 "VFC15";
CM_ SG_ 1350 VFCVectorZCUPVFCid16 "Locking";
CM_ SG_ 1350 VFCVectorZCUPVFCid17 "RemoteKeyFunctionality";
CM_ SG_ 1350 VFCVectorZCUPVFCid18 "PropulsionStart";
CM_ SG_ 1350 VFCVectorZCUPVFCid19 "VFC19";
CM_ SG_ 1350 VFCVectorZCUPVFCid2 "PostClimatisation";
CM_ SG_ 1350 VFCVectorZCUPVFCid20 "VFC20";
CM_ SG_ 1350 VFCVectorZCUPVFCid21 "PowerClosures";
CM_ SG_ 1350 VFCVectorZCUPVFCid22 "VehicleDriving";
CM_ SG_ 1350 VFCVectorZCUPVFCid23 "VFCid23";
CM_ SG_ 1350 VFCVectorZCUPVFCid24 "SettingsProfile";
CM_ SG_ 1350 VFCVectorZCUPVFCid25 "SeatComfortFunctions";
CM_ SG_ 1350 VFCVectorZCUPVFCid26 "Brake";
CM_ SG_ 1350 VFCVectorZCUPVFCid27 "InfotainmentPoll";
CM_ SG_ 1350 VFCVectorZCUPVFCid28 "HVEnergyStorage";
CM_ SG_ 1350 VFCVectorZCUPVFCid29 "VFC29";
CM_ SG_ 1350 VFCVectorZCUPVFCid3 "PowertrainParkingClimatization";
CM_ SG_ 1350 VFCVectorZCUPVFCid30 "TelematicsConnectivity";
CM_ SG_ 1350 VFCVectorZCUPVFCid31 "VFC31";
CM_ SG_ 1350 VFCVectorZCUPVFCid32 "VFC32";
CM_ SG_ 1350 VFCVectorZCUPVFCid33 "Diagnostics";
CM_ SG_ 1350 VFCVectorZCUPVFCid34 "VehicleModeManagement";
CM_ SG_ 1350 VFCVectorZCUPVFCid35 "TrailerCaravanFunctions";
CM_ SG_ 1350 VFCVectorZCUPVFCid36 "Immobilizer";
CM_ SG_ 1350 VFCVectorZCUPVFCid37 "Windows";
CM_ SG_ 1350 VFCVectorZCUPVFCid38 "Visibility";
CM_ SG_ 1350 VFCVectorZCUPVFCid39 "VFC39";
CM_ SG_ 1350 VFCVectorZCUPVFCid4 "VFC4";
CM_ SG_ 1350 VFCVectorZCUPVFCid40 "VFC40";
CM_ SG_ 1350 VFCVectorZCUPVFCid41 "InfotainmentPush";
CM_ SG_ 1350 VFCVectorZCUPVFCid42 "ChargingHV";
CM_ SG_ 1350 VFCVectorZCUPVFCid43 "BodyPreClimatisation";
CM_ SG_ 1350 VFCVectorZCUPVFCid44 "Crash";
CM_ SG_ 1350 VFCVectorZCUPVFCid45 "GlobalShortDuration";
CM_ SG_ 1350 VFCVectorZCUPVFCid46 "ExteriorLightsHazard";
CM_ SG_ 1350 VFCVectorZCUPVFCid47 "VFC47";
CM_ SG_ 1350 VFCVectorZCUPVFCid48 "DoorOpenWarning";
CM_ SG_ 1350 VFCVectorZCUPVFCid49 "ChargingLVInit";
CM_ SG_ 1350 VFCVectorZCUPVFCid5 "VFC5";
CM_ SG_ 1350 VFCVectorZCUPVFCid50 "VFC50";
CM_ SG_ 1350 VFCVectorZCUPVFCid51 "VFC51";
CM_ SG_ 1350 VFCVectorZCUPVFCid52 "HVBatteryThermalEventWarning";
CM_ SG_ 1350 VFCVectorZCUPVFCid53 "VisualAssist";
CM_ SG_ 1350 VFCVectorZCUPVFCid54 "PassiveSafety";
CM_ SG_ 1350 VFCVectorZCUPVFCid55 "LifeDetection";
CM_ SG_ 1350 VFCVectorZCUPVFCid56 "BackboneFlexray";
CM_ SG_ 1350 VFCVectorZCUPVFCid57 "Functionmarket";
CM_ SG_ 1350 VFCVectorZCUPVFCid58 "VFCid58";
CM_ SG_ 1350 VFCVectorZCUPVFCid59 "VFCid59";
CM_ SG_ 1350 VFCVectorZCUPVFCid6 "SettingsVehicle";
CM_ SG_ 1350 VFCVectorZCUPVFCid60 "VFCid60";
CM_ SG_ 1350 VFCVectorZCUPVFCid61 "VFCid61";
CM_ SG_ 1350 VFCVectorZCUPVFCid7 "VFCid7";
CM_ SG_ 1350 VFCVectorZCUPVFCid8 "VFCid8";
CM_ SG_ 1350 VFCVectorZCUPVFCid9 "IPWakeup";
CM_ SG_ 1286 WakeUpReasonsforZCUP "WakeUpReasons";
BA_DEF_ BO_ "CANFD_BRS" ENUM "0","1";
BA_DEF_ BO_ "GenMsgCycleTime" INT 0 65536;
BA_DEF_ BO_ "GenMsgDelayTime" INT 0 65536;
BA_DEF_ BO_ "GenMsgSendType" ENUM "cyclic", "spontaneous", "not-used", "not-used", "not-used", "cyclicAndSpontaneous", "not-used", "cyclicIfActive", "NoMsgSendType";
BA_DEF_ BO_ "GenMsgStartDelayTime" INT 0 65536;
BA_DEF_ BO_ "VFrameFormat" ENUM "StandardCAN","ExtendedCAN","reserved","J1939PG","reserved","reserved","reserved","reserved","reserved","reserved","reserved","reserved","reserved","reserved","StandardCAN_FD","ExtendedCAN_FD";
BA_DEF_ SG_ "GenSigSendType" ENUM "Cyclic","OnWrite","OnWriteWithRepetition","OnChange","OnChangeWithRepetition","IfActive","IfActiveWithRepetition","NoSigSendType";
BA_DEF_ SG_ "GenSigStartValue" HEX 0 80000000;
BA_DEF_ BO_ "GenMsgILSupport" ENUM "No","Yes";
BA_DEF_ BO_ "NmAsrMessage" ENUM "No","Yes";
BA_DEF_ SG_ "GenSigFuncType" ENUM "NoFunction","n/a","n/a","n/a","n/a","n/a","n/a","n/a","n/a","n/a","n/a","n/a","n/a","n/a","n/a","CHK","CNTR","n/a","n/a","n/a","CNTR_AR_01","CRC_AR_01_BOTH","CRC_AR_01_ALT","CRC_AR_01_LOW","CRC_AR_01_NIBBLE","CNTR_AR_04","CRC_AR_04A","CNTR_AR_05","CRC_AR_05";
BA_DEF_ SG_ "GenSigDataID" STRING;
BA_DEF_DEF_ "CANFD_BRS" "1";
BA_DEF_DEF_ "GenSigStartValue" 0;
BA_DEF_DEF_ "VFrameFormat" "J1939PG";
BA_DEF_DEF_ "GenSigSendType" "NoSigSendType";
BA_DEF_DEF_ "GenMsgCycleTime" 0;
BA_DEF_DEF_ "GenMsgDelayTime" 0;
BA_DEF_DEF_ "GenMsgStartDelayTime" 0;
BA_DEF_DEF_ "GenMsgSendType" "NoMsgSendType";
BA_DEF_DEF_ "GenMsgILSupport" "Yes";
BA_DEF_DEF_ "NmAsrMessage" "No";
BA_DEF_DEF_ "GenSigFuncType" "NoFunction";
BA_DEF_DEF_ "GenSigDataID" "";

BA_ "GenMsgCycleTime" BO_ 441 100.000;
BA_ "GenMsgSendType" BO_ 441 0;
BA_ "VFrameFormat" BO_ 441 14;

BA_ "GenMsgCycleTime" BO_ 801 450.000;
BA_ "GenMsgSendType" BO_ 801 0;
BA_ "VFrameFormat" BO_ 801 14;

BA_ "GenMsgCycleTime" BO_ 520 200.000;
BA_ "GenMsgSendType" BO_ 520 0;
BA_ "VFrameFormat" BO_ 520 14;

BA_ "GenMsgCycleTime" BO_ 58 10.000;
BA_ "GenMsgSendType" BO_ 58 0;
BA_ "VFrameFormat" BO_ 58 14;

BA_ "GenMsgCycleTime" BO_ 310 50.000;
BA_ "GenMsgSendType" BO_ 310 0;
BA_ "VFrameFormat" BO_ 310 14;

BA_ "GenMsgCycleTime" BO_ 1184 1000.000;
BA_ "GenMsgSendType" BO_ 1184 0;
BA_ "VFrameFormat" BO_ 1184 14;

BA_ "GenMsgCycleTime" BO_ 600 250.000;
BA_ "GenMsgSendType" BO_ 600 0;
BA_ "VFrameFormat" BO_ 600 14;

BA_ "GenMsgCycleTime" BO_ 803 500.000;
BA_ "GenMsgSendType" BO_ 803 0;
BA_ "VFrameFormat" BO_ 803 14;

BA_ "GenMsgCycleTime" BO_ 643 350.000;
BA_ "GenMsgSendType" BO_ 643 0;
BA_ "VFrameFormat" BO_ 643 14;

BA_ "GenMsgCycleTime" BO_ 882 700.000;
BA_ "GenMsgSendType" BO_ 882 0;
BA_ "VFrameFormat" BO_ 882 14;

BA_ "GenMsgCycleTime" BO_ 451 150.000;
BA_ "GenMsgSendType" BO_ 451 0;
BA_ "VFrameFormat" BO_ 451 14;

BA_ "GenMsgCycleTime" BO_ 258 20.000;
BA_ "GenMsgSendType" BO_ 258 0;
BA_ "VFrameFormat" BO_ 258 14;

BA_ "GenMsgDelayTime" BO_ 455 50.000;
BA_ "GenMsgSendType" BO_ 455 1;
BA_ "VFrameFormat" BO_ 455 14;

BA_ "GenMsgDelayTime" BO_ 51 10.000;
BA_ "GenMsgSendType" BO_ 51 1;
BA_ "VFrameFormat" BO_ 51 14;

BA_ "GenMsgCycleTime" BO_ 1350 1000.000;
BA_ "GenMsgSendType" BO_ 1350 0;
BA_ "VFrameFormat" BO_ 1350 0;

BA_ "GenMsgDelayTime" BO_ 1286 20.000;
BA_ "GenMsgSendType" BO_ 1286 1;
BA_ "VFrameFormat" BO_ 1286 0;
BA_ "GenMsgILSupport" BO_ 1286 0;
BA_ "NmAsrMessage" BO_ 1286 1;
BA_ "GenSigSendType" SG_ 441 AjarChrgLidRearSwitch 0;
BA_ "GenSigSendType" SG_ 441 AjarFuelFlapSwitch 0;
BA_ "GenSigSendType" SG_ 801 AmbTEstimdAmbTEstimd 0;
BA_ "GenSigStartValue" SG_ 801 AmbTEstimdAmbTEstimd 700;
BA_ "GenSigSendType" SG_ 801 AmbTEstimdQf 0;
BA_ "GenSigSendType" SG_ 520 AmbTRawAtPassSideAmbTVal 0;
BA_ "GenSigStartValue" SG_ 520 AmbTRawAtPassSideAmbTVal 700;
BA_ "GenSigSendType" SG_ 520 AmbTRawAtPassSideQly 0;
BA_ "GenSigSendType" SG_ 520 AmbTURawAtPassSide 0;
BA_ "GenSigStartValue" SG_ 520 AmbTURawAtPassSide 700;
BA_ "GenSigSendType" SG_ 310 AutDemstOperSts 0;
BA_ "GenSigSendType" SG_ 451 BkpOfDstTrvldFromVehCom 0;
BA_ "GenSigSendType" SG_ 51 BodyDataTraceZCUP1Functiondevpsignalgroup1 1;
BA_ "GenSigSendType" SG_ 51 BodyDataTraceZCUP1Functiondevpsignalgroup2 1;
BA_ "GenSigSendType" SG_ 51 BodyDataTraceZCUP1Functiondevpsignalgroup3 1;
BA_ "GenSigSendType" SG_ 51 BodyDataTraceZCUP1Functiondevpsignalgroup4 1;
BA_ "GenSigSendType" SG_ 51 BodyDataTraceZCUP1Functiondevpsignalgroup5 1;
BA_ "GenSigSendType" SG_ 51 BodyDataTraceZCUP1Functiondevpsignalgroup6 1;
BA_ "GenSigSendType" SG_ 51 BodyDataTraceZCUP1Functiondevpsignalgroup7 1;
BA_ "GenSigSendType" SG_ 51 BodyDataTraceZCUP1Functiondevpsignalgroup8 1;
BA_ "GenSigSendType" SG_ 51 BodyDataTraceZCUP2Functiondevpsignalgroup1 1;
BA_ "GenSigSendType" SG_ 51 BodyDataTraceZCUP2Functiondevpsignalgroup2 1;
BA_ "GenSigSendType" SG_ 51 BodyDataTraceZCUP2Functiondevpsignalgroup3 1;
BA_ "GenSigSendType" SG_ 51 BodyDataTraceZCUP2Functiondevpsignalgroup4 1;
BA_ "GenSigSendType" SG_ 51 BodyDataTraceZCUP2Functiondevpsignalgroup5 1;
BA_ "GenSigSendType" SG_ 51 BodyDataTraceZCUP2Functiondevpsignalgroup6 1;
BA_ "GenSigSendType" SG_ 51 BodyDataTraceZCUP2Functiondevpsignalgroup7 1;
BA_ "GenSigSendType" SG_ 51 BodyDataTraceZCUP2Functiondevpsignalgroup8 1;
BA_ "GenSigSendType" SG_ 51 BodyDataTraceZCUP3Functiondevpsignalgroup1 1;
BA_ "GenSigSendType" SG_ 51 BodyDataTraceZCUP3Functiondevpsignalgroup2 1;
BA_ "GenSigSendType" SG_ 51 BodyDataTraceZCUP3Functiondevpsignalgroup3 1;
BA_ "GenSigSendType" SG_ 51 BodyDataTraceZCUP3Functiondevpsignalgroup4 1;
BA_ "GenSigSendType" SG_ 51 BodyDataTraceZCUP3Functiondevpsignalgroup5 1;
BA_ "GenSigSendType" SG_ 51 BodyDataTraceZCUP3Functiondevpsignalgroup6 1;
BA_ "GenSigSendType" SG_ 51 BodyDataTraceZCUP3Functiondevpsignalgroup7 1;
BA_ "GenSigSendType" SG_ 51 BodyDataTraceZCUP3Functiondevpsignalgroup8 1;
BA_ "GenSigSendType" SG_ 51 BodyDataTraceZCUP4Functiondevpsignalgroup1 1;
BA_ "GenSigSendType" SG_ 51 BodyDataTraceZCUP4Functiondevpsignalgroup2 1;
BA_ "GenSigSendType" SG_ 51 BodyDataTraceZCUP4Functiondevpsignalgroup3 1;
BA_ "GenSigSendType" SG_ 51 BodyDataTraceZCUP4Functiondevpsignalgroup4 1;
BA_ "GenSigSendType" SG_ 51 BodyDataTraceZCUP4Functiondevpsignalgroup5 1;
BA_ "GenSigSendType" SG_ 51 BodyDataTraceZCUP4Functiondevpsignalgroup6 1;
BA_ "GenSigSendType" SG_ 51 BodyDataTraceZCUP4Functiondevpsignalgroup7 1;
BA_ "GenSigSendType" SG_ 51 BodyDataTraceZCUP4Functiondevpsignalgroup8 1;
BA_ "GenSigSendType" SG_ 51 BodyDataTraceZCUP5Functiondevpsignalgroup1 1;
BA_ "GenSigSendType" SG_ 51 BodyDataTraceZCUP5Functiondevpsignalgroup2 1;
BA_ "GenSigSendType" SG_ 51 BodyDataTraceZCUP5Functiondevpsignalgroup3 1;
BA_ "GenSigSendType" SG_ 51 BodyDataTraceZCUP5Functiondevpsignalgroup4 1;
BA_ "GenSigSendType" SG_ 51 BodyDataTraceZCUP5Functiondevpsignalgroup5 1;
BA_ "GenSigSendType" SG_ 51 BodyDataTraceZCUP5Functiondevpsignalgroup6 1;
BA_ "GenSigSendType" SG_ 51 BodyDataTraceZCUP5Functiondevpsignalgroup7 1;
BA_ "GenSigSendType" SG_ 51 BodyDataTraceZCUP5Functiondevpsignalgroup8 1;
BA_ "GenSigSendType" SG_ 51 BodyDataTraceZCUP6Functiondevpsignalgroup1 1;
BA_ "GenSigSendType" SG_ 51 BodyDataTraceZCUP6Functiondevpsignalgroup2 1;
BA_ "GenSigSendType" SG_ 51 BodyDataTraceZCUP6Functiondevpsignalgroup3 1;
BA_ "GenSigSendType" SG_ 51 BodyDataTraceZCUP6Functiondevpsignalgroup4 1;
BA_ "GenSigSendType" SG_ 51 BodyDataTraceZCUP6Functiondevpsignalgroup5 1;
BA_ "GenSigSendType" SG_ 51 BodyDataTraceZCUP6Functiondevpsignalgroup6 1;
BA_ "GenSigSendType" SG_ 51 BodyDataTraceZCUP6Functiondevpsignalgroup7 1;
BA_ "GenSigSendType" SG_ 51 BodyDataTraceZCUP6Functiondevpsignalgroup8 1;
BA_ "GenSigSendType" SG_ 51 BodyDataTraceZCUP7Functiondevpsignalgroup1 1;
BA_ "GenSigSendType" SG_ 51 BodyDataTraceZCUP7Functiondevpsignalgroup2 1;
BA_ "GenSigSendType" SG_ 51 BodyDataTraceZCUP7Functiondevpsignalgroup3 1;
BA_ "GenSigSendType" SG_ 51 BodyDataTraceZCUP7Functiondevpsignalgroup4 1;
BA_ "GenSigSendType" SG_ 51 BodyDataTraceZCUP7Functiondevpsignalgroup5 1;
BA_ "GenSigSendType" SG_ 51 BodyDataTraceZCUP7Functiondevpsignalgroup6 1;
BA_ "GenSigSendType" SG_ 51 BodyDataTraceZCUP7Functiondevpsignalgroup7 1;
BA_ "GenSigSendType" SG_ 51 BodyDataTraceZCUP7Functiondevpsignalgroup8 1;
BA_ "GenSigSendType" SG_ 451 CCMFragraCh1AvlTiPrec 0;
BA_ "GenSigSendType" SG_ 451 CCMFragraCh2AvlTiPrec 0;
BA_ "GenSigSendType" SG_ 451 CCMFragraCh3AvlTiPrec 0;
BA_ "GenSigSendType" SG_ 451 CCMFragraCh4AvlTiPrec 0;
BA_ "GenSigSendType" SG_ 451 CCMFragraCh5AvlTiPrec 0;
BA_ "GenSigSendType" SG_ 451 CCMHvahFltIndcn 0;
BA_ "GenSigSendType" SG_ 441 CarTiIntForClima 0;
BA_ "GenSigSendType" SG_ 600 CcmElecAirDirCrtlReqDrvrLePosX 0;
BA_ "GenSigSendType" SG_ 600 CcmElecAirDirCrtlReqDrvrLePosY 0;
BA_ "GenSigSendType" SG_ 600 CcmElecAirDirCrtlReqDrvrRiPosX 0;
BA_ "GenSigSendType" SG_ 600 CcmElecAirDirCrtlReqDrvrRiPosY 0;
BA_ "GenSigSendType" SG_ 600 CcmElecAirDirCrtlReqPassLePosX 0;
BA_ "GenSigSendType" SG_ 600 CcmElecAirDirCrtlReqPassLePosY 0;
BA_ "GenSigSendType" SG_ 600 CcmElecAirDirCrtlReqPassRiPosX 0;
BA_ "GenSigSendType" SG_ 600 CcmElecAirDirCrtlReqPassRiPosY 0;
BA_ "GenSigSendType" SG_ 803 CcmRollgCntrSts 0;
BA_ "GenSigSendType" SG_ 643 CdsParkgClimaActv 0;
BA_ "GenSigSendType" SG_ 310 ChdLockPassReSts 0;
BA_ "GenSigSendType" SG_ 310 ChdLockRightSts 0;
BA_ "GenSigSendType" SG_ 310 ChrgLidDCorAcDctSwtReq 0;
BA_ "GenSigSendType" SG_ 310 CinhPassReSts 0;
BA_ "GenSigSendType" SG_ 310 CinhPassReSwt 0;
BA_ "GenSigSendType" SG_ 310 CinhPassSts 0;
BA_ "GenSigSendType" SG_ 310 CinhPassSwt 0;
BA_ "GenSigSendType" SG_ 600 ClimaActv 0;
BA_ "GenSigSendType" SG_ 882 ClimaActvAlrmSts 0;
BA_ "GenSigSendType" SG_ 441 ClimaCmptSts 0;
BA_ "GenSigSendType" SG_ 803 ClimaCoolgReqLvl 0;
BA_ "GenSigSendType" SG_ 441 ClimaCtrlActv 0;
BA_ "GenSigSendType" SG_ 441 ClimaDefrstSts 0;
BA_ "GenSigSendType" SG_ 441 ClimaEstimdTForHeat 0;
BA_ "GenSigSendType" SG_ 441 ClimaEstimdTForReHeat 0;
BA_ "GenSigSendType" SG_ 803 ClimaHeatgReqLvl 0;
BA_ "GenSigSendType" SG_ 455 ClimaOffReq 1;
BA_ "GenSigSendType" SG_ 643 ClimaOvrHeatProActv 0;
BA_ "GenSigSendType" SG_ 451 ClimaOvrHeatProActvSts 0;
BA_ "GenSigSendType" SG_ 455 ClimaOvrHeatProRspn 1;
BA_ "GenSigSendType" SG_ 455 ClimaOvrHeatProWarn 1;
BA_ "GenSigSendType" SG_ 801 ClimaOvrHeatPrtSts 0;
BA_ "GenSigSendType" SG_ 451 ClimaPwrCns 0;
BA_ "GenSigSendType" SG_ 451 ClimaPwrCritDes 0;
BA_ "GenSigSendType" SG_ 451 ClimaPwrNormDes 0;
BA_ "GenSigSendType" SG_ 258 ClimaSts 0;
BA_ "GenSigStartValue" SG_ 258 ClimaSts 1;
BA_ "GenSigSendType" SG_ 310 ClimaTiOfEnd 0;
BA_ "GenSigSendType" SG_ 803 CmptModForHp 0;
BA_ "GenSigStartValue" SG_ 803 CmptModForHp 5;
BA_ "GenSigSendType" SG_ 643 CmptmtAirDistbnRspAirDistbnDrvr 0;
BA_ "GenSigSendType" SG_ 643 CmptmtAirDistbnRspAirDistbnPass 0;
BA_ "GenSigSendType" SG_ 643 CmptmtAirDistbnRspAirDistbnSecLe 0;
BA_ "GenSigSendType" SG_ 643 CmptmtAirDistbnRspAirDistbnSecRi 0;
BA_ "GenSigSendType" SG_ 643 CmptmtAirDistbnRspAirDistbnThrd 0;
BA_ "GenSigSendType" SG_ 441 CmptmtAirTEstimdAtRowFirstLoResl 0;
BA_ "GenSigStartValue" SG_ 441 CmptmtAirTEstimdAtRowFirstLoResl 600;
BA_ "GenSigSendType" SG_ 801 CmptmtAirTEstimdExtdComptmtT 0;
BA_ "GenSigStartValue" SG_ 801 CmptmtAirTEstimdExtdComptmtT 600;
BA_ "GenSigSendType" SG_ 801 CmptmtAirTEstimdExtdQlyFlg 0;
BA_ "GenSigSendType" SG_ 1184 CmptmtIntrMtrlTEstimdMtrlSnsrT 0;
BA_ "GenSigSendType" SG_ 1184 CmptmtIntrMtrlTEstimdMtrlSnsrTQly2 0;
BA_ "GenSigStartValue" SG_ 1184 CmptmtIntrMtrlTEstimdMtrlSnsrTQly2 1;
BA_ "GenSigSendType" SG_ 310 CmptmtTFrntCmptmtTFrnt 0;
BA_ "GenSigStartValue" SG_ 310 CmptmtTFrntCmptmtTFrnt 600;
BA_ "GenSigSendType" SG_ 310 CmptmtTFrntFanForCmptmtTRunng 0;
BA_ "GenSigSendType" SG_ 310 CmptmtTFrntQf 0;
BA_ "GenSigStartValue" SG_ 310 CmptmtTFrntQf 1;
BA_ "GenSigSendType" SG_ 803 CmptmtTReCmptmtTFrnt 0;
BA_ "GenSigStartValue" SG_ 803 CmptmtTReCmptmtTFrnt 600;
BA_ "GenSigSendType" SG_ 803 CmptmtTReCmptmtTFrntQf 0;
BA_ "GenSigStartValue" SG_ 803 CmptmtTReCmptmtTFrntQf 1;
BA_ "GenSigSendType" SG_ 803 CmptmtTReFanForCmptmtTRunng 0;
BA_ "GenSigSendType" SG_ 441 CoupldCtrlErrAtRowFirstLe 0;
BA_ "GenSigSendType" SG_ 441 CoupldCtrlErrAtRowFirstRi 0;
BA_ "GenSigSendType" SG_ 441 CoupldCtrlErrAtRowSecLe 0;
BA_ "GenSigSendType" SG_ 441 CoupldCtrlErrAtRowSecRi 0;
BA_ "GenSigSendType" SG_ 455 DiDblLock 1;
BA_ "GenSigSendType" SG_ 441 DoorPass2Swt1DplyHndl 0;
BA_ "GenSigStartValue" SG_ 441 DoorPass2Swt1DplyHndl 1;
BA_ "GenSigSendType" SG_ 441 DoorPass2Swt2DplyHndl 0;
BA_ "GenSigSendType" SG_ 643 DoorPassCinhIntFailInfCinchFlt1 0;
BA_ "GenSigSendType" SG_ 643 DoorPassCinhIntFailInfCinchRestFlt 0;
BA_ "GenSigSendType" SG_ 258 DoorPassHndlSts 0;
BA_ "GenSigSendType" SG_ 441 DoorPassLatPosn 0;
BA_ "GenSigSendType" SG_ 58 DoorPassOpenLowReqOutdSwt1 0;
BA_ "GenSigStartValue" SG_ 58 DoorPassOpenLowReqOutdSwt1 2;
BA_ "GenSigSendType" SG_ 58 DoorPassOpenReqInsdSwt1 0;
BA_ "GenSigStartValue" SG_ 58 DoorPassOpenReqInsdSwt1 2;
BA_ "GenSigSendType" SG_ 441 DoorPassRe2Sw1DplyHndl 0;
BA_ "GenSigStartValue" SG_ 441 DoorPassRe2Sw1DplyHndl 1;
BA_ "GenSigSendType" SG_ 441 DoorPassRe2Sw2DplyHndl 0;
BA_ "GenSigSendType" SG_ 58 DoorPassReCinhIntFailInfCinchFlt1 0;
BA_ "GenSigSendType" SG_ 58 DoorPassReCinhIntFailInfCinchRestFlt 0;
BA_ "GenSigSendType" SG_ 310 DoorPassReHndlSts 0;
BA_ "GenSigSendType" SG_ 58 DoorPassReLatPosn 0;
BA_ "GenSigSendType" SG_ 258 DoorPassReLockSts 0;
BA_ "GenSigSendType" SG_ 58 DoorPassReOpenLowReqOutdSwt1 0;
BA_ "GenSigStartValue" SG_ 58 DoorPassReOpenLowReqOutdSwt1 2;
BA_ "GenSigSendType" SG_ 58 DoorPassReOpenReqInsdSwt1 0;
BA_ "GenSigStartValue" SG_ 58 DoorPassReOpenReqInsdSwt1 2;
BA_ "GenSigSendType" SG_ 58 DoorPassReRelsFailCinchOverTimed 0;
BA_ "GenSigSendType" SG_ 58 DoorPassReRelsFailFailure1 0;
BA_ "GenSigSendType" SG_ 58 DoorPassReRelsFailMechRels 0;
BA_ "GenSigSendType" SG_ 643 DoorPassRelsFailCinchOverTimed 0;
BA_ "GenSigSendType" SG_ 643 DoorPassRelsFailFailure1 0;
BA_ "GenSigSendType" SG_ 643 DoorPassRelsFailMechRels 0;
BA_ "GenSigSendType" SG_ 643 DoorRiReCinhIntFailInfCinchFlt1 0;
BA_ "GenSigSendType" SG_ 643 DoorRiReCinhIntFailInfCinchRestFlt 0;
BA_ "GenSigSendType" SG_ 258 DoorRiReHndlSts 0;
BA_ "GenSigSendType" SG_ 58 DoorRiReLatPosn 0;
BA_ "GenSigSendType" SG_ 58 DoorRiReOpenLowReqOutdSwt1 0;
BA_ "GenSigStartValue" SG_ 58 DoorRiReOpenLowReqOutdSwt1 2;
BA_ "GenSigSendType" SG_ 58 DoorRiReOpenReqInsdSwt1 0;
BA_ "GenSigStartValue" SG_ 58 DoorRiReOpenReqInsdSwt1 2;
BA_ "GenSigSendType" SG_ 643 DoorRiReRelsFailCinchOverTimed 0;
BA_ "GenSigSendType" SG_ 643 DoorRiReRelsFailFailure1 0;
BA_ "GenSigSendType" SG_ 643 DoorRiReRelsFailMechRels 0;
BA_ "GenSigSendType" SG_ 441 DrvrSeatHeatgPwrAllwd 0;
BA_ "GenSigSendType" SG_ 441 DrvrSeatVentnPwrAllwd 0;
BA_ "GenSigSendType" SG_ 451 DstTrvldVldFromVehCom 0;
BA_ "GenSigSendType" SG_ 803 DvlpFrameForCCMByte0 0;
BA_ "GenSigSendType" SG_ 803 DvlpFrameForCCMByte1 0;
BA_ "GenSigSendType" SG_ 803 DvlpFrameForCCMByte2 0;
BA_ "GenSigSendType" SG_ 803 DvlpFrameForCCMByte3 0;
BA_ "GenSigSendType" SG_ 803 DvlpFrameForCCMByte4 0;
BA_ "GenSigSendType" SG_ 803 DvlpFrameForCCMByte5 0;
BA_ "GenSigSendType" SG_ 803 DvlpFrameForCCMByte6 0;
BA_ "GenSigSendType" SG_ 803 DvlpFrameForCCMByte7 0;
BA_ "GenSigSendType" SG_ 451 EcoClimaSts 0;
BA_ "GenSigSendType" SG_ 1184 EgyDesForClima 0;
BA_ "GenSigSendType" SG_ 600 ElecAirVentnAvlSts 0;
BA_ "GenSigSendType" SG_ 600 ElecDefrstReqMirrDefrstReq 0;
BA_ "GenSigSendType" SG_ 600 ElecDefrstReqWinDefrstFrntReq 0;
BA_ "GenSigSendType" SG_ 600 ElecDefrstReqWinDefrstReReq 0;
BA_ "GenSigSendType" SG_ 1184 ElecVentnMotPwrCnsAct 0;
BA_ "GenSigSendType" SG_ 1184 ElecVentnMotPwrCnsDes 0;
BA_ "GenSigSendType" SG_ 258 EngRunngReqByClima 0;
BA_ "GenSigSendType" SG_ 441 EngSpdIncIdleForClima 0;
BA_ "GenSigSendType" SG_ 310 EvaprTFrntEvaprTFrnt 0;
BA_ "GenSigSendType" SG_ 310 EvaprTFrntEvaprTQf 0;
BA_ "GenSigStartValue" SG_ 310 EvaprTFrntEvaprTQf 1;
BA_ "GenSigSendType" SG_ 600 EvaprTReEvaprTFrnt 0;
BA_ "GenSigSendType" SG_ 600 EvaprTReEvaprTQf 0;
BA_ "GenSigStartValue" SG_ 600 EvaprTReEvaprTQf 1;
BA_ "GenSigSendType" SG_ 310 FltOfBeamHiPass 0;
BA_ "GenSigSendType" SG_ 310 FltOfBeamLoPass 0;
BA_ "GenSigSendType" SG_ 310 FltOfDaytiRunngLampPass 0;
BA_ "GenSigSendType" SG_ 310 FltOfFrntFogLampPass 0;
BA_ "GenSigSendType" SG_ 310 FltOfFrntPosnLampPass 0;
BA_ "GenSigSendType" SG_ 451 FltOfFrntTurnIndcrLe 0;
BA_ "GenSigSendType" SG_ 451 FltOfFrntTurnIndcrRi 0;
BA_ "GenSigSendType" SG_ 310 FltOfReFogLampDrv 0;
BA_ "GenSigSendType" SG_ 310 FltOfRePosnLampPass 0;
BA_ "GenSigSendType" SG_ 441 FltOfReRegPlateLamp 0;
BA_ "GenSigSendType" SG_ 451 FltOfReTurnIndcrLe 0;
BA_ "GenSigSendType" SG_ 451 FltOfReTurnIndcrRi 0;
BA_ "GenSigSendType" SG_ 310 FltOfRvsgLampPass 0;
BA_ "GenSigSendType" SG_ 441 FragCh1Id 0;
BA_ "GenSigSendType" SG_ 600 FragCh1UseUpWrn 0;
BA_ "GenSigSendType" SG_ 441 FragCh2Id 0;
BA_ "GenSigSendType" SG_ 600 FragCh2UseUpWrn 0;
BA_ "GenSigSendType" SG_ 441 FragCh3Id 0;
BA_ "GenSigSendType" SG_ 600 FragCh3UseUpWrn 0;
BA_ "GenSigSendType" SG_ 441 FragCh4Id 0;
BA_ "GenSigSendType" SG_ 600 FragCh4UseUpWrn 0;
BA_ "GenSigSendType" SG_ 441 FragCh5Id 0;
BA_ "GenSigSendType" SG_ 600 FragCh5UseUpWrn 0;
BA_ "GenSigSendType" SG_ 600 FragLvlFrmClima 0;
BA_ "GenSigSendType" SG_ 600 FragStsFrmClima 0;
BA_ "GenSigStartValue" SG_ 600 FragStsFrmClima 1;
BA_ "GenSigSendType" SG_ 803 FrntHvacBlowerSts 0;
BA_ "GenSigSendType" SG_ 451 FuSnsrActvSideFuLvlSnsrRawVal 0;
BA_ "GenSigSendType" SG_ 451 FuSnsrActvSideGenQF 0;
BA_ "GenSigSendType" SG_ 451 FuSnsrPasSideFuLvlSnsrRawVal 0;
BA_ "GenSigSendType" SG_ 451 FuSnsrPasSideGenQF 0;
BA_ "GenSigSendType" SG_ 803 HeatrAirTReq 0;
BA_ "GenSigStartValue" SG_ 803 HeatrAirTReq 120;
BA_ "GenSigSendType" SG_ 803 HpReqCritSts 0;
BA_ "GenSigSendType" SG_ 441 HvEgyDesForClima 0;
BA_ "GenSigSendType" SG_ 803 HvacAirMFlowEstimd 0;
BA_ "GenSigSendType" SG_ 803 HvacAirMFlowReEstimd 0;
BA_ "GenSigSendType" SG_ 643 HvacAirTForMaxTZoneEvaprTFrnt 0;
BA_ "GenSigSendType" SG_ 643 HvacAirTForMaxTZoneEvaprTQf 0;
BA_ "GenSigStartValue" SG_ 643 HvacAirTForMaxTZoneEvaprTQf 1;
BA_ "GenSigSendType" SG_ 803 HvacAirTForRowFirstAtFlrLeEvaprTFrnt 0;
BA_ "GenSigSendType" SG_ 803 HvacAirTForRowFirstAtFlrLeEvaprTQf 0;
BA_ "GenSigStartValue" SG_ 803 HvacAirTForRowFirstAtFlrLeEvaprTQf 1;
BA_ "GenSigSendType" SG_ 803 HvacAirTForRowFirstAtFlrRiEvaprTFrnt 0;
BA_ "GenSigSendType" SG_ 803 HvacAirTForRowFirstAtFlrRiEvaprTQf 0;
BA_ "GenSigStartValue" SG_ 803 HvacAirTForRowFirstAtFlrRiEvaprTQf 1;
BA_ "GenSigSendType" SG_ 803 HvacAirTForRowFirstAtVentLeEvaprTFrnt 0;
BA_ "GenSigSendType" SG_ 803 HvacAirTForRowFirstAtVentLeEvaprTQf 0;
BA_ "GenSigStartValue" SG_ 803 HvacAirTForRowFirstAtVentLeEvaprTQf 1;
BA_ "GenSigSendType" SG_ 803 HvacAirTForRowFirstAtVentRiEvaprTFrnt 0;
BA_ "GenSigSendType" SG_ 803 HvacAirTForRowFirstAtVentRiEvaprTQf 0;
BA_ "GenSigStartValue" SG_ 803 HvacAirTForRowFirstAtVentRiEvaprTQf 1;
BA_ "GenSigSendType" SG_ 803 HvacAirTForRowSecAtFlrLeEvaprTFrnt 0;
BA_ "GenSigSendType" SG_ 803 HvacAirTForRowSecAtFlrLeEvaprTQf 0;
BA_ "GenSigStartValue" SG_ 803 HvacAirTForRowSecAtFlrLeEvaprTQf 1;
BA_ "GenSigSendType" SG_ 803 HvacAirTForRowSecAtFlrRiEvaprTFrnt 0;
BA_ "GenSigSendType" SG_ 803 HvacAirTForRowSecAtFlrRiEvaprTQf 0;
BA_ "GenSigStartValue" SG_ 803 HvacAirTForRowSecAtFlrRiEvaprTQf 1;
BA_ "GenSigSendType" SG_ 803 HvacAirTForRowSecAtVentLeEvaprTFrnt 0;
BA_ "GenSigSendType" SG_ 803 HvacAirTForRowSecAtVentLeEvaprTQf 0;
BA_ "GenSigStartValue" SG_ 803 HvacAirTForRowSecAtVentLeEvaprTQf 1;
BA_ "GenSigSendType" SG_ 803 HvacAirTForRowSecAtVentRiEvaprTFrnt 0;
BA_ "GenSigSendType" SG_ 803 HvacAirTForRowSecAtVentRiEvaprTQf 0;
BA_ "GenSigStartValue" SG_ 803 HvacAirTForRowSecAtVentRiEvaprTQf 1;
BA_ "GenSigSendType" SG_ 803 HvacAirTForRowThrdAtFlrRiEvaprTFrnt 0;
BA_ "GenSigSendType" SG_ 803 HvacAirTForRowThrdAtFlrRiEvaprTQf 0;
BA_ "GenSigStartValue" SG_ 803 HvacAirTForRowThrdAtFlrRiEvaprTQf 1;
BA_ "GenSigSendType" SG_ 803 HvacAirTForRowThrdAtVentRiEvaprTFrnt 0;
BA_ "GenSigSendType" SG_ 803 HvacAirTForRowThrdAtVentRiEvaprTQf 0;
BA_ "GenSigStartValue" SG_ 803 HvacAirTForRowThrdAtVentRiEvaprTQf 1;
BA_ "GenSigSendType" SG_ 803 HvacCondsorTEvaprTFrnt 0;
BA_ "GenSigSendType" SG_ 803 HvacCondsorTEvaprTQf 0;
BA_ "GenSigStartValue" SG_ 803 HvacCondsorTEvaprTQf 1;
BA_ "GenSigSendType" SG_ 803 HvacCondsorTspEvaprTFrnt 0;
BA_ "GenSigSendType" SG_ 803 HvacCondsorTspEvaprTQf 0;
BA_ "GenSigStartValue" SG_ 803 HvacCondsorTspEvaprTQf 1;
BA_ "GenSigSendType" SG_ 258 HvacCoolgEnaFrnt 0;
BA_ "GenSigSendType" SG_ 310 HvacCoolgEnaRe 0;
BA_ "GenSigSendType" SG_ 1184 HvacDefrstFlapActlPosn 0;
BA_ "GenSigSendType" SG_ 520 HvacEvaprTSpFrnt 0;
BA_ "GenSigStartValue" SG_ 520 HvacEvaprTSpFrnt 50;
BA_ "GenSigSendType" SG_ 600 HvacEvaprTSpRe 0;
BA_ "GenSigStartValue" SG_ 600 HvacEvaprTSpRe 50;
BA_ "GenSigSendType" SG_ 451 HvacFanLvlFbFrnt 0;
BA_ "GenSigSendType" SG_ 451 HvacFanLvlFbRe 0;
BA_ "GenSigSendType" SG_ 1184 HvacFanSet2HvacFanSpd2 0;
BA_ "GenSigSendType" SG_ 1184 HvacHeatElmAirMFlowEstimd 0;
BA_ "GenSigSendType" SG_ 643 HvacHeatgReq 0;
BA_ "GenSigSendType" SG_ 803 HvacHeatrInletTempReqEvaprTFrnt 0;
BA_ "GenSigSendType" SG_ 803 HvacHeatrInletTempReqEvaprTQf 0;
BA_ "GenSigSendType" SG_ 882 HvacHexAirTHvacAirTForHeatrFrnt 0;
BA_ "GenSigSendType" SG_ 882 HvacHexAirTHvacAirTForHeatrFrntQf 0;
BA_ "GenSigStartValue" SG_ 882 HvacHexAirTHvacAirTForHeatrFrntQf 1;
BA_ "GenSigSendType" SG_ 1184 HvacModFlapActlPosnFrstRowLe 0;
BA_ "GenSigSendType" SG_ 1184 HvacModFlapActlPosnFrstRowRi 0;
BA_ "GenSigSendType" SG_ 1184 HvacModFlapActlPosnSecRowLe 0;
BA_ "GenSigSendType" SG_ 1184 HvacModFlapActlPosnSecRowRi 0;
BA_ "GenSigSendType" SG_ 803 HvacOsaAndRecActrQfForHp 0;
BA_ "GenSigSendType" SG_ 1184 HvacOsaFlapActlPosn 0;
BA_ "GenSigSendType" SG_ 1184 HvacRecFlapActlPosn 0;
BA_ "GenSigSendType" SG_ 451 HvacRecircAct 0;
BA_ "GenSigSendType" SG_ 803 HvacTempFlapActlPosnFrstRowLe 0;
BA_ "GenSigSendType" SG_ 803 HvacTempFlapActlPosnFrstRowRi 0;
BA_ "GenSigSendType" SG_ 803 HvacTempFlapActlPosnSecRowLe 0;
BA_ "GenSigSendType" SG_ 803 HvacTempFlapActlPosnSecRowRi 0;
BA_ "GenSigSendType" SG_ 310 HvahAirTEstmdEvaprTFrnt 0;
BA_ "GenSigSendType" SG_ 310 HvahAirTEstmdEvaprTQf 0;
BA_ "GenSigStartValue" SG_ 310 HvahAirTEstmdEvaprTQf 1;
BA_ "GenSigSendType" SG_ 643 HvahAirTsp 0;
BA_ "GenSigStartValue" SG_ 643 HvahAirTsp 600;
BA_ "GenSigSendType" SG_ 803 HvahHeatgReq 0;
BA_ "GenSigSendType" SG_ 803 HvahPwrReq 0;
BA_ "GenSigSendType" SG_ 882 HwRowFrstPassFrntExtMotCtrl 0;
BA_ "GenSigSendType" SG_ 882 HwRowFrstPassFrntHeiMotCtrl 0;
BA_ "GenSigSendType" SG_ 882 HwRowFrstPassHeiMotCtrl 0;
BA_ "GenSigSendType" SG_ 882 HwRowFrstPassInclMotCtrl 0;
BA_ "GenSigSendType" SG_ 882 HwRowFrstPassSldMotCtrl 0;
BA_ "GenSigSendType" SG_ 441 IceBreakDoorPassActv 0;
BA_ "GenSigSendType" SG_ 58 IceBreakDoorPassReActv 0;
BA_ "GenSigSendType" SG_ 310 IceBreakDoorRiReActv 0;
BA_ "GenSigSendType" SG_ 451 IntLightPasSideDoorSupply 0;
BA_ "GenSigSendType" SG_ 451 IntLightPasSideSupply 0;
BA_ "GenSigSendType" SG_ 451 IntLightRePasDoorSupply 0;
BA_ "GenSigSendType" SG_ 451 IntLightRePasSideSupply 0;
BA_ "GenSigSendType" SG_ 600 IntPm25HiPopUp 0;
BA_ "GenSigSendType" SG_ 643 IntPm25LvlFrmClima 0;
BA_ "GenSigSendType" SG_ 310 IntPm25StsFrmClima 0;
BA_ "GenSigSendType" SG_ 643 IntPm25VluFrmClima 0;
BA_ "GenSigSendType" SG_ 882 IntrLiAmb1BnIngrd 0;
BA_ "GenSigSendType" SG_ 882 IntrLiAmb1GrnIngrd 0;
BA_ "GenSigSendType" SG_ 882 IntrLiAmb1Intensty 0;
BA_ "GenSigSendType" SG_ 882 IntrLiAmb1RedIngrd 0;
BA_ "GenSigSendType" SG_ 882 IntrLiAmb1SelCmd1 0;
BA_ "GenSigSendType" SG_ 882 IntrLiAmb1SelCmd2 0;
BA_ "GenSigSendType" SG_ 882 IntrLiAmb1SynchDelay 0;
BA_ "GenSigSendType" SG_ 882 IntrLiAmb1TargetTransitionTime 0;
BA_ "GenSigSendType" SG_ 882 IntrLiAmb1Trigger 0;
BA_ "GenSigSendType" SG_ 882 IntrLiAmb1Update 0;
BA_ "GenSigSendType" SG_ 882 IntrLiAmb2BnIngrd 0;
BA_ "GenSigSendType" SG_ 882 IntrLiAmb2GrnIngrd 0;
BA_ "GenSigSendType" SG_ 882 IntrLiAmb2Intensty 0;
BA_ "GenSigSendType" SG_ 882 IntrLiAmb2RedIngrd 0;
BA_ "GenSigSendType" SG_ 882 IntrLiAmb2SelCmd1 0;
BA_ "GenSigSendType" SG_ 882 IntrLiAmb2SelCmd2 0;
BA_ "GenSigSendType" SG_ 882 IntrLiAmb2SynchDelay 0;
BA_ "GenSigSendType" SG_ 882 IntrLiAmb2TargetTransitionTime 0;
BA_ "GenSigSendType" SG_ 882 IntrLiAmb2Trigger 0;
BA_ "GenSigSendType" SG_ 882 IntrLiAmb2Update 0;
BA_ "GenSigSendType" SG_ 441 MirrAtPassInMovmt 0;
BA_ "GenSigSendType" SG_ 803 MirrDefrstAtPassSts 0;
BA_ "GenSigSendType" SG_ 310 MirrDwnStsAtPass 0;
BA_ "GenSigSendType" SG_ 310 MirrPosnToSetTarPosnAtPassMirrPosnAdjCldLeRi 0;
BA_ "GenSigSendType" SG_ 310 MirrPosnToSetTarPosnAtPassMirrPosnAdjCldUpDwn 0;
BA_ "GenSigSendType" SG_ 310 OpenPassReSwt 0;
BA_ "GenSigSendType" SG_ 310 OpenPassSwt 0;
BA_ "GenSigSendType" SG_ 1184 OutdAirQlyOutdAirQly 0;
BA_ "GenSigSendType" SG_ 1184 OutdAirQlyQf 0;
BA_ "GenSigSendType" SG_ 643 OutdPm25LvlFrmClima 0;
BA_ "GenSigSendType" SG_ 1184 OutdPm25StsFrmClima 0;
BA_ "GenSigSendType" SG_ 643 OutdPm25VluFrmClima 0;
BA_ "GenSigSendType" SG_ 451 PassMassgRunng 0;
BA_ "GenSigSendType" SG_ 451 PassSeatActvSpplFct 0;
BA_ "GenSigSendType" SG_ 310 PassSeatBtnPsd 0;
BA_ "GenSigSendType" SG_ 441 PassSeatCushDownPosPercSeatPosPerc 0;
BA_ "GenSigSendType" SG_ 441 PassSeatCushDownPosPercSeatPosQf 0;
BA_ "GenSigSendType" SG_ 441 PassSeatFoldFailFb 0;
BA_ "GenSigSendType" SG_ 310 PassSeatFoldSts 0;
BA_ "GenSigSendType" SG_ 1184 PassSeatHeatgActlPwrCns 0;
BA_ "GenSigSendType" SG_ 643 PassSeatHeatgAutoSts 0;
BA_ "GenSigSendType" SG_ 643 PassSeatHeatgAvlSts 0;
BA_ "GenSigSendType" SG_ 1184 PassSeatHeatgDesPwrCns 0;
BA_ "GenSigSendType" SG_ 451 PassSeatHeatgLvlSts 0;
BA_ "GenSigSendType" SG_ 1184 PassSeatHeatgPwrAllwd 0;
BA_ "GenSigStartValue" SG_ 1184 PassSeatHeatgPwrAllwd 100;
BA_ "GenSigSendType" SG_ 310 PassSeatInAutMovmt 0;
BA_ "GenSigSendType" SG_ 310 PassSeatPosFrntExtPercSeatPosPerc 0;
BA_ "GenSigStartValue" SG_ 310 PassSeatPosFrntExtPercSeatPosPerc 1000;
BA_ "GenSigSendType" SG_ 310 PassSeatPosFrntExtPercSeatPosQf 0;
BA_ "GenSigStartValue" SG_ 310 PassSeatPosFrntExtPercSeatPosQf 1;
BA_ "GenSigSendType" SG_ 441 PassSeatPosPercSeatPosFrntHeiPerc 0;
BA_ "GenSigStartValue" SG_ 441 PassSeatPosPercSeatPosFrntHeiPerc 1000;
BA_ "GenSigSendType" SG_ 441 PassSeatPosPercSeatPosFrntHeiQF 0;
BA_ "GenSigStartValue" SG_ 441 PassSeatPosPercSeatPosFrntHeiQF 1;
BA_ "GenSigSendType" SG_ 441 PassSeatPosPercSeatPosHeiPerc 0;
BA_ "GenSigStartValue" SG_ 441 PassSeatPosPercSeatPosHeiPerc 1000;
BA_ "GenSigSendType" SG_ 441 PassSeatPosPercSeatPosHeiQF 0;
BA_ "GenSigStartValue" SG_ 441 PassSeatPosPercSeatPosHeiQF 1;
BA_ "GenSigSendType" SG_ 441 PassSeatPosPercSeatPosSldPerc 0;
BA_ "GenSigStartValue" SG_ 441 PassSeatPosPercSeatPosSldPerc 1000;
BA_ "GenSigSendType" SG_ 441 PassSeatPosPercSeatPosSldQF 0;
BA_ "GenSigStartValue" SG_ 441 PassSeatPosPercSeatPosSldQF 1;
BA_ "GenSigSendType" SG_ 451 PassSeatSwtSts2PassSeatSwtAdjmtOfSpplFctHozlSts 0;
BA_ "GenSigSendType" SG_ 451 PassSeatSwtSts2PassSeatSwtAdjmtOfSpplFctVerSts 0;
BA_ "GenSigSendType" SG_ 451 PassSeatSwtSts2PassSeatSwtHdrstHozlSts 0;
BA_ "GenSigSendType" SG_ 451 PassSeatSwtSts2PassSeatSwtHdrstVertSts 0;
BA_ "GenSigSendType" SG_ 451 PassSeatSwtSts2PassSeatSwtHeiFrntSts 0;
BA_ "GenSigSendType" SG_ 451 PassSeatSwtSts2PassSeatSwtHeiSts 0;
BA_ "GenSigSendType" SG_ 451 PassSeatSwtSts2PassSeatSwtInclSts 0;
BA_ "GenSigSendType" SG_ 451 PassSeatSwtSts2PassSeatSwtSelnOfSpplFctStsSts 0;
BA_ "GenSigSendType" SG_ 451 PassSeatSwtSts2PassSeatSwtSldSts 0;
BA_ "GenSigSendType" SG_ 600 PassSeatVentAvlSts 0;
BA_ "GenSigSendType" SG_ 1184 PassSeatVentnActlPwrCns 0;
BA_ "GenSigSendType" SG_ 643 PassSeatVentnAutoSts 0;
BA_ "GenSigSendType" SG_ 1184 PassSeatVentnDesPwrCns 0;
BA_ "GenSigSendType" SG_ 451 PassSeatVentnLvlSts 0;
BA_ "GenSigSendType" SG_ 1184 PassSeatVentnPwrAllwd 0;
BA_ "GenSigSendType" SG_ 310 PawlPassReSwt 0;
BA_ "GenSigSendType" SG_ 310 PawlPassSwt 0;
BA_ "GenSigSendType" SG_ 600 PrkgClimaWarn 0;
BA_ "GenSigSendType" SG_ 1184 PwrAllwdForElecAirVentn 0;
BA_ "GenSigSendType" SG_ 451 PwrEstimdAtStbForClima 0;
BA_ "GenSigSendType" SG_ 803 ReHvacBlowerSts 0;
BA_ "GenSigSendType" SG_ 803 ReHvacHexAirTHvacAirTForHeatrFrnt 0;
BA_ "GenSigSendType" SG_ 803 ReHvacHexAirTHvacAirTForHeatrFrntQf 0;
BA_ "GenSigStartValue" SG_ 803 ReHvacHexAirTHvacAirTForHeatrFrntQf 1;
BA_ "GenSigSendType" SG_ 803 RemClimaActv 0;
BA_ "GenSigSendType" SG_ 643 RemClimaDefrstSts 0;
BA_ "GenSigSendType" SG_ 455 RemClimaDelaySts 1;
BA_ "GenSigSendType" SG_ 455 RemClimaExtnTiRspn 1;
BA_ "GenSigSendType" SG_ 455 RemClimaHvRspn 1;
BA_ "GenSigSendType" SG_ 643 RemClimaHvSts 0;
BA_ "GenSigSendType" SG_ 455 RemClimaWarn 1;
BA_ "GenSigSendType" SG_ 455 RemStrtClimaRspn 1;
BA_ "GenSigSendType" SG_ 643 RemVentActvSts 0;
BA_ "GenSigSendType" SG_ 643 RemVentReqRspnFb 0;
BA_ "GenSigSendType" SG_ 643 RemVentWarnSts 0;
BA_ "GenSigSendType" SG_ 803 ResrvdSigForECM1 0;
BA_ "GenSigSendType" SG_ 803 ResrvdSigForECM2 0;
BA_ "GenSigSendType" SG_ 803 ResrvdSigForECM3 0;
BA_ "GenSigSendType" SG_ 803 ResrvdSigForECM4 0;
BA_ "GenSigSendType" SG_ 520 RlyCmftForClimaReq 0;
BA_ "GenSigSendType" SG_ 520 RlyCrashForClimaReq 0;
BA_ "GenSigSendType" SG_ 455 RoofOpnReqFrmClima 1;
BA_ "GenSigSendType" SG_ 455 SchedCmptHeatCoolFB 1;
BA_ "GenSigSendType" SG_ 441 SeatBackAngleRowFirstPass 0;
BA_ "GenSigSendType" SG_ 600 SeatClimaDurgClimaHmiSeatHeatgForRowFirstLe 0;
BA_ "GenSigSendType" SG_ 600 SeatClimaDurgClimaHmiSeatHeatgForRowFirstRi 0;
BA_ "GenSigSendType" SG_ 600 SeatClimaDurgClimaHmiSeatHeatgForRowSecLe 0;
BA_ "GenSigSendType" SG_ 600 SeatClimaDurgClimaHmiSeatHeatgForRowSecRi 0;
BA_ "GenSigSendType" SG_ 258 SeatClimaDurgClimaHmiSeatHeatgForRowThrdLe 0;
BA_ "GenSigSendType" SG_ 258 SeatClimaDurgClimaHmiSeatHeatgForRowThrdRi 0;
BA_ "GenSigSendType" SG_ 600 SeatClimaDurgClimaHmiSeatVentnForRowFirstLe 0;
BA_ "GenSigSendType" SG_ 600 SeatClimaDurgClimaHmiSeatVentnForRowFirstRi 0;
BA_ "GenSigSendType" SG_ 600 SeatClimaDurgClimaHmiSeatVentnForRowSecLe 0;
BA_ "GenSigSendType" SG_ 600 SeatClimaDurgClimaHmiSeatVentnForRowSecRi 0;
BA_ "GenSigSendType" SG_ 258 SeatClimaDurgClimaHmiSeatVentnForRowThrdLe 0;
BA_ "GenSigSendType" SG_ 258 SeatClimaDurgClimaHmiSeatVentnForRowThrdRi 0;
BA_ "GenSigSendType" SG_ 441 SeatOccptAtRowSecPasSide2 0;
BA_ "GenSigStartValue" SG_ 441 SeatOccptAtRowSecPasSide2 1;
BA_ "GenSigSendType" SG_ 441 SeatOccptAtRowSecPasSideSnsSts2 0;
BA_ "GenSigSendType" SG_ 310 SecRowLeSeatHeatgPwrAllwd 0;
BA_ "GenSigStartValue" SG_ 310 SecRowLeSeatHeatgPwrAllwd 100;
BA_ "GenSigSendType" SG_ 310 SecRowLeSeatVentnPwrAllwd 0;
BA_ "GenSigSendType" SG_ 310 SecRowRiSeatHeatgPwrAllwd 0;
BA_ "GenSigSendType" SG_ 310 SecRowRiSeatVentnPwrAllwd 0;
BA_ "GenSigSendType" SG_ 310 ShortDropWinPassSts 0;
BA_ "GenSigSendType" SG_ 310 ShortDropWinReRiSts 0;
BA_ "GenSigSendType" SG_ 441 SteerWhlHeatgDurgClima 0;
BA_ "GenSigSendType" SG_ 441 SteerWhlHeatgPwrAllwd 0;
BA_ "GenSigSendType" SG_ 1184 SunDataAzi 0;
BA_ "GenSigSendType" SG_ 1184 SunDataElevn 0;
BA_ "GenSigStartValue" SG_ 1184 SunDataElevn 900;
BA_ "GenSigSendType" SG_ 643 TgtHvacAirTForMaxTZone 0;
BA_ "GenSigStartValue" SG_ 643 TgtHvacAirTForMaxTZone 250;
BA_ "GenSigSendType" SG_ 1184 TgtHvacAirTForRowFirstLe 0;
BA_ "GenSigStartValue" SG_ 1184 TgtHvacAirTForRowFirstLe 250;
BA_ "GenSigSendType" SG_ 1184 TgtHvacAirTForRowFirstRi 0;
BA_ "GenSigStartValue" SG_ 1184 TgtHvacAirTForRowFirstRi 250;
BA_ "GenSigSendType" SG_ 1184 TgtHvacAirTForRowSecLe 0;
BA_ "GenSigStartValue" SG_ 1184 TgtHvacAirTForRowSecLe 250;
BA_ "GenSigSendType" SG_ 1184 TgtHvacAirTForRowSecRi 0;
BA_ "GenSigStartValue" SG_ 1184 TgtHvacAirTForRowSecRi 250;
BA_ "GenSigSendType" SG_ 310 ThrdRowLeSeatHeatgPwrAllwd 0;
BA_ "GenSigSendType" SG_ 310 ThrdRowLeSeatVentnPwrAllwd 0;
BA_ "GenSigSendType" SG_ 310 ThrdRowRiSeatHeatgPwrAllwd 0;
BA_ "GenSigSendType" SG_ 310 ThrdRowRiSeatVentnPwrAllwd 0;
BA_ "GenSigSendType" SG_ 803 TiOfDeactvnForClimaCtrl 0;
BA_ "GenSigSendType" SG_ 803 UBoostReqByClima 0;
BA_ "GenSigSendType" SG_ 1350 VFCVectorZCUPBlockID 0;
BA_ "GenSigSendType" SG_ 1350 VFCVectorZCUPVFCid0 0;
BA_ "GenSigSendType" SG_ 1350 VFCVectorZCUPVFCid1 0;
BA_ "GenSigSendType" SG_ 1350 VFCVectorZCUPVFCid10 0;
BA_ "GenSigSendType" SG_ 1350 VFCVectorZCUPVFCid11 0;
BA_ "GenSigSendType" SG_ 1350 VFCVectorZCUPVFCid12 0;
BA_ "GenSigSendType" SG_ 1350 VFCVectorZCUPVFCid13 0;
BA_ "GenSigSendType" SG_ 1350 VFCVectorZCUPVFCid14 0;
BA_ "GenSigSendType" SG_ 1350 VFCVectorZCUPVFCid15 0;
BA_ "GenSigSendType" SG_ 1350 VFCVectorZCUPVFCid16 0;
BA_ "GenSigSendType" SG_ 1350 VFCVectorZCUPVFCid17 0;
BA_ "GenSigSendType" SG_ 1350 VFCVectorZCUPVFCid18 0;
BA_ "GenSigSendType" SG_ 1350 VFCVectorZCUPVFCid19 0;
BA_ "GenSigSendType" SG_ 1350 VFCVectorZCUPVFCid2 0;
BA_ "GenSigSendType" SG_ 1350 VFCVectorZCUPVFCid20 0;
BA_ "GenSigSendType" SG_ 1350 VFCVectorZCUPVFCid21 0;
BA_ "GenSigSendType" SG_ 1350 VFCVectorZCUPVFCid22 0;
BA_ "GenSigSendType" SG_ 1350 VFCVectorZCUPVFCid23 0;
BA_ "GenSigSendType" SG_ 1350 VFCVectorZCUPVFCid24 0;
BA_ "GenSigSendType" SG_ 1350 VFCVectorZCUPVFCid25 0;
BA_ "GenSigSendType" SG_ 1350 VFCVectorZCUPVFCid26 0;
BA_ "GenSigSendType" SG_ 1350 VFCVectorZCUPVFCid27 0;
BA_ "GenSigSendType" SG_ 1350 VFCVectorZCUPVFCid28 0;
BA_ "GenSigSendType" SG_ 1350 VFCVectorZCUPVFCid29 0;
BA_ "GenSigSendType" SG_ 1350 VFCVectorZCUPVFCid3 0;
BA_ "GenSigSendType" SG_ 1350 VFCVectorZCUPVFCid30 0;
BA_ "GenSigSendType" SG_ 1350 VFCVectorZCUPVFCid31 0;
BA_ "GenSigSendType" SG_ 1350 VFCVectorZCUPVFCid32 0;
BA_ "GenSigSendType" SG_ 1350 VFCVectorZCUPVFCid33 0;
BA_ "GenSigSendType" SG_ 1350 VFCVectorZCUPVFCid34 0;
BA_ "GenSigSendType" SG_ 1350 VFCVectorZCUPVFCid35 0;
BA_ "GenSigSendType" SG_ 1350 VFCVectorZCUPVFCid36 0;
BA_ "GenSigSendType" SG_ 1350 VFCVectorZCUPVFCid37 0;
BA_ "GenSigSendType" SG_ 1350 VFCVectorZCUPVFCid38 0;
BA_ "GenSigSendType" SG_ 1350 VFCVectorZCUPVFCid39 0;
BA_ "GenSigSendType" SG_ 1350 VFCVectorZCUPVFCid4 0;
BA_ "GenSigSendType" SG_ 1350 VFCVectorZCUPVFCid40 0;
BA_ "GenSigSendType" SG_ 1350 VFCVectorZCUPVFCid41 0;
BA_ "GenSigSendType" SG_ 1350 VFCVectorZCUPVFCid42 0;
BA_ "GenSigSendType" SG_ 1350 VFCVectorZCUPVFCid43 0;
BA_ "GenSigSendType" SG_ 1350 VFCVectorZCUPVFCid44 0;
BA_ "GenSigSendType" SG_ 1350 VFCVectorZCUPVFCid45 0;
BA_ "GenSigSendType" SG_ 1350 VFCVectorZCUPVFCid46 0;
BA_ "GenSigSendType" SG_ 1350 VFCVectorZCUPVFCid47 0;
BA_ "GenSigSendType" SG_ 1350 VFCVectorZCUPVFCid48 0;
BA_ "GenSigSendType" SG_ 1350 VFCVectorZCUPVFCid49 0;
BA_ "GenSigSendType" SG_ 1350 VFCVectorZCUPVFCid5 0;
BA_ "GenSigSendType" SG_ 1350 VFCVectorZCUPVFCid50 0;
BA_ "GenSigSendType" SG_ 1350 VFCVectorZCUPVFCid51 0;
BA_ "GenSigSendType" SG_ 1350 VFCVectorZCUPVFCid52 0;
BA_ "GenSigSendType" SG_ 1350 VFCVectorZCUPVFCid53 0;
BA_ "GenSigSendType" SG_ 1350 VFCVectorZCUPVFCid54 0;
BA_ "GenSigSendType" SG_ 1350 VFCVectorZCUPVFCid55 0;
BA_ "GenSigSendType" SG_ 1350 VFCVectorZCUPVFCid56 0;
BA_ "GenSigSendType" SG_ 1350 VFCVectorZCUPVFCid57 0;
BA_ "GenSigSendType" SG_ 1350 VFCVectorZCUPVFCid58 0;
BA_ "GenSigSendType" SG_ 1350 VFCVectorZCUPVFCid59 0;
BA_ "GenSigSendType" SG_ 1350 VFCVectorZCUPVFCid6 0;
BA_ "GenSigSendType" SG_ 1350 VFCVectorZCUPVFCid60 0;
BA_ "GenSigSendType" SG_ 1350 VFCVectorZCUPVFCid61 0;
BA_ "GenSigSendType" SG_ 1350 VFCVectorZCUPVFCid7 0;
BA_ "GenSigSendType" SG_ 1350 VFCVectorZCUPVFCid8 0;
BA_ "GenSigSendType" SG_ 1350 VFCVectorZCUPVFCid9 0;
BA_ "GenSigSendType" SG_ 1286 WakeUpReasonsforZCUP 0;
BA_ "GenSigSendType" SG_ 455 WinAndRoofReqFrmClima 1;
BA_ "GenSigSendType" SG_ 310 WinDsblPassReSts 0;
BA_ "GenSigSendType" SG_ 310 WinDsblRightSts 0;
BA_ "GenSigSendType" SG_ 643 WinFailrStsAtPass 0;
BA_ "GenSigSendType" SG_ 310 WinFailrStsAtPassRe 0;
BA_ "GenSigSendType" SG_ 643 WinFailrStsAtReRi 0;
BA_ "GenSigSendType" SG_ 882 WinHwSwtPassDoor 0;
BA_ "GenSigSendType" SG_ 882 WinHwSwtPassReDoor 0;
BA_ "GenSigSendType" SG_ 310 WinPosnStsAtPassRe 0;
VAL_ 441 AjarChrgLidRearSwitch 0 "DoorSts2_Ukwn" 1 "DoorSts2_Opend" 2 "DoorSts2_Clsd";
VAL_ 441 AjarFuelFlapSwitch 0 "DoorSts2_Ukwn" 1 "DoorSts2_Opend" 2 "DoorSts2_Clsd";
VAL_ 441 ClimaCmptSts 0 "CmptSts_NoRequest" 1 "CmptSts_CoolingRequest" 2 "CmptSts_HeatingRequest" 3 "CmptSts_CoolingAndHeatingRequest" 4 "CmptSts_PostHeating";
VAL_ 441 ClimaCtrlActv 0 "Boolean_FALSE" 1 "Boolean_TRUE";
VAL_ 441 ClimaDefrstSts 0 "OnOff1_Off" 1 "OnOff1_On";
VAL_ 441 DoorPass2Swt1DplyHndl 0 "PsdNotPsd1_NotPsd" 1 "PsdNotPsd1_Psd";
VAL_ 441 DoorPass2Swt2DplyHndl 0 "PsdNotPsd1_NotPsd" 1 "PsdNotPsd1_Psd";
VAL_ 441 DoorPassLatPosn 0 "DoorPos_Undefined" 1 "DoorPos_FullyClosed" 2 "DoorPos_SecondaryPosition" 3 "DoorPos_FullyOpen";
VAL_ 441 DoorPassRe2Sw1DplyHndl 0 "PsdNotPsd1_NotPsd" 1 "PsdNotPsd1_Psd";
VAL_ 441 DoorPassRe2Sw2DplyHndl 0 "PsdNotPsd1_NotPsd" 1 "PsdNotPsd1_Psd";
VAL_ 441 EngSpdIncIdleForClima 0 "Flg1_Rst" 1 "Flg1_Set";
VAL_ 441 FltOfReRegPlateLamp 0 "DevErrSts2_NoFlt" 1 "DevErrSts2_Flt";
VAL_ 441 IceBreakDoorPassActv 0 "Boolean_FALSE" 1 "Boolean_TRUE";
VAL_ 441 MirrAtPassInMovmt 0 "Boolean_FALSE" 1 "Boolean_TRUE";
VAL_ 441 PassSeatCushDownPosPercSeatPosQf 0 "Qf1_DevOfDataUndefd" 1 "Qf1_DataTmpUndefdAndEvlnInProgs" 2 "Qf1_DevOfDataNotWithinRngAllwd" 3 "Qf1_DataCalcdWithDevDefd";
VAL_ 441 PassSeatPosPercSeatPosFrntHeiQF 0 "Qf1_DevOfDataUndefd" 1 "Qf1_DataTmpUndefdAndEvlnInProgs" 2 "Qf1_DevOfDataNotWithinRngAllwd" 3 "Qf1_DataCalcdWithDevDefd";
VAL_ 441 PassSeatPosPercSeatPosHeiQF 0 "Qf1_DevOfDataUndefd" 1 "Qf1_DataTmpUndefdAndEvlnInProgs" 2 "Qf1_DevOfDataNotWithinRngAllwd" 3 "Qf1_DataCalcdWithDevDefd";
VAL_ 441 PassSeatPosPercSeatPosSldQF 0 "Qf1_DevOfDataUndefd" 1 "Qf1_DataTmpUndefdAndEvlnInProgs" 2 "Qf1_DevOfDataNotWithinRngAllwd" 3 "Qf1_DataCalcdWithDevDefd";
VAL_ 441 SeatOccptAtRowSecPasSide2 0 "OccptPresSt1_Undefd1" 1 "OccptPresSt1_OccptNotPrsnt" 2 "OccptPresSt1_OccptPrsnt" 3 "OccptPresSt1_Undefd2";
VAL_ 441 SeatOccptAtRowSecPasSideSnsSts2 0 "OkNokDi_Ok" 1 "OkNokDi_NotOk" 2 "OkNokDi_Disabled" 3 "OkNokDi_Reserved";
VAL_ 441 SteerWhlHeatgDurgClima 0 "Boolean_FALSE" 1 "Boolean_TRUE";
VAL_ 801 AmbTEstimdQf 0 "HvacTIfQf_SnsrDataNotOk" 1 "HvacTIfQf_SnsrDataOk";
VAL_ 801 ClimaOvrHeatPrtSts 0 "OnOff1_Off" 1 "OnOff1_On";
VAL_ 801 CmptmtAirTEstimdExtdQlyFlg 0 "GenQf1_UndefindDataAccur" 1 "GenQf1_TmpUndefdData" 2 "GenQf1_DataAccurNotWithinSpcn" 3 "GenQf1_AccurData";
VAL_ 520 AmbTRawAtPassSideQly 0 "GenQf1_UndefindDataAccur" 1 "GenQf1_TmpUndefdData" 2 "GenQf1_DataAccurNotWithinSpcn" 3 "GenQf1_AccurData";
VAL_ 520 RlyCmftForClimaReq 0 "OnOff1_Off" 1 "OnOff1_On";
VAL_ 520 RlyCrashForClimaReq 0 "OnOff1_Off" 1 "OnOff1_On";
VAL_ 58 DoorPassOpenLowReqOutdSwt1 0 "PsdNotPsd3_NoInfo1" 1 "PsdNotPsd3_Psd" 2 "PsdNotPsd3_NotPsd" 3 "PsdNotPsd3_NoInfo2";
VAL_ 58 DoorPassOpenReqInsdSwt1 0 "PsdNotPsd3_NoInfo1" 1 "PsdNotPsd3_Psd" 2 "PsdNotPsd3_NotPsd" 3 "PsdNotPsd3_NoInfo2";
VAL_ 58 DoorPassReCinhIntFailInfCinchFlt1 0 "Boolean_FALSE" 1 "Boolean_TRUE";
VAL_ 58 DoorPassReCinhIntFailInfCinchRestFlt 0 "Boolean_FALSE" 1 "Boolean_TRUE";
VAL_ 58 DoorPassReLatPosn 0 "DoorPos_Undefined" 1 "DoorPos_FullyClosed" 2 "DoorPos_SecondaryPosition" 3 "DoorPos_FullyOpen";
VAL_ 58 DoorPassReOpenLowReqOutdSwt1 0 "PsdNotPsd3_NoInfo1" 1 "PsdNotPsd3_Psd" 2 "PsdNotPsd3_NotPsd" 3 "PsdNotPsd3_NoInfo2";
VAL_ 58 DoorPassReOpenReqInsdSwt1 0 "PsdNotPsd3_NoInfo1" 1 "PsdNotPsd3_Psd" 2 "PsdNotPsd3_NotPsd" 3 "PsdNotPsd3_NoInfo2";
VAL_ 58 DoorPassReRelsFailCinchOverTimed 0 "Boolean_FALSE" 1 "Boolean_TRUE";
VAL_ 58 DoorPassReRelsFailFailure1 0 "Boolean_FALSE" 1 "Boolean_TRUE";
VAL_ 58 DoorPassReRelsFailMechRels 0 "Boolean_FALSE" 1 "Boolean_TRUE";
VAL_ 58 DoorRiReLatPosn 0 "DoorPos_Undefined" 1 "DoorPos_FullyClosed" 2 "DoorPos_SecondaryPosition" 3 "DoorPos_FullyOpen";
VAL_ 58 DoorRiReOpenLowReqOutdSwt1 0 "PsdNotPsd3_NoInfo1" 1 "PsdNotPsd3_Psd" 2 "PsdNotPsd3_NotPsd" 3 "PsdNotPsd3_NoInfo2";
VAL_ 58 DoorRiReOpenReqInsdSwt1 0 "PsdNotPsd3_NoInfo1" 1 "PsdNotPsd3_Psd" 2 "PsdNotPsd3_NotPsd" 3 "PsdNotPsd3_NoInfo2";
VAL_ 58 IceBreakDoorPassReActv 0 "Boolean_FALSE" 1 "Boolean_TRUE";
VAL_ 310 AutDemstOperSts 0 "OnOff1_Off" 1 "OnOff1_On";
VAL_ 310 ChdLockPassReSts 0 "OnOffSafe1_OnOffSafeInvld1" 1 "OnOffSafe1_OnOffSafeOn" 2 "OnOffSafe1_OnOffSafeOff" 3 "OnOffSafe1_OnOffSafeInvld2";
VAL_ 310 ChdLockRightSts 0 "OnOffSafe1_OnOffSafeInvld1" 1 "OnOffSafe1_OnOffSafeOn" 2 "OnOffSafe1_OnOffSafeOff" 3 "OnOffSafe1_OnOffSafeInvld2";
VAL_ 310 ChrgLidDCorAcDctSwtReq 0 "PsdNotPsd1_NotPsd" 1 "PsdNotPsd1_Psd";
VAL_ 310 CinhPassReSts 0 "PsdNotPsd1_NotPsd" 1 "PsdNotPsd1_Psd";
VAL_ 310 CinhPassReSwt 0 "PsdNotPsd1_NotPsd" 1 "PsdNotPsd1_Psd";
VAL_ 310 CinhPassSts 0 "Boolean_FALSE" 1 "Boolean_TRUE";
VAL_ 310 CinhPassSwt 0 "PsdNotPsd1_NotPsd" 1 "PsdNotPsd1_Psd";
VAL_ 310 CmptmtTFrntFanForCmptmtTRunng 0 "Flg1_Rst" 1 "Flg1_Set";
VAL_ 310 CmptmtTFrntQf 0 "CmptmtTFrntQf_SnsrDataUndefd" 1 "CmptmtTFrntQf_FanNotRunning" 2 "CmptmtTFrntQf_SnsrDataNotOk" 3 "CmptmtTFrntQf_SnsrDataOk";
VAL_ 310 DoorPassReHndlSts 0 "DoorHndlSts_Ukwn" 1 "DoorHndlSts_FullRtrctd" 2 "DoorHndlSts_MovgOut" 3 "DoorHndlSts_StopDurgDply" 4 "DoorHndlSts_FullDplyd" 5 "DoorHndlSts_MovgIn" 6 "DoorHndlSts_StopDurgRtrct" 7 "DoorHndlSts_Flt";
VAL_ 310 EvaprTFrntEvaprTQf 0 "HvacTIfQf_SnsrDataNotOk" 1 "HvacTIfQf_SnsrDataOk";
VAL_ 310 FltOfBeamHiPass 0 "DevErrSts2_NoFlt" 1 "DevErrSts2_Flt";
VAL_ 310 FltOfBeamLoPass 0 "DevErrSts2_NoFlt" 1 "DevErrSts2_Flt";
VAL_ 310 FltOfDaytiRunngLampPass 0 "DevErrSts2_NoFlt" 1 "DevErrSts2_Flt";
VAL_ 310 FltOfFrntFogLampPass 0 "DevErrSts2_NoFlt" 1 "DevErrSts2_Flt";
VAL_ 310 FltOfFrntPosnLampPass 0 "DevErrSts2_NoFlt" 1 "DevErrSts2_Flt";
VAL_ 310 FltOfReFogLampDrv 0 "DevErrSts2_NoFlt" 1 "DevErrSts2_Flt";
VAL_ 310 FltOfRePosnLampPass 0 "DevErrSts2_NoFlt" 1 "DevErrSts2_Flt";
VAL_ 310 FltOfRvsgLampPass 0 "DevErrSts2_NoFlt" 1 "DevErrSts2_Flt";
VAL_ 310 HvacCoolgEnaRe 0 "OnOff1_Off" 1 "OnOff1_On";
VAL_ 310 HvahAirTEstmdEvaprTQf 0 "HvacTIfQf_SnsrDataNotOk" 1 "HvacTIfQf_SnsrDataOk";
VAL_ 310 IceBreakDoorRiReActv 0 "Boolean_FALSE" 1 "Boolean_TRUE";
VAL_ 310 IntPm25StsFrmClima 0 "PmSnsrSts_Initial" 1 "PmSnsrSts_Collecting" 2 "PmSnsrSts_Complete" 3 "PmSnsrSts_Error";
VAL_ 310 MirrDwnStsAtPass 0 "MirrDwnStsTyp_MirrTiltUndefd" 1 "MirrDwnStsTyp_MirrUpPosn" 2 "MirrDwnStsTyp_MirrTiltPosn" 3 "MirrDwnStsTyp_MirrMovgToUpPosn" 4 "MirrDwnStsTyp_MirrMovgToTiltPosn";
VAL_ 310 OpenPassReSwt 0 "PsdNotPsd1_NotPsd" 1 "PsdNotPsd1_Psd";
VAL_ 310 OpenPassSwt 0 "PsdNotPsd1_NotPsd" 1 "PsdNotPsd1_Psd";
VAL_ 310 PassSeatBtnPsd 0 "Boolean_FALSE" 1 "Boolean_TRUE";
VAL_ 310 PassSeatFoldSts 0 "FoldRaiseMovmt_Uknwn" 1 "FoldRaiseMovmt_Fld" 2 "FoldRaiseMovmt_Rsd" 3 "FoldRaiseMovmt_MovmtToFld" 4 "FoldRaiseMovmt_MovmtToRsd" 5 "FoldRaiseMovmt_BtwnFldAndRsd";
VAL_ 310 PassSeatInAutMovmt 0 "Boolean_FALSE" 1 "Boolean_TRUE";
VAL_ 310 PassSeatPosFrntExtPercSeatPosQf 0 "Qf1_DevOfDataUndefd" 1 "Qf1_DataTmpUndefdAndEvlnInProgs" 2 "Qf1_DevOfDataNotWithinRngAllwd" 3 "Qf1_DataCalcdWithDevDefd";
VAL_ 310 PawlPassReSwt 0 "PsdNotPsd1_NotPsd" 1 "PsdNotPsd1_Psd";
VAL_ 310 PawlPassSwt 0 "PsdNotPsd1_NotPsd" 1 "PsdNotPsd1_Psd";
VAL_ 310 ShortDropWinPassSts 0 "ShortDropSts_Idle" 1 "ShortDropSts_WindowDown" 2 "ShortDropSts_WindowClosed" 3 "ShortDropSts_NotUsed";
VAL_ 310 ShortDropWinReRiSts 0 "ShortDropSts_Idle" 1 "ShortDropSts_WindowDown" 2 "ShortDropSts_WindowClosed" 3 "ShortDropSts_NotUsed";
VAL_ 310 WinDsblPassReSts 0 "OnOff1_Off" 1 "OnOff1_On";
VAL_ 310 WinDsblRightSts 0 "OnOff1_Off" 1 "OnOff1_On";
VAL_ 310 WinFailrStsAtPassRe 0 "Flt_NoFault" 1 "Flt_Fault";
VAL_ 310 WinPosnStsAtPassRe 0 "WinAndRoofAndCurtPosnTyp_PosnUkwn" 1 "WinAndRoofAndCurtPosnTyp_ClsFull" 2 "WinAndRoofAndCurtPosnTyp_PercOpen4" 3 "WinAndRoofAndCurtPosnTyp_PercOpen8" 4 "WinAndRoofAndCurtPosnTyp_PercOpen12" 5 "WinAndRoofAndCurtPosnTyp_PercOpen16" 6 "WinAndRoofAndCurtPosnTyp_PercOpen20" 7 "WinAndRoofAndCurtPosnTyp_PercOpen24" 8 "WinAndRoofAndCurtPosnTyp_PercOpen28" 9 "WinAndRoofAndCurtPosnTyp_PercOpen32" 10 "WinAndRoofAndCurtPosnTyp_PercOpen36" 11 "WinAndRoofAndCurtPosnTyp_PercOpen40" 12 "WinAndRoofAndCurtPosnTyp_PercOpen44" 13 "WinAndRoofAndCurtPosnTyp_PercOpen48" 14 "WinAndRoofAndCurtPosnTyp_PercOpen52" 15 "WinAndRoofAndCurtPosnTyp_PercOpen56" 16 "WinAndRoofAndCurtPosnTyp_PercOpen60" 17 "WinAndRoofAndCurtPosnTyp_PercOpen64" 18 "WinAndRoofAndCurtPosnTyp_PercOpen68" 19 "WinAndRoofAndCurtPosnTyp_PercOpen72" 20 "WinAndRoofAndCurtPosnTyp_PercOpen76" 21 "WinAndRoofAndCurtPosnTyp_PercOpen80" 22 "WinAndRoofAndCurtPosnTyp_PercOpen84" 23 "WinAndRoofAndCurtPosnTyp_PercOpen88" 24 "WinAndRoofAndCurtPosnTyp_PercOpen92" 25 "WinAndRoofAndCurtPosnTyp_PercOpen96" 26 "WinAndRoofAndCurtPosnTyp_OpenFull" 27 "WinAndRoofAndCurtPosnTyp_Resd1" 28 "WinAndRoofAndCurtPosnTyp_Resd2" 29 "WinAndRoofAndCurtPosnTyp_Resd3" 30 "WinAndRoofAndCurtPosnTyp_Resd4" 31 "WinAndRoofAndCurtPosnTyp_Movg";
VAL_ 1184 CmptmtIntrMtrlTEstimdMtrlSnsrTQly2 0 "Qly2_Flt" 1 "Qly2_NoInfo" 2 "Qly2_Vld";
VAL_ 1184 OutdAirQlyOutdAirQly 0 "AirQly_No" 1 "AirQly_LvlLo" 2 "AirQly_LvlMed" 3 "AirQly_LvlHi";
VAL_ 1184 OutdAirQlyQf 0 "OutdAirQlyQf_SnsrNotOk" 1 "OutdAirQlyQf_SnsrOk";
VAL_ 1184 OutdPm25StsFrmClima 0 "PmSnsrSts_Initial" 1 "PmSnsrSts_Collecting" 2 "PmSnsrSts_Complete" 3 "PmSnsrSts_Error";
VAL_ 600 ClimaActv 0 "OnOff1_Off" 1 "OnOff1_On";
VAL_ 600 ElecAirVentnAvlSts 0 "StsFd_None" 1 "StsFd_On" 2 "StsFd_Off" 3 "StsFd_Error" 4 "StsFd_Functionallimit" 5 "StsFd_Energylimit" 6 "StsFd_Resvd1" 7 "StsFd_Resvd2";
VAL_ 600 ElecDefrstReqMirrDefrstReq 0 "OnOff1_Off" 1 "OnOff1_On";
VAL_ 600 ElecDefrstReqWinDefrstFrntReq 0 "OnOff1_Off" 1 "OnOff1_On";
VAL_ 600 ElecDefrstReqWinDefrstReReq 0 "OnOff1_Off" 1 "OnOff1_On";
VAL_ 600 EvaprTReEvaprTQf 0 "HvacTIfQf_SnsrDataNotOk" 1 "HvacTIfQf_SnsrDataOk";
VAL_ 600 FragCh1UseUpWrn 0 "Warn2_NoWarn" 1 "Warn2_Warn";
VAL_ 600 FragCh2UseUpWrn 0 "Warn2_NoWarn" 1 "Warn2_Warn";
VAL_ 600 FragCh3UseUpWrn 0 "Warn2_NoWarn" 1 "Warn2_Warn";
VAL_ 600 FragCh4UseUpWrn 0 "Warn2_NoWarn" 1 "Warn2_Warn";
VAL_ 600 FragCh5UseUpWrn 0 "Warn2_NoWarn" 1 "Warn2_Warn";
VAL_ 600 FragLvlFrmClima 0 "RatUse_NoRequest" 1 "RatUse_Low" 2 "RatUse_Mid" 3 "RatUse_High";
VAL_ 600 FragStsFrmClima 1 "AirFragSts_OFF" 2 "AirFragSts_ON" 3 "AirFragSts_Error";
VAL_ 600 IntPm25HiPopUp 0 "IntPmHiPopUp_NoReq" 1 "IntPmHiPopUp_ClimaOn" 2 "IntPmHiPopUp_ClimaOnAndWinClsd" 3 "IntPmHiPopUp_Reserved";
VAL_ 600 PassSeatVentAvlSts 0 "StsFd_None" 1 "StsFd_On" 2 "StsFd_Off" 3 "StsFd_Error" 4 "StsFd_Functionallimit" 5 "StsFd_Energylimit" 6 "StsFd_Resvd1" 7 "StsFd_Resvd2";
VAL_ 600 PrkgClimaWarn 0 "ClimaWarn_NoWarn" 1 "ClimaWarn_FuLo" 2 "ClimaWarn_BattLo" 3 "ClimaWarn_FuAndBattLo" 4 "ClimaWarn_TLo" 5 "ClimaWarn_THi" 6 "ClimaWarn_Error" 7 "ClimaWarn_HVError" 8 "ClimaWarn_ActvnLimd";
VAL_ 600 SeatClimaDurgClimaHmiSeatHeatgForRowFirstLe 0 "SeatClimaLvl_Off" 1 "SeatClimaLvl_Lvl1" 2 "SeatClimaLvl_Lvl2" 3 "SeatClimaLvl_Lvl3";
VAL_ 600 SeatClimaDurgClimaHmiSeatHeatgForRowFirstRi 0 "SeatClimaLvl_Off" 1 "SeatClimaLvl_Lvl1" 2 "SeatClimaLvl_Lvl2" 3 "SeatClimaLvl_Lvl3";
VAL_ 600 SeatClimaDurgClimaHmiSeatHeatgForRowSecLe 0 "SeatClimaLvl_Off" 1 "SeatClimaLvl_Lvl1" 2 "SeatClimaLvl_Lvl2" 3 "SeatClimaLvl_Lvl3";
VAL_ 600 SeatClimaDurgClimaHmiSeatHeatgForRowSecRi 0 "SeatClimaLvl_Off" 1 "SeatClimaLvl_Lvl1" 2 "SeatClimaLvl_Lvl2" 3 "SeatClimaLvl_Lvl3";
VAL_ 600 SeatClimaDurgClimaHmiSeatVentnForRowFirstLe 0 "SeatClimaLvl_Off" 1 "SeatClimaLvl_Lvl1" 2 "SeatClimaLvl_Lvl2" 3 "SeatClimaLvl_Lvl3";
VAL_ 600 SeatClimaDurgClimaHmiSeatVentnForRowFirstRi 0 "SeatClimaLvl_Off" 1 "SeatClimaLvl_Lvl1" 2 "SeatClimaLvl_Lvl2" 3 "SeatClimaLvl_Lvl3";
VAL_ 600 SeatClimaDurgClimaHmiSeatVentnForRowSecLe 0 "SeatClimaLvl_Off" 1 "SeatClimaLvl_Lvl1" 2 "SeatClimaLvl_Lvl2" 3 "SeatClimaLvl_Lvl3";
VAL_ 600 SeatClimaDurgClimaHmiSeatVentnForRowSecRi 0 "SeatClimaLvl_Off" 1 "SeatClimaLvl_Lvl1" 2 "SeatClimaLvl_Lvl2" 3 "SeatClimaLvl_Lvl3";
VAL_ 803 ClimaCoolgReqLvl 0 "HvBattCoolgReq_NotReqd" 1 "HvBattCoolgReq_LoReq" 2 "HvBattCoolgReq_MedReq" 3 "HvBattCoolgReq_HiReq";
VAL_ 803 ClimaHeatgReqLvl 0 "HvBattCoolgReq_NotReqd" 1 "HvBattCoolgReq_LoReq" 2 "HvBattCoolgReq_MedReq" 3 "HvBattCoolgReq_HiReq";
VAL_ 803 CmptModForHp 0 "ModeCmptHp_vent" 1 "ModeCmptHp_cool" 2 "ModeCmptHp_hot" 3 "ModeCmptHp_cool_hot" 4 "ModeCmptHp_cool_defog" 5 "ModeCmptHp_hot_defog" 6 "ModeCmptHp_cool_hot_defog" 7 "ModeCmptHp_reserved";
VAL_ 803 CmptmtTReCmptmtTFrntQf 0 "CmptmtTFrntQf_SnsrDataUndefd" 1 "CmptmtTFrntQf_FanNotRunning" 2 "CmptmtTFrntQf_SnsrDataNotOk" 3 "CmptmtTFrntQf_SnsrDataOk";
VAL_ 803 CmptmtTReFanForCmptmtTRunng 0 "Flg1_Rst" 1 "Flg1_Set";
VAL_ 803 FrntHvacBlowerSts 0 "HvacFanSts_Off" 1 "HvacFanSts_On" 2 "HvacFanSts_Warning" 3 "HvacFanSts_Error";
VAL_ 803 HpReqCritSts 0 "OnOff1_Off" 1 "OnOff1_On";
VAL_ 803 HvacAirTForRowFirstAtFlrLeEvaprTQf 0 "HvacTIfQf_SnsrDataNotOk" 1 "HvacTIfQf_SnsrDataOk";
VAL_ 803 HvacAirTForRowFirstAtFlrRiEvaprTQf 0 "HvacTIfQf_SnsrDataNotOk" 1 "HvacTIfQf_SnsrDataOk";
VAL_ 803 HvacAirTForRowFirstAtVentLeEvaprTQf 0 "HvacTIfQf_SnsrDataNotOk" 1 "HvacTIfQf_SnsrDataOk";
VAL_ 803 HvacAirTForRowFirstAtVentRiEvaprTQf 0 "HvacTIfQf_SnsrDataNotOk" 1 "HvacTIfQf_SnsrDataOk";
VAL_ 803 HvacAirTForRowSecAtFlrLeEvaprTQf 0 "HvacTIfQf_SnsrDataNotOk" 1 "HvacTIfQf_SnsrDataOk";
VAL_ 803 HvacAirTForRowSecAtFlrRiEvaprTQf 0 "HvacTIfQf_SnsrDataNotOk" 1 "HvacTIfQf_SnsrDataOk";
VAL_ 803 HvacAirTForRowSecAtVentLeEvaprTQf 0 "HvacTIfQf_SnsrDataNotOk" 1 "HvacTIfQf_SnsrDataOk";
VAL_ 803 HvacAirTForRowSecAtVentRiEvaprTQf 0 "HvacTIfQf_SnsrDataNotOk" 1 "HvacTIfQf_SnsrDataOk";
VAL_ 803 HvacAirTForRowThrdAtFlrRiEvaprTQf 0 "HvacTIfQf_SnsrDataNotOk" 1 "HvacTIfQf_SnsrDataOk";
VAL_ 803 HvacAirTForRowThrdAtVentRiEvaprTQf 0 "HvacTIfQf_SnsrDataNotOk" 1 "HvacTIfQf_SnsrDataOk";
VAL_ 803 HvacCondsorTEvaprTQf 0 "HvacTIfQf_SnsrDataNotOk" 1 "HvacTIfQf_SnsrDataOk";
VAL_ 803 HvacCondsorTspEvaprTQf 0 "HvacTIfQf_SnsrDataNotOk" 1 "HvacTIfQf_SnsrDataOk";
VAL_ 803 HvacHeatrInletTempReqEvaprTQf 0 "HvacTIfQf_SnsrDataNotOk" 1 "HvacTIfQf_SnsrDataOk";
VAL_ 803 HvacOsaAndRecActrQfForHp 0 "Err1_NoErr" 1 "Err1_Err";
VAL_ 803 HvahHeatgReq 0 "OnOff1_Off" 1 "OnOff1_On";
VAL_ 803 MirrDefrstAtPassSts 0 "OnOff1_Off" 1 "OnOff1_On";
VAL_ 803 ReHvacBlowerSts 0 "HvacFanSts_Off" 1 "HvacFanSts_On" 2 "HvacFanSts_Warning" 3 "HvacFanSts_Error";
VAL_ 803 ReHvacHexAirTHvacAirTForHeatrFrntQf 0 "OkNotOk_NotOk" 1 "OkNotOk_Ok";
VAL_ 803 RemClimaActv 0 "OnOff1_Off" 1 "OnOff1_On";
VAL_ 803 UBoostReqByClima 0 "ReqSts1_NotReqd" 1 "ReqSts1_Reqd";
VAL_ 643 CdsParkgClimaActv 0 "OnOff1_Off" 1 "OnOff1_On";
VAL_ 643 ClimaOvrHeatProActv 0 "OnOff1_Off" 1 "OnOff1_On";
VAL_ 643 CmptmtAirDistbnRspAirDistbnDrvr 0 "HmiCmptmtAirDistbnFrnt_Flr" 1 "HmiCmptmtAirDistbnFrnt_Vent" 2 "HmiCmptmtAirDistbnFrnt_Defrst" 3 "HmiCmptmtAirDistbnFrnt_FlrDefrst" 4 "HmiCmptmtAirDistbnFrnt_FlrVent" 5 "HmiCmptmtAirDistbnFrnt_VentDefrst" 6 "HmiCmptmtAirDistbnFrnt_FlrVentDefrst" 7 "HmiCmptmtAirDistbnFrnt_Aut";
VAL_ 643 CmptmtAirDistbnRspAirDistbnPass 0 "HmiCmptmtAirDistbnFrnt_Flr" 1 "HmiCmptmtAirDistbnFrnt_Vent" 2 "HmiCmptmtAirDistbnFrnt_Defrst" 3 "HmiCmptmtAirDistbnFrnt_FlrDefrst" 4 "HmiCmptmtAirDistbnFrnt_FlrVent" 5 "HmiCmptmtAirDistbnFrnt_VentDefrst" 6 "HmiCmptmtAirDistbnFrnt_FlrVentDefrst" 7 "HmiCmptmtAirDistbnFrnt_Aut";
VAL_ 643 CmptmtAirDistbnRspAirDistbnSecLe 0 "HmiCmptmtAirDistbnFrnt_Flr" 1 "HmiCmptmtAirDistbnFrnt_Vent" 2 "HmiCmptmtAirDistbnFrnt_Defrst" 3 "HmiCmptmtAirDistbnFrnt_FlrDefrst" 4 "HmiCmptmtAirDistbnFrnt_FlrVent" 5 "HmiCmptmtAirDistbnFrnt_VentDefrst" 6 "HmiCmptmtAirDistbnFrnt_FlrVentDefrst" 7 "HmiCmptmtAirDistbnFrnt_Aut";
VAL_ 643 CmptmtAirDistbnRspAirDistbnSecRi 0 "HmiCmptmtAirDistbnFrnt_Flr" 1 "HmiCmptmtAirDistbnFrnt_Vent" 2 "HmiCmptmtAirDistbnFrnt_Defrst" 3 "HmiCmptmtAirDistbnFrnt_FlrDefrst" 4 "HmiCmptmtAirDistbnFrnt_FlrVent" 5 "HmiCmptmtAirDistbnFrnt_VentDefrst" 6 "HmiCmptmtAirDistbnFrnt_FlrVentDefrst" 7 "HmiCmptmtAirDistbnFrnt_Aut";
VAL_ 643 CmptmtAirDistbnRspAirDistbnThrd 0 "HmiCmptmtAirDistbnFrnt_Flr" 1 "HmiCmptmtAirDistbnFrnt_Vent" 2 "HmiCmptmtAirDistbnFrnt_Defrst" 3 "HmiCmptmtAirDistbnFrnt_FlrDefrst" 4 "HmiCmptmtAirDistbnFrnt_FlrVent" 5 "HmiCmptmtAirDistbnFrnt_VentDefrst" 6 "HmiCmptmtAirDistbnFrnt_FlrVentDefrst" 7 "HmiCmptmtAirDistbnFrnt_Aut";
VAL_ 643 DoorPassCinhIntFailInfCinchFlt1 0 "Boolean_FALSE" 1 "Boolean_TRUE";
VAL_ 643 DoorPassCinhIntFailInfCinchRestFlt 0 "Boolean_FALSE" 1 "Boolean_TRUE";
VAL_ 643 DoorPassRelsFailCinchOverTimed 0 "Boolean_FALSE" 1 "Boolean_TRUE";
VAL_ 643 DoorPassRelsFailFailure1 0 "Boolean_FALSE" 1 "Boolean_TRUE";
VAL_ 643 DoorPassRelsFailMechRels 0 "Boolean_FALSE" 1 "Boolean_TRUE";
VAL_ 643 DoorRiReCinhIntFailInfCinchFlt1 0 "Boolean_FALSE" 1 "Boolean_TRUE";
VAL_ 643 DoorRiReCinhIntFailInfCinchRestFlt 0 "Boolean_FALSE" 1 "Boolean_TRUE";
VAL_ 643 DoorRiReRelsFailCinchOverTimed 0 "Boolean_FALSE" 1 "Boolean_TRUE";
VAL_ 643 DoorRiReRelsFailFailure1 0 "Boolean_FALSE" 1 "Boolean_TRUE";
VAL_ 643 DoorRiReRelsFailMechRels 0 "Boolean_FALSE" 1 "Boolean_TRUE";
VAL_ 643 HvacAirTForMaxTZoneEvaprTQf 0 "HvacTIfQf_SnsrDataNotOk" 1 "HvacTIfQf_SnsrDataOk";
VAL_ 643 HvacHeatgReq 0 "OnOff1_Off" 1 "OnOff1_On";
VAL_ 643 IntPm25LvlFrmClima 0 "CmpmtAirPmLvl_Level1" 1 "CmpmtAirPmLvl_Level2" 2 "CmpmtAirPmLvl_Level3" 3 "CmpmtAirPmLvl_Level4" 4 "CmpmtAirPmLvl_Level5" 5 "CmpmtAirPmLvl_Level6" 6 "CmpmtAirPmLvl_Reserved" 7 "CmpmtAirPmLvl_Invalid";
VAL_ 643 OutdPm25LvlFrmClima 0 "CmpmtAirPmLvl_Level1" 1 "CmpmtAirPmLvl_Level2" 2 "CmpmtAirPmLvl_Level3" 3 "CmpmtAirPmLvl_Level4" 4 "CmpmtAirPmLvl_Level5" 5 "CmpmtAirPmLvl_Level6" 6 "CmpmtAirPmLvl_Reserved" 7 "CmpmtAirPmLvl_Invalid";
VAL_ 643 PassSeatHeatgAutoSts 0 "OffOnErrInvalid_Off" 1 "OffOnErrInvalid_On" 2 "OffOnErrInvalid_Err" 3 "OffOnErrInvalid_Invalid";
VAL_ 643 PassSeatHeatgAvlSts 0 "StsFd_None" 1 "StsFd_On" 2 "StsFd_Off" 3 "StsFd_Error" 4 "StsFd_Functionallimit" 5 "StsFd_Energylimit" 6 "StsFd_Resvd1" 7 "StsFd_Resvd2";
VAL_ 643 PassSeatVentnAutoSts 0 "OffOnErrInvalid_Off" 1 "OffOnErrInvalid_On" 2 "OffOnErrInvalid_Err" 3 "OffOnErrInvalid_Invalid";
VAL_ 643 RemClimaDefrstSts 0 "OnOff1_Off" 1 "OnOff1_On";
VAL_ 643 RemClimaHvSts 0 "OnOff1_Off" 1 "OnOff1_On";
VAL_ 643 RemVentActvSts 0 "OnOff1_Off" 1 "OnOff1_On";
VAL_ 643 RemVentReqRspnFb 0 "OnOff1_Off" 1 "OnOff1_On";
VAL_ 643 RemVentWarnSts 0 "RemVentWarningSts_NoErr" 1 "RemVentWarningSts_Err" 2 "RemVentWarningSts_PwrNotAllwd" 3 "RemVentWarningSts_EgyNotAllwd";
VAL_ 643 WinFailrStsAtPass 0 "Flt_NoFault" 1 "Flt_Fault";
VAL_ 643 WinFailrStsAtReRi 0 "Flt_NoFault" 1 "Flt_Fault";
VAL_ 882 ClimaActvAlrmSts 0 "OnOff1_Off" 1 "OnOff1_On";
VAL_ 882 HvacHexAirTHvacAirTForHeatrFrntQf 0 "OkNotOk_NotOk" 1 "OkNotOk_Ok";
VAL_ 882 HwRowFrstPassFrntExtMotCtrl 0 "SwtVertSts1_Idle" 1 "SwtVertSts1_Up" 2 "SwtVertSts1_Dwn";
VAL_ 882 HwRowFrstPassFrntHeiMotCtrl 0 "SwtVertSts1_Idle" 1 "SwtVertSts1_Up" 2 "SwtVertSts1_Dwn";
VAL_ 882 HwRowFrstPassHeiMotCtrl 0 "SwtVertSts1_Idle" 1 "SwtVertSts1_Up" 2 "SwtVertSts1_Dwn";
VAL_ 882 HwRowFrstPassInclMotCtrl 0 "SwtHozlSts1_Idle" 1 "SwtHozlSts1_Fwd" 2 "SwtHozlSts1_Backw";
VAL_ 882 HwRowFrstPassSldMotCtrl 0 "SwtHozlSts1_Idle" 1 "SwtHozlSts1_Fwd" 2 "SwtHozlSts1_Backw";
VAL_ 882 IntrLiAmb1Trigger 0 "Boolean_FALSE" 1 "Boolean_TRUE";
VAL_ 882 IntrLiAmb1Update 0 "Boolean_FALSE" 1 "Boolean_TRUE";
VAL_ 882 IntrLiAmb2Trigger 0 "Boolean_FALSE" 1 "Boolean_TRUE";
VAL_ 882 IntrLiAmb2Update 0 "Boolean_FALSE" 1 "Boolean_TRUE";
VAL_ 882 WinHwSwtPassDoor 0 "WinPosnReq_Idle" 1 "WinPosnReq_UpMan" 2 "WinPosnReq_UpAut" 3 "WinPosnReq_DwnMan" 4 "WinPosnReq_DwnAut" 5 "WinPosnReq_NotDefd";
VAL_ 882 WinHwSwtPassReDoor 0 "WinPosnReq_Idle" 1 "WinPosnReq_UpMan" 2 "WinPosnReq_UpAut" 3 "WinPosnReq_DwnMan" 4 "WinPosnReq_DwnAut" 5 "WinPosnReq_NotDefd";
VAL_ 451 CCMHvahFltIndcn 0 "Flg1_Rst" 1 "Flg1_Set";
VAL_ 451 ClimaOvrHeatProActvSts 0 "OnOff1_Off" 1 "OnOff1_On";
VAL_ 451 DstTrvldVldFromVehCom 0 "InvldVld1_Invld" 1 "InvldVld1_Vld";
VAL_ 451 EcoClimaSts 0 "OnOff1_Off" 1 "OnOff1_On";
VAL_ 451 FltOfFrntTurnIndcrLe 0 "DevErrSts2_NoFlt" 1 "DevErrSts2_Flt";
VAL_ 451 FltOfFrntTurnIndcrRi 0 "DevErrSts2_NoFlt" 1 "DevErrSts2_Flt";
VAL_ 451 FltOfReTurnIndcrLe 0 "DevErrSts2_NoFlt" 1 "DevErrSts2_Flt";
VAL_ 451 FltOfReTurnIndcrRi 0 "DevErrSts2_NoFlt" 1 "DevErrSts2_Flt";
VAL_ 451 FuSnsrActvSideGenQF 0 "GenQf1_UndefindDataAccur" 1 "GenQf1_TmpUndefdData" 2 "GenQf1_DataAccurNotWithinSpcn" 3 "GenQf1_AccurData";
VAL_ 451 FuSnsrPasSideGenQF 0 "GenQf1_UndefindDataAccur" 1 "GenQf1_TmpUndefdData" 2 "GenQf1_DataAccurNotWithinSpcn" 3 "GenQf1_AccurData";
VAL_ 451 HvacFanLvlFbFrnt 0 "HmiHvacFanLvl_Off" 1 "HmiHvacFanLvl_LvlMan1" 2 "HmiHvacFanLvl_LvlMan2" 3 "HmiHvacFanLvl_LvlMan3" 4 "HmiHvacFanLvl_LvlMan4" 5 "HmiHvacFanLvl_LvlMan5" 6 "HmiHvacFanLvl_LvlMan6" 7 "HmiHvacFanLvl_LvlMan7" 8 "HmiHvacFanLvl_LvlMan8" 9 "HmiHvacFanLvl_LvlMan9" 10 "HmiHvacFanLvl_LvlAutMinusMinus" 11 "HmiHvacFanLvl_LvlAutMinus" 12 "HmiHvacFanLvl_LvlAutNorm" 13 "HmiHvacFanLvl_LvlAutPlus" 14 "HmiHvacFanLvl_LvlAutPlusPlus" 15 "HmiHvacFanLvl_Reserved";
VAL_ 451 HvacFanLvlFbRe 0 "HmiHvacFanLvl_Off" 1 "HmiHvacFanLvl_LvlMan1" 2 "HmiHvacFanLvl_LvlMan2" 3 "HmiHvacFanLvl_LvlMan3" 4 "HmiHvacFanLvl_LvlMan4" 5 "HmiHvacFanLvl_LvlMan5" 6 "HmiHvacFanLvl_LvlMan6" 7 "HmiHvacFanLvl_LvlMan7" 8 "HmiHvacFanLvl_LvlMan8" 9 "HmiHvacFanLvl_LvlMan9" 10 "HmiHvacFanLvl_LvlAutMinusMinus" 11 "HmiHvacFanLvl_LvlAutMinus" 12 "HmiHvacFanLvl_LvlAutNorm" 13 "HmiHvacFanLvl_LvlAutPlus" 14 "HmiHvacFanLvl_LvlAutPlusPlus" 15 "HmiHvacFanLvl_Reserved";
VAL_ 451 PassMassgRunng 0 "OnOff1_Off" 1 "OnOff1_On";
VAL_ 451 PassSeatActvSpplFct 0 "SeatActvSpplFct1_NotAvl" 1 "SeatActvSpplFct1_LumExtnAndLumHei" 2 "SeatActvSpplFct1_BackBlster" 3 "SeatActvSpplFct1_CushExtn" 4 "SeatActvSpplFct1_HdrestHeiAndHdrestTilt" 5 "SeatActvSpplFct1_MassgFct" 6 "SeatActvSpplFct1_ShoulderFct" 7 "SeatActvSpplFct1_LegrestFct";
VAL_ 451 PassSeatHeatgLvlSts 0 "SeatClimaLvl_Off" 1 "SeatClimaLvl_Lvl1" 2 "SeatClimaLvl_Lvl2" 3 "SeatClimaLvl_Lvl3";
VAL_ 451 PassSeatSwtSts2PassSeatSwtAdjmtOfSpplFctHozlSts 0 "SwtHozlSts1_Idle" 1 "SwtHozlSts1_Fwd" 2 "SwtHozlSts1_Backw";
VAL_ 451 PassSeatSwtSts2PassSeatSwtAdjmtOfSpplFctVerSts 0 "SwtVertSts1_Idle" 1 "SwtVertSts1_Up" 2 "SwtVertSts1_Dwn";
VAL_ 451 PassSeatSwtSts2PassSeatSwtHdrstHozlSts 0 "SwtHozlSts1_Idle" 1 "SwtHozlSts1_Fwd" 2 "SwtHozlSts1_Backw";
VAL_ 451 PassSeatSwtSts2PassSeatSwtHdrstVertSts 0 "SwtVertSts1_Idle" 1 "SwtVertSts1_Up" 2 "SwtVertSts1_Dwn";
VAL_ 451 PassSeatSwtSts2PassSeatSwtHeiFrntSts 0 "SwtVertSts1_Idle" 1 "SwtVertSts1_Up" 2 "SwtVertSts1_Dwn";
VAL_ 451 PassSeatSwtSts2PassSeatSwtHeiSts 0 "SwtVertSts1_Idle" 1 "SwtVertSts1_Up" 2 "SwtVertSts1_Dwn";
VAL_ 451 PassSeatSwtSts2PassSeatSwtInclSts 0 "SwtHozlSts1_Idle" 1 "SwtHozlSts1_Fwd" 2 "SwtHozlSts1_Backw";
VAL_ 451 PassSeatSwtSts2PassSeatSwtSelnOfSpplFctStsSts 0 "SwtVertSts1_Idle" 1 "SwtVertSts1_Up" 2 "SwtVertSts1_Dwn";
VAL_ 451 PassSeatSwtSts2PassSeatSwtSldSts 0 "SwtHozlSts1_Idle" 1 "SwtHozlSts1_Fwd" 2 "SwtHozlSts1_Backw";
VAL_ 451 PassSeatVentnLvlSts 0 "SeatClimaLvl_Off" 1 "SeatClimaLvl_Lvl1" 2 "SeatClimaLvl_Lvl2" 3 "SeatClimaLvl_Lvl3";
VAL_ 258 ClimaSts 0 "ClimaSts_Start" 1 "ClimaSts_Finish";
VAL_ 258 DoorPassHndlSts 0 "DoorHndlSts_Ukwn" 1 "DoorHndlSts_FullRtrctd" 2 "DoorHndlSts_MovgOut" 3 "DoorHndlSts_StopDurgDply" 4 "DoorHndlSts_FullDplyd" 5 "DoorHndlSts_MovgIn" 6 "DoorHndlSts_StopDurgRtrct" 7 "DoorHndlSts_Flt";
VAL_ 258 DoorPassReLockSts 0 "LockSts2_LockStsUkwn" 1 "LockSts2_Unlckd" 2 "LockSts2_Lockd" 3 "LockSts2_SafeLockd";
VAL_ 258 DoorRiReHndlSts 0 "DoorHndlSts_Ukwn" 1 "DoorHndlSts_FullRtrctd" 2 "DoorHndlSts_MovgOut" 3 "DoorHndlSts_StopDurgDply" 4 "DoorHndlSts_FullDplyd" 5 "DoorHndlSts_MovgIn" 6 "DoorHndlSts_StopDurgRtrct" 7 "DoorHndlSts_Flt";
VAL_ 258 EngRunngReqByClima 0 "EngRunngReq_Dft" 1 "EngRunngReq_StopInhb" 2 "EngRunngReq_RunReq" 3 "EngRunngReq_Resd";
VAL_ 258 HvacCoolgEnaFrnt 0 "OnOff1_Off" 1 "OnOff1_On";
VAL_ 258 SeatClimaDurgClimaHmiSeatHeatgForRowThrdLe 0 "SeatClimaLvl_Off" 1 "SeatClimaLvl_Lvl1" 2 "SeatClimaLvl_Lvl2" 3 "SeatClimaLvl_Lvl3";
VAL_ 258 SeatClimaDurgClimaHmiSeatHeatgForRowThrdRi 0 "SeatClimaLvl_Off" 1 "SeatClimaLvl_Lvl1" 2 "SeatClimaLvl_Lvl2" 3 "SeatClimaLvl_Lvl3";
VAL_ 258 SeatClimaDurgClimaHmiSeatVentnForRowThrdLe 0 "SeatClimaLvl_Off" 1 "SeatClimaLvl_Lvl1" 2 "SeatClimaLvl_Lvl2" 3 "SeatClimaLvl_Lvl3";
VAL_ 258 SeatClimaDurgClimaHmiSeatVentnForRowThrdRi 0 "SeatClimaLvl_Off" 1 "SeatClimaLvl_Lvl1" 2 "SeatClimaLvl_Lvl2" 3 "SeatClimaLvl_Lvl3";
VAL_ 455 ClimaOffReq 0 "ClimaOffReq_NoReq" 1 "ClimaOffReq_SecRowOffReq" 2 "ClimaOffReq_TrdRowOffReq" 3 "ClimaOffReq_ClimaOff";
VAL_ 455 ClimaOvrHeatProRspn 0 "OnOff1_Off" 1 "OnOff1_On";
VAL_ 455 ClimaOvrHeatProWarn 0 "ClimaOvrheatProWarnSts_NoWarn" 1 "ClimaOvrheatProWarnSts_Err" 2 "ClimaOvrheatProWarnSts_PwrLo" 3 "ClimaOvrheatProWarnSts_Tout";
VAL_ 455 DiDblLock 0 "EnableDisableCoding_Disabled" 1 "EnableDisableCoding_Enabled";
VAL_ 455 RemClimaDelaySts 0 "OnOff1_Off" 1 "OnOff1_On";
VAL_ 455 RemClimaExtnTiRspn 0 "OnOff1_Off" 1 "OnOff1_On";
VAL_ 455 RemClimaHvRspn 0 "OnOff1_Off" 1 "OnOff1_On";
VAL_ 455 RemClimaWarn 0 "ClimaWarn_NoWarn" 1 "ClimaWarn_FuLo" 2 "ClimaWarn_BattLo" 3 "ClimaWarn_FuAndBattLo" 4 "ClimaWarn_TLo" 5 "ClimaWarn_THi" 6 "ClimaWarn_Error" 7 "ClimaWarn_HVError" 8 "ClimaWarn_ActvnLimd";
VAL_ 455 RemStrtClimaRspn 0 "OnOff1_Off" 1 "OnOff1_On";
VAL_ 455 RoofOpnReqFrmClima 0 "OnOff1_Off" 1 "OnOff1_On";
VAL_ 455 SchedCmptHeatCoolFB 0 "SchedCmptHeatCoolFB_NoReq" 1 "SchedCmptHeatCoolFB_ON" 2 "SchedCmptHeatCoolFB_OFF" 3 "SchedCmptHeatCoolFB_Reserved";
VAL_ 455 WinAndRoofReqFrmClima 0 "WinOpenClsGlbReqFromTelm_Idle" 1 "WinOpenClsGlbReqFromTelm_Open" 2 "WinOpenClsGlbReqFromTelm_Close";
VAL_ 1350 VFCVectorZCUPVFCid0 0 "VFCOnOff_Off" 1 "VFCOnOff_On";
VAL_ 1350 VFCVectorZCUPVFCid1 0 "VFCOnOff_Off" 1 "VFCOnOff_On";
VAL_ 1350 VFCVectorZCUPVFCid10 0 "VFCOnOff_Off" 1 "VFCOnOff_On";
VAL_ 1350 VFCVectorZCUPVFCid11 0 "VFCOnOff_Off" 1 "VFCOnOff_On";
VAL_ 1350 VFCVectorZCUPVFCid12 0 "VFCOnOff_Off" 1 "VFCOnOff_On";
VAL_ 1350 VFCVectorZCUPVFCid13 0 "VFCOnOff_Off" 1 "VFCOnOff_On";
VAL_ 1350 VFCVectorZCUPVFCid14 0 "VFCOnOff_Off" 1 "VFCOnOff_On";
VAL_ 1350 VFCVectorZCUPVFCid15 0 "VFCOnOff_Off" 1 "VFCOnOff_On";
VAL_ 1350 VFCVectorZCUPVFCid16 0 "VFCOnOff_Off" 1 "VFCOnOff_On";
VAL_ 1350 VFCVectorZCUPVFCid17 0 "VFCOnOff_Off" 1 "VFCOnOff_On";
VAL_ 1350 VFCVectorZCUPVFCid18 0 "VFCOnOff_Off" 1 "VFCOnOff_On";
VAL_ 1350 VFCVectorZCUPVFCid19 0 "VFCOnOff_Off" 1 "VFCOnOff_On";
VAL_ 1350 VFCVectorZCUPVFCid2 0 "VFCOnOff_Off" 1 "VFCOnOff_On";
VAL_ 1350 VFCVectorZCUPVFCid20 0 "VFCOnOff_Off" 1 "VFCOnOff_On";
VAL_ 1350 VFCVectorZCUPVFCid21 0 "VFCOnOff_Off" 1 "VFCOnOff_On";
VAL_ 1350 VFCVectorZCUPVFCid22 0 "VFCOnOff_Off" 1 "VFCOnOff_On";
VAL_ 1350 VFCVectorZCUPVFCid23 0 "VFCOnOff_Off" 1 "VFCOnOff_On";
VAL_ 1350 VFCVectorZCUPVFCid24 0 "VFCOnOff_Off" 1 "VFCOnOff_On";
VAL_ 1350 VFCVectorZCUPVFCid25 0 "VFCOnOff_Off" 1 "VFCOnOff_On";
VAL_ 1350 VFCVectorZCUPVFCid26 0 "VFCOnOff_Off" 1 "VFCOnOff_On";
VAL_ 1350 VFCVectorZCUPVFCid27 0 "VFCOnOff_Off" 1 "VFCOnOff_On";
VAL_ 1350 VFCVectorZCUPVFCid28 0 "VFCOnOff_Off" 1 "VFCOnOff_On";
VAL_ 1350 VFCVectorZCUPVFCid29 0 "VFCOnOff_Off" 1 "VFCOnOff_On";
VAL_ 1350 VFCVectorZCUPVFCid3 0 "VFCOnOff_Off" 1 "VFCOnOff_On";
VAL_ 1350 VFCVectorZCUPVFCid30 0 "VFCOnOff_Off" 1 "VFCOnOff_On";
VAL_ 1350 VFCVectorZCUPVFCid31 0 "VFCOnOff_Off" 1 "VFCOnOff_On";
VAL_ 1350 VFCVectorZCUPVFCid32 0 "VFCOnOff_Off" 1 "VFCOnOff_On";
VAL_ 1350 VFCVectorZCUPVFCid33 0 "VFCOnOff_Off" 1 "VFCOnOff_On";
VAL_ 1350 VFCVectorZCUPVFCid34 0 "VFCOnOff_Off" 1 "VFCOnOff_On";
VAL_ 1350 VFCVectorZCUPVFCid35 0 "VFCOnOff_Off" 1 "VFCOnOff_On";
VAL_ 1350 VFCVectorZCUPVFCid36 0 "VFCOnOff_Off" 1 "VFCOnOff_On";
VAL_ 1350 VFCVectorZCUPVFCid37 0 "VFCOnOff_Off" 1 "VFCOnOff_On";
VAL_ 1350 VFCVectorZCUPVFCid38 0 "VFCOnOff_Off" 1 "VFCOnOff_On";
VAL_ 1350 VFCVectorZCUPVFCid39 0 "VFCOnOff_Off" 1 "VFCOnOff_On";
VAL_ 1350 VFCVectorZCUPVFCid4 0 "VFCOnOff_Off" 1 "VFCOnOff_On";
VAL_ 1350 VFCVectorZCUPVFCid40 0 "VFCOnOff_Off" 1 "VFCOnOff_On";
VAL_ 1350 VFCVectorZCUPVFCid41 0 "VFCOnOff_Off" 1 "VFCOnOff_On";
VAL_ 1350 VFCVectorZCUPVFCid42 0 "VFCOnOff_Off" 1 "VFCOnOff_On";
VAL_ 1350 VFCVectorZCUPVFCid43 0 "VFCOnOff_Off" 1 "VFCOnOff_On";
VAL_ 1350 VFCVectorZCUPVFCid44 0 "VFCOnOff_Off" 1 "VFCOnOff_On";
VAL_ 1350 VFCVectorZCUPVFCid45 0 "VFCOnOff_Off" 1 "VFCOnOff_On";
VAL_ 1350 VFCVectorZCUPVFCid46 0 "VFCOnOff_Off" 1 "VFCOnOff_On";
VAL_ 1350 VFCVectorZCUPVFCid47 0 "VFCOnOff_Off" 1 "VFCOnOff_On";
VAL_ 1350 VFCVectorZCUPVFCid48 0 "VFCOnOff_Off" 1 "VFCOnOff_On";
VAL_ 1350 VFCVectorZCUPVFCid49 0 "VFCOnOff_Off" 1 "VFCOnOff_On";
VAL_ 1350 VFCVectorZCUPVFCid5 0 "VFCOnOff_Off" 1 "VFCOnOff_On";
VAL_ 1350 VFCVectorZCUPVFCid50 0 "VFCOnOff_Off" 1 "VFCOnOff_On";
VAL_ 1350 VFCVectorZCUPVFCid51 0 "VFCOnOff_Off" 1 "VFCOnOff_On";
VAL_ 1350 VFCVectorZCUPVFCid52 0 "VFCOnOff_Off" 1 "VFCOnOff_On";
VAL_ 1350 VFCVectorZCUPVFCid53 0 "VFCOnOff_Off" 1 "VFCOnOff_On";
VAL_ 1350 VFCVectorZCUPVFCid54 0 "VFCOnOff_Off" 1 "VFCOnOff_On";
VAL_ 1350 VFCVectorZCUPVFCid55 0 "VFCOnOff_Off" 1 "VFCOnOff_On";
VAL_ 1350 VFCVectorZCUPVFCid56 0 "VFCOnOff_Off" 1 "VFCOnOff_On";
VAL_ 1350 VFCVectorZCUPVFCid57 0 "VFCOnOff_Off" 1 "VFCOnOff_On";
VAL_ 1350 VFCVectorZCUPVFCid58 0 "VFCOnOff_Off" 1 "VFCOnOff_On";
VAL_ 1350 VFCVectorZCUPVFCid59 0 "VFCOnOff_Off" 1 "VFCOnOff_On";
VAL_ 1350 VFCVectorZCUPVFCid6 0 "VFCOnOff_Off" 1 "VFCOnOff_On";
VAL_ 1350 VFCVectorZCUPVFCid60 0 "VFCOnOff_Off" 1 "VFCOnOff_On";
VAL_ 1350 VFCVectorZCUPVFCid61 0 "VFCOnOff_Off" 1 "VFCOnOff_On";
VAL_ 1350 VFCVectorZCUPVFCid7 0 "VFCOnOff_Off" 1 "VFCOnOff_On";
VAL_ 1350 VFCVectorZCUPVFCid8 0 "VFCOnOff_Off" 1 "VFCOnOff_On";
VAL_ 1350 VFCVectorZCUPVFCid9 0 "VFCOnOff_Off" 1 "VFCOnOff_On";
VAL_ 1286 WakeUpReasonsforZCUP 0 "WakeupReasons_667949" 1 "WakeupReasons_667950" 2 "WakeupReasons_169654" 3 "WakeupReasons_667951" 4 "WakeupReasons_168965" 5 "WakeupReasons_197643" 6 "WakeupReasons_264933" 7 "WakeupReasons_45654" 8 "WakeupReasons_22058" 9 "WakeupReasons_49446" 10 "WakeupReasons_22060" 11 "WakeupReasons_269740" 12 "WakeupReasons_269735" 13 "WakeupReasons_269739" 14 "WakeupReasons_658500" 15 "WakeupReasons_21901" 16 "WakeupReasons_45793" 17 "WakeupReasons_45794" 18 "WakeupReasons_22005" 19 "WakeupReasons_22013" 20 "WakeupReasons_22100" 21 "WakeupReasons_45659" 22 "WakeupReasons_45657" 23 "WakeupReasons_140084" 24 "WakeupReasons_21973" 25 "WakeupReasons_91253" 26 "WakeupReasons_88123" 27 "WakeupReasons_88125" 28 "WakeupReasons_321583" 29 "WakeupReasons_74188" 30 "WakeupReasons_667945" 31 "WakeupReasons_169655" 32 "WakeupReasons_667948" 33 "WakeupReasons_168966" 34 "WakeupReasons_170865" 35 "WakeupReasons_197642" 36 "WakeupReasons_264876" 37 "WakeupReasons_191050" 38 "WakeupReasons_182033" 39 "WakeupReasons_200937" 40 "WakeupReasons_170807" 41 "WakeupReasons_319139" 42 "WakeupReasons_100298" 43 "WakeupReasons_100275" 44 "WakeupReasons_100300" 45 "WakeupReasons_100278" 46 "WakeupReasons_100281" 47 "WakeupReasons_265333" 48 "WakeupReasons_108776" 49 "WakeupReasons_176921" 50 "WakeupReasons_197826" 51 "WakeupReasons_185670" 52 "WakeupReasons_161066" 53 "WakeupReasons_200156" 54 "WakeupReasons_225696" 55 "WakeupReasons_21997" 56 "WakeupReasons_45656" 57 "WakeupReasons_266860" 58 "WakeupReasons_169894" 59 "WakeupReasons_320282" 60 "WakeupReasons_319422" 61 "WakeupReasons_320277" 62 "WakeupReasons_355601" 63 "WakeupReasons_360904" 64 "WakeupReasons_361505" 65 "WakeupReasons_361509" 66 "WakeupReasons_645094" 67 "WakeupReasons_68676" 68 "WakeupReasons_360008" 69 "WakeupReasons_109382" 70 "WakeupReasons_119273" 71 "WakeupReasons_224065" 72 "WakeupReasons_68644" 73 "WakeupReasons_109364" 74 "WakeupReasons_68481" 75 "WakeupReasons_224061" 76 "WakeupReasons_360006" 77 "WakeupReasons_138997" 78 "WakeupReasons_634696" 79 "WakeupReasons_645810" 80 "WakeupReasons_297868" 81 "WakeupReasons_315364" 82 "WakeupReasons_109367" 83 "WakeupReasons_320126" 84 "WakeupReasons_109387" 85 "WakeupReasons_634710" 86 "WakeupReasons_338820" 87 "WakeupReasons_67182" 88 "WakeupReasons_152237" 89 "WakeupReasons_145707" 90 "WakeupReasons_199172" 91 "WakeupReasons_144897" 92 "WakeupReasons_186489" 93 "WakeupReasons_144970" 94 "WakeupReasons_152786" 95 "WakeupReasons_264932" 96 "WakeupReasons_264934" 97 "WakeupReasons_356190" 98 "WakeupReasons_145688" 99 "WakeupReasons_95444" 100 "WakeupReasons_169945" 101 "WakeupReasons_140678" 102 "WakeupReasons_222553" 103 "WakeupReasons_224831" 104 "WakeupReasons_201815" 105 "WakeupReasons_45864" 106 "WakeupReasons_659549" 107 "WakeupReasons_45866" 108 "WakeupReasons_45867" 109 "WakeupReasons_169884" 110 "WakeupReasons_264962" 111 "WakeupReasons_201348" 112 "WakeupReasons_320287" 113 "WakeupReasons_156412" 114 "WakeupReasons_133749" 115 "WakeupReasons_355409" 116 "WakeupReasons_636692" 117 "WakeupReasons_533044" 118 "WakeupReasons_106774" 119 "WakeupReasons_145311" 120 "WakeupReasons_145319" 121 "WakeupReasons_152774" 122 "WakeupReasons_145330" 123 "WakeupReasons_145388" 124 "WakeupReasons_145399" 125 "WakeupReasons_145362" 126 "WakeupReasons_145385" 127 "WakeupReasons_145373" 128 "WakeupReasons_145288" 129 "WakeupReasons_145419" 130 "WakeupReasons_145454" 131 "WakeupReasons_145462" 132 "WakeupReasons_269156" 133 "WakeupReasons_300427" 134 "WakeupReasons_220322" 135 "WakeupReasons_224617" 136 "WakeupReasons_224634" 137 "WakeupReasons_300682" 138 "WakeupReasons_264958" 139 "WakeupReasons_160597" 140 "WakeupReasons_160602" 141 "WakeupReasons_108841" 142 "WakeupReasons_265569" 143 "WakeupReasons_526429" 144 "WakeupReasons_514545" 145 "WakeupReasons_265232" 146 "WakeupReasons_644550" 147 "WakeupReasons_317616" 148 "WakeupReasons_354791" 149 "WakeupReasons_320631" 150 "WakeupReasons_337565" 151 "WakeupReasons_532007" 152 "WakeupReasons_514503" 153 "WakeupReasons_299117" 154 "WakeupReasons_340667" 155 "WakeupReasons_321845" 156 "WakeupReasons_179103" 157 "WakeupReasons_108810" 158 "WakeupReasons_322857" 159 "WakeupReasons_658603" 160 "WakeupReasons_197648" 161 "WakeupReasons_160596" 162 "WakeupReasons_361272" 163 "WakeupReasons_361279" 164 "WakeupReasons_265305" 165 "WakeupReasons_265328" 166 "WakeupReasons_265330" 167 "WakeupReasons_298808" 168 "WakeupReasons_515804" 169 "WakeupReasons_514502" 170 "WakeupReasons_645753" 171 "WakeupReasons_646109" 172 "WakeupReasons_299547" 173 "WakeupReasons_318342" 174 "WakeupReasons_360543" 175 "WakeupReasons_356549" 176 "WakeupReasons_198484" 177 "WakeupReasons_300681" 178 "WakeupReasons_359211" 179 "WakeupReasons_534077" 180 "WakeupReasons_525705" 181 "WakeupReasons_360299" 182 "WakeupReasons_526445" 183 "WakeupReasons_534145" 184 "WakeupReasons_192030" 185 "WakeupReasons_652361" 186 "WakeupReasons_355214" 187 "WakeupReasons_321317" 188 "WakeupReasons_359187" 189 "WakeupReasons_321057" 190 "WakeupReasons_321319" 191 "WakeupReasons_321323" 192 "WakeupReasons_321077" 193 "WakeupReasons_320895" 194 "WakeupReasons_655340" 195 "WakeupReasons_636556" 196 "WakeupReasons_108834" 197 "WakeupReasons_265937" 198 "WakeupReasons_533050" 199 "WakeupReasons_526426" 200 "WakeupReasons_264712" 201 "WakeupReasons_319401" 202 "WakeupReasons_643973" 203 "WakeupReasons_223715" 204 "WakeupReasons_199159" 205 "WakeupReasons_318382" 206 "WakeupReasons_226967" 207 "WakeupReasons_531743" 208 "WakeupReasons_360542" 209 "WakeupReasons_264726" 210 "WakeupReasons_535214" 211 "WakeupReasons_335068" 212 "WakeupReasons_316796" 213 "WakeupReasons_526438" 214 "WakeupReasons_198433" 215 "WakeupReasons_225961" 216 "WakeupReasons_197665" 217 "WakeupReasons_224550" 218 "WakeupReasons_667962" 219 "WakeupReasons_667953" 220 "WakeupReasons_110885" 221 "WakeupReasons_224552" 222 "WakeupReasons_224553" 223 "WakeupReasons_652546" 224 "WakeupReasons_331194" 225 "WakeupReasons_667820" 226 "WakeupReasons_659350" 227 "WakeupReasons_101706" 228 "WakeupReasons_101725" 229 "WakeupReasons_101728" 230 "WakeupReasons_101727" 231 "WakeupReasons_166267" 232 "WakeupReasons_156440" 233 "WakeupReasons_95949" 234 "WakeupReasons_112799" 235 "WakeupReasons_146470" 236 "WakeupReasons_176748" 237 "WakeupReasons_223920" 238 "WakeupReasons_668531" 239 "WakeupReasons_670087" 240 "WakeupReasons_668529" 241 "WakeupReasons_45858" 242 "WakeupReasons_315981" 243 "WakeupReasons_533370" 244 "WakeupReasons_533371" 245 "WakeupReasons_533372" 246 "WakeupReasons_241902" 247 "WakeupReasons_359559" 248 "WakeupReasons_516327" 249 "WakeupReasons_533872" 250 "WakeupReasons_45856" 251 "WakeupReasons_45853" 252 "WakeupReasons_45854" 253 "WakeupReasons_45852" 254 "WakeupReasons_45851" 255 "WakeupReasons_45850" 256 "WakeupReasons_45849" 257 "WakeupReasons_636801" 258 "WakeupReasons_109466" 259 "WakeupReasons_109467" 260 "WakeupReasons_670345" 261 "WakeupReasons_NMPDUReceived" 262 "WakeupReasons_358832" 263 "WakeupReasons_200683" 264 "WakeupReasons_198452" 265 "WakeupReasons_185457" 266 "WakeupReasons_185490" 267 "WakeupReasons_4471" 268 "WakeupReasons_269034" 269 "WakeupReasons_215560" 270 "WakeupReasons_312881" 271 "WakeupReasons_269140" 272 "WakeupReasons_197653" 273 "WakeupReasons_337991" 274 "WakeupReasons_658188" 275 "WakeupReasons_674953" 276 "WakeupReasons_675064" 277 "WakeupReasons_674958" 278 "WakeupReasons_675494" 279 "WakeupReasons_675837" 280 "WakeupReasons_667879" 281 "WakeupReasons_667947" 282 "WakeupReasons_676265" 283 "WakeupReasons_669465" 284 "WakeupReasons_670928" 285 "WakeupReasons_669447" 286 "WakeupReasons_667922" 287 "WakeupReasons_670753" 288 "WakeupReasons_668395" 289 "WakeupReasons_668393" 290 "WakeupReasons_667850" 291 "WakeupReasons_667848" 292 "WakeupReasons_311279" 293 "WakeupReasons_182918" 294 "WakeupReasons_667988" 295 "WakeupReasons_532555" 296 "WakeupReasons_532556" 297 "WakeupReasons_113348" 298 "WakeupReasons_193474" 299 "WakeupReasons_667871" 300 "WakeupReasons_670966" 301 "WakeupReasons_667985" 302 "WakeupReasons_670354" 303 "WakeupReasons_46017" 304 "WakeupReasons_675742" 305 "WakeupReasons_106669" 306 "WakeupReasons_80609" 307 "WakeupReasons_199714" 308 "WakeupReasons_200090" 309 "WakeupReasons_139075" 310 "WakeupReasons_268983" 311 "WakeupReasons_265131" 312 "WakeupReasons_263473" 313 "WakeupReasons_45887" 314 "WakeupReasons_69678" 315 "WakeupReasons_69679" 316 "WakeupReasons_45897" 317 "WakeupReasons_45898" 318 "WakeupReasons_80608" 319 "WakeupReasons_45869" 320 "WakeupReasons_45870" 321 "WakeupReasons_45872" 322 "WakeupReasons_45875" 323 "WakeupReasons_45871" 324 "WakeupReasons_45876" 325 "WakeupReasons_667980" 326 "WakeupReasons_45877" 327 "WakeupReasons_667973" 328 "WakeupReasons_670962" 329 "WakeupReasons_45888" 330 "WakeupReasons_45890" 331 "WakeupReasons_667869" 332 "WakeupReasons_45846" 333 "WakeupReasons_45847" 334 "WakeupReasons_45848" 335 "WakeupReasons_262872" 336 "WakeupReasons_127924" 337 "WakeupReasons_127926" 338 "WakeupReasons_674223" 339 "WakeupReasons_667982" 340 "WakeupReasons_657121" 341 "WakeupReasons_265745" 342 "WakeupReasons_657120" 343 "WakeupReasons_675564" 344 "WakeupReasons_197644" 345 "WakeupReasons_264943" 346 "WakeupReasons_264697" 347 "WakeupReasons_69216" 348 "WakeupReasons_128671" 349 "WakeupReasons_356598" 350 "WakeupReasons_675745" 351 "WakeupReasons_667983" 352 "WakeupReasons_667987" 353 "WakeupReasons_75103" 354 "WakeupReasons_305818" 355 "WakeupReasons_670942" 356 "WakeupReasons_532932" 357 "WakeupReasons_532933" 358 "WakeupReasons_83199" 359 "WakeupReasons_45900" 360 "WakeupReasons_88458" 361 "WakeupReasons_329457" 362 "WakeupReasons_45902" 363 "WakeupReasons_224211" 364 "WakeupReasons_667981" 365 "WakeupReasons_667874" 366 "WakeupReasons_46020" 367 "WakeupReasons_667842" 368 "WakeupReasons_145161" 369 "WakeupReasons_233755" 370 "WakeupReasons_297056" 371 "WakeupReasons_264691" 372 "WakeupReasons_262871" 373 "WakeupReasons_264964" 374 "WakeupReasons_667872" 375 "WakeupReasons_45655" 376 "WakeupReasons_177214" 377 "WakeupReasons_671005" 378 "WakeupReasons_680712" 379 "WakeupReasons_669822" 380 "WakeupReasons_668523" 381 "WakeupReasons_680974" 382 "WakeupReasons_680975" 383 "WakeupReasons_681028" 384 "WakeupReasons_670462" 385 "WakeupReasons_681134" 386 "WakeupReasons_681031" 387 "WakeupReasons_681711" 388 "WakeupReasons_682034" 389 "WakeupReasons_674839" 390 "WakeupReasons_681915" 391 "WakeupReasons_682032" 392 "WakeupReasons_682037" 393 "WakeupReasons_682688" 394 "WakeupReasons_681789" 395 "WakeupReasons_682023" 396 "WakeupReasons_681023" 397 "WakeupReasons_676285" 398 "WakeupReasons_682077" 399 "WakeupReasons_682076" 400 "WakeupReasons_682078" 401 "WakeupReasons_682153" 402 "WakeupReasons_682155" 403 "WakeupReasons_682152" 404 "WakeupReasons_682154" 405 "WakeupReasons_682074";
SIG_GROUP_ 801 AmbTEstimd 1 : AmbTEstimdAmbTEstimd AmbTEstimdQf;
SIG_GROUP_ 520 AmbTRawAtPassSide 1 : AmbTRawAtPassSideAmbTVal AmbTRawAtPassSideQly;
SIG_GROUP_ 51 BodyDataTraceZCUP1 1 : BodyDataTraceZCUP1Functiondevpsignalgroup1 BodyDataTraceZCUP1Functiondevpsignalgroup2 BodyDataTraceZCUP1Functiondevpsignalgroup3 BodyDataTraceZCUP1Functiondevpsignalgroup4 BodyDataTraceZCUP1Functiondevpsignalgroup5 BodyDataTraceZCUP1Functiondevpsignalgroup6 BodyDataTraceZCUP1Functiondevpsignalgroup7 BodyDataTraceZCUP1Functiondevpsignalgroup8;
SIG_GROUP_ 51 BodyDataTraceZCUP2 1 : BodyDataTraceZCUP2Functiondevpsignalgroup1 BodyDataTraceZCUP2Functiondevpsignalgroup2 BodyDataTraceZCUP2Functiondevpsignalgroup3 BodyDataTraceZCUP2Functiondevpsignalgroup4 BodyDataTraceZCUP2Functiondevpsignalgroup5 BodyDataTraceZCUP2Functiondevpsignalgroup6 BodyDataTraceZCUP2Functiondevpsignalgroup7 BodyDataTraceZCUP2Functiondevpsignalgroup8;
SIG_GROUP_ 51 BodyDataTraceZCUP3 1 : BodyDataTraceZCUP3Functiondevpsignalgroup1 BodyDataTraceZCUP3Functiondevpsignalgroup2 BodyDataTraceZCUP3Functiondevpsignalgroup3 BodyDataTraceZCUP3Functiondevpsignalgroup4 BodyDataTraceZCUP3Functiondevpsignalgroup5 BodyDataTraceZCUP3Functiondevpsignalgroup6 BodyDataTraceZCUP3Functiondevpsignalgroup7 BodyDataTraceZCUP3Functiondevpsignalgroup8;
SIG_GROUP_ 51 BodyDataTraceZCUP4 1 : BodyDataTraceZCUP4Functiondevpsignalgroup1 BodyDataTraceZCUP4Functiondevpsignalgroup2 BodyDataTraceZCUP4Functiondevpsignalgroup3 BodyDataTraceZCUP4Functiondevpsignalgroup4 BodyDataTraceZCUP4Functiondevpsignalgroup5 BodyDataTraceZCUP4Functiondevpsignalgroup6 BodyDataTraceZCUP4Functiondevpsignalgroup7 BodyDataTraceZCUP4Functiondevpsignalgroup8;
SIG_GROUP_ 51 BodyDataTraceZCUP5 1 : BodyDataTraceZCUP5Functiondevpsignalgroup1 BodyDataTraceZCUP5Functiondevpsignalgroup2 BodyDataTraceZCUP5Functiondevpsignalgroup3 BodyDataTraceZCUP5Functiondevpsignalgroup4 BodyDataTraceZCUP5Functiondevpsignalgroup5 BodyDataTraceZCUP5Functiondevpsignalgroup6 BodyDataTraceZCUP5Functiondevpsignalgroup7 BodyDataTraceZCUP5Functiondevpsignalgroup8;
SIG_GROUP_ 51 BodyDataTraceZCUP6 1 : BodyDataTraceZCUP6Functiondevpsignalgroup1 BodyDataTraceZCUP6Functiondevpsignalgroup2 BodyDataTraceZCUP6Functiondevpsignalgroup3 BodyDataTraceZCUP6Functiondevpsignalgroup4 BodyDataTraceZCUP6Functiondevpsignalgroup5 BodyDataTraceZCUP6Functiondevpsignalgroup6 BodyDataTraceZCUP6Functiondevpsignalgroup7 BodyDataTraceZCUP6Functiondevpsignalgroup8;
SIG_GROUP_ 51 BodyDataTraceZCUP7 1 : BodyDataTraceZCUP7Functiondevpsignalgroup1 BodyDataTraceZCUP7Functiondevpsignalgroup2 BodyDataTraceZCUP7Functiondevpsignalgroup3 BodyDataTraceZCUP7Functiondevpsignalgroup4 BodyDataTraceZCUP7Functiondevpsignalgroup5 BodyDataTraceZCUP7Functiondevpsignalgroup6 BodyDataTraceZCUP7Functiondevpsignalgroup7 BodyDataTraceZCUP7Functiondevpsignalgroup8;
SIG_GROUP_ 643 CmptmtAirDistbnRsp 1 : CmptmtAirDistbnRspAirDistbnDrvr CmptmtAirDistbnRspAirDistbnPass CmptmtAirDistbnRspAirDistbnSecLe CmptmtAirDistbnRspAirDistbnSecRi CmptmtAirDistbnRspAirDistbnThrd;
SIG_GROUP_ 801 CmptmtAirTEstimdExtd 1 : CmptmtAirTEstimdExtdComptmtT CmptmtAirTEstimdExtdQlyFlg;
SIG_GROUP_ 1184 CmptmtIntrMtrlTEstimd 1 : CmptmtIntrMtrlTEstimdMtrlSnsrT CmptmtIntrMtrlTEstimdMtrlSnsrTQly2;
SIG_GROUP_ 310 CmptmtTFrnt 1 : CmptmtTFrntCmptmtTFrnt CmptmtTFrntFanForCmptmtTRunng CmptmtTFrntQf;
SIG_GROUP_ 803 CmptmtTRe 1 : CmptmtTReCmptmtTFrnt CmptmtTReCmptmtTFrntQf CmptmtTReFanForCmptmtTRunng;
SIG_GROUP_ 643 DoorPassCinhIntFailInf 1 : DoorPassCinhIntFailInfCinchFlt1 DoorPassCinhIntFailInfCinchRestFlt;
SIG_GROUP_ 58 DoorPassReCinhIntFailInf 1 : DoorPassReCinhIntFailInfCinchFlt1 DoorPassReCinhIntFailInfCinchRestFlt;
SIG_GROUP_ 643 DoorPassRelsFail 1 : DoorPassRelsFailCinchOverTimed DoorPassRelsFailFailure1 DoorPassRelsFailMechRels;
SIG_GROUP_ 58 DoorPassReRelsFail 1 : DoorPassReRelsFailCinchOverTimed DoorPassReRelsFailFailure1 DoorPassReRelsFailMechRels;
SIG_GROUP_ 643 DoorRiReCinhIntFailInf 1 : DoorRiReCinhIntFailInfCinchFlt1 DoorRiReCinhIntFailInfCinchRestFlt;
SIG_GROUP_ 643 DoorRiReRelsFail 1 : DoorRiReRelsFailCinchOverTimed DoorRiReRelsFailFailure1 DoorRiReRelsFailMechRels;
SIG_GROUP_ 803 DvlpFrameForCCM 1 : DvlpFrameForCCMByte0 DvlpFrameForCCMByte1 DvlpFrameForCCMByte2 DvlpFrameForCCMByte3 DvlpFrameForCCMByte4 DvlpFrameForCCMByte5 DvlpFrameForCCMByte6 DvlpFrameForCCMByte7;
SIG_GROUP_ 600 ElecDefrstReq 1 : ElecDefrstReqMirrDefrstReq ElecDefrstReqWinDefrstFrntReq ElecDefrstReqWinDefrstReReq;
SIG_GROUP_ 310 EvaprTFrnt 1 : EvaprTFrntEvaprTFrnt EvaprTFrntEvaprTQf;
SIG_GROUP_ 600 EvaprTRe 1 : EvaprTReEvaprTFrnt EvaprTReEvaprTQf;
SIG_GROUP_ 451 FuSnsrActvSide 1 : FuSnsrActvSideFuLvlSnsrRawVal FuSnsrActvSideGenQF;
SIG_GROUP_ 451 FuSnsrPasSide 1 : FuSnsrPasSideFuLvlSnsrRawVal FuSnsrPasSideGenQF;
SIG_GROUP_ 643 HvacAirTForMaxTZone 1 : HvacAirTForMaxTZoneEvaprTFrnt HvacAirTForMaxTZoneEvaprTQf;
SIG_GROUP_ 803 HvacAirTForRowFirstAtFlrLe 1 : HvacAirTForRowFirstAtFlrLeEvaprTFrnt HvacAirTForRowFirstAtFlrLeEvaprTQf;
SIG_GROUP_ 803 HvacAirTForRowFirstAtFlrRi 1 : HvacAirTForRowFirstAtFlrRiEvaprTFrnt HvacAirTForRowFirstAtFlrRiEvaprTQf;
SIG_GROUP_ 803 HvacAirTForRowFirstAtVentLe 1 : HvacAirTForRowFirstAtVentLeEvaprTFrnt HvacAirTForRowFirstAtVentLeEvaprTQf;
SIG_GROUP_ 803 HvacAirTForRowFirstAtVentRi 1 : HvacAirTForRowFirstAtVentRiEvaprTFrnt HvacAirTForRowFirstAtVentRiEvaprTQf;
SIG_GROUP_ 803 HvacAirTForRowSecAtFlrLe 1 : HvacAirTForRowSecAtFlrLeEvaprTFrnt HvacAirTForRowSecAtFlrLeEvaprTQf;
SIG_GROUP_ 803 HvacAirTForRowSecAtFlrRi 1 : HvacAirTForRowSecAtFlrRiEvaprTFrnt HvacAirTForRowSecAtFlrRiEvaprTQf;
SIG_GROUP_ 803 HvacAirTForRowSecAtVentLe 1 : HvacAirTForRowSecAtVentLeEvaprTFrnt HvacAirTForRowSecAtVentLeEvaprTQf;
SIG_GROUP_ 803 HvacAirTForRowSecAtVentRi 1 : HvacAirTForRowSecAtVentRiEvaprTFrnt HvacAirTForRowSecAtVentRiEvaprTQf;
SIG_GROUP_ 803 HvacAirTForRowThrdAtFlrRi 1 : HvacAirTForRowThrdAtFlrRiEvaprTFrnt HvacAirTForRowThrdAtFlrRiEvaprTQf;
SIG_GROUP_ 803 HvacAirTForRowThrdAtVentRi 1 : HvacAirTForRowThrdAtVentRiEvaprTFrnt HvacAirTForRowThrdAtVentRiEvaprTQf;
SIG_GROUP_ 803 HvacCondsorT 1 : HvacCondsorTEvaprTFrnt HvacCondsorTEvaprTQf;
SIG_GROUP_ 803 HvacCondsorTsp 1 : HvacCondsorTspEvaprTFrnt HvacCondsorTspEvaprTQf;
SIG_GROUP_ 803 HvacHeatrInletTempReq 1 : HvacHeatrInletTempReqEvaprTFrnt HvacHeatrInletTempReqEvaprTQf;
SIG_GROUP_ 882 HvacHexAirT 1 : HvacHexAirTHvacAirTForHeatrFrnt HvacHexAirTHvacAirTForHeatrFrntQf;
SIG_GROUP_ 310 HvahAirTEstmd 1 : HvahAirTEstmdEvaprTFrnt HvahAirTEstmdEvaprTQf;
SIG_GROUP_ 882 IntrLiAmb1 1 : IntrLiAmb1BnIngrd IntrLiAmb1GrnIngrd IntrLiAmb1Intensty IntrLiAmb1RedIngrd IntrLiAmb1SelCmd1 IntrLiAmb1SelCmd2 IntrLiAmb1SynchDelay IntrLiAmb1TargetTransitionTime IntrLiAmb1Trigger IntrLiAmb1Update;
SIG_GROUP_ 882 IntrLiAmb2 1 : IntrLiAmb2BnIngrd IntrLiAmb2GrnIngrd IntrLiAmb2Intensty IntrLiAmb2RedIngrd IntrLiAmb2SelCmd1 IntrLiAmb2SelCmd2 IntrLiAmb2SynchDelay IntrLiAmb2TargetTransitionTime IntrLiAmb2Trigger IntrLiAmb2Update;
SIG_GROUP_ 310 MirrPosnToSetTarPosnAtPass 1 : MirrPosnToSetTarPosnAtPassMirrPosnAdjCldLeRi MirrPosnToSetTarPosnAtPassMirrPosnAdjCldUpDwn;
SIG_GROUP_ 1184 OutdAirQly 1 : OutdAirQlyOutdAirQly OutdAirQlyQf;
SIG_GROUP_ 441 PassSeatCushDownPosPerc 1 : PassSeatCushDownPosPercSeatPosPerc PassSeatCushDownPosPercSeatPosQf;
SIG_GROUP_ 310 PassSeatPosFrntExtPerc 1 : PassSeatPosFrntExtPercSeatPosPerc PassSeatPosFrntExtPercSeatPosQf;
SIG_GROUP_ 441 PassSeatPosPerc 1 : PassSeatPosPercSeatPosFrntHeiPerc PassSeatPosPercSeatPosFrntHeiQF PassSeatPosPercSeatPosHeiPerc PassSeatPosPercSeatPosHeiQF PassSeatPosPercSeatPosSldPerc PassSeatPosPercSeatPosSldQF;
SIG_GROUP_ 451 PassSeatSwtSts2 1 : PassSeatSwtSts2PassSeatSwtAdjmtOfSpplFctHozlSts PassSeatSwtSts2PassSeatSwtAdjmtOfSpplFctVerSts PassSeatSwtSts2PassSeatSwtHdrstHozlSts PassSeatSwtSts2PassSeatSwtHdrstVertSts PassSeatSwtSts2PassSeatSwtHeiFrntSts PassSeatSwtSts2PassSeatSwtHeiSts PassSeatSwtSts2PassSeatSwtInclSts PassSeatSwtSts2PassSeatSwtSelnOfSpplFctStsSts PassSeatSwtSts2PassSeatSwtSldSts;
SIG_GROUP_ 803 ReHvacHexAirT 1 : ReHvacHexAirTHvacAirTForHeatrFrnt ReHvacHexAirTHvacAirTForHeatrFrntQf;
SIG_GROUP_ 600 SeatClimaDurgClima 1 : SeatClimaDurgClimaHmiSeatHeatgForRowFirstLe SeatClimaDurgClimaHmiSeatHeatgForRowFirstRi SeatClimaDurgClimaHmiSeatHeatgForRowSecLe SeatClimaDurgClimaHmiSeatHeatgForRowSecRi SeatClimaDurgClimaHmiSeatVentnForRowFirstLe SeatClimaDurgClimaHmiSeatVentnForRowFirstRi SeatClimaDurgClimaHmiSeatVentnForRowSecLe SeatClimaDurgClimaHmiSeatVentnForRowSecRi;
SIG_GROUP_ 1350 VFCVectorZCUP 1 : VFCVectorZCUPBlockID VFCVectorZCUPVFCid0 VFCVectorZCUPVFCid1 VFCVectorZCUPVFCid10 VFCVectorZCUPVFCid11 VFCVectorZCUPVFCid12 VFCVectorZCUPVFCid13 VFCVectorZCUPVFCid14 VFCVectorZCUPVFCid15 VFCVectorZCUPVFCid16 VFCVectorZCUPVFCid17 VFCVectorZCUPVFCid18 VFCVectorZCUPVFCid19 VFCVectorZCUPVFCid2 VFCVectorZCUPVFCid20 VFCVectorZCUPVFCid21 VFCVectorZCUPVFCid22 VFCVectorZCUPVFCid23 VFCVectorZCUPVFCid24 VFCVectorZCUPVFCid25 VFCVectorZCUPVFCid26 VFCVectorZCUPVFCid27 VFCVectorZCUPVFCid28 VFCVectorZCUPVFCid29 VFCVectorZCUPVFCid3 VFCVectorZCUPVFCid30 VFCVectorZCUPVFCid31 VFCVectorZCUPVFCid32 VFCVectorZCUPVFCid33 VFCVectorZCUPVFCid34 VFCVectorZCUPVFCid35 VFCVectorZCUPVFCid36 VFCVectorZCUPVFCid37 VFCVectorZCUPVFCid38 VFCVectorZCUPVFCid39 VFCVectorZCUPVFCid4 VFCVectorZCUPVFCid40 VFCVectorZCUPVFCid41 VFCVectorZCUPVFCid42 VFCVectorZCUPVFCid43 VFCVectorZCUPVFCid44 VFCVectorZCUPVFCid45 VFCVectorZCUPVFCid46 VFCVectorZCUPVFCid47 VFCVectorZCUPVFCid48 VFCVectorZCUPVFCid49 VFCVectorZCUPVFCid5 VFCVectorZCUPVFCid50 VFCVectorZCUPVFCid51 VFCVectorZCUPVFCid52 VFCVectorZCUPVFCid53 VFCVectorZCUPVFCid54 VFCVectorZCUPVFCid55 VFCVectorZCUPVFCid56 VFCVectorZCUPVFCid57 VFCVectorZCUPVFCid58 VFCVectorZCUPVFCid59 VFCVectorZCUPVFCid6 VFCVectorZCUPVFCid60 VFCVectorZCUPVFCid61 VFCVectorZCUPVFCid7 VFCVectorZCUPVFCid8 VFCVectorZCUPVFCid9;
